VERSION "HNNBNNNYNNNNNNNNNNNNNNNNNNNNNNNNNNNNNNNNNN/4/%%%/4/'%**4NNN///"

NS_ :

BS_:

BU_: BAP_Tester BCM Gateway_Max TSGGen3_BFS TSGGen3_FS TSGGen3_HBFS TSGGen3_HFS WLC_01_CFD

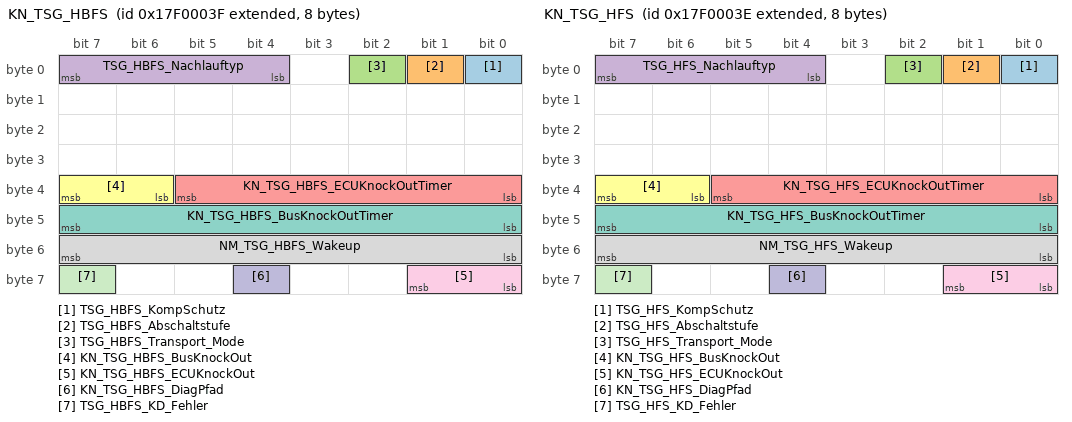
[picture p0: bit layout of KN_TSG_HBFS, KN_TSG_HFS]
BO_ 2549088319 KN_TSG_HBFS: 8 TSGGen3_HBFS
 SG_ TSG_HBFS_KompSchutz : 0|1@1+ (1.0,0.0) [0.0|1] ""  Vector__XXX
 SG_ TSG_HBFS_Abschaltstufe : 1|1@1+ (1.0,0.0) [0.0|1] ""  Vector__XXX
 SG_ TSG_HBFS_Transport_Mode : 2|1@1+ (1.0,0.0) [0.0|1] ""  Vector__XXX
 SG_ TSG_HBFS_Nachlauftyp : 4|4@1+ (1.0,0.0) [0.0|15] ""  Gateway_Max
 SG_ KN_TSG_HBFS_ECUKnockOutTimer : 32|6@1+ (1,0) [0|62] ""  Vector__XXX
 SG_ KN_TSG_HBFS_BusKnockOut : 38|2@1+ (1.0,0.0) [0.0|3] ""  Vector__XXX
 SG_ KN_TSG_HBFS_BusKnockOutTimer : 40|8@1+ (1,0) [0|254] ""  Vector__XXX
 SG_ NM_TSG_HBFS_Wakeup : 48|8@1+ (1.0,0.0) [0.0|255] ""  Vector__XXX
 SG_ KN_TSG_HBFS_ECUKnockOut : 56|2@1+ (1.0,0.0) [0.0|3] ""  Vector__XXX
 SG_ KN_TSG_HBFS_DiagPfad : 60|1@1+ (1.0,0.0) [0.0|1] ""  Gateway_Max
 SG_ TSG_HBFS_KD_Fehler : 63|1@1+ (1.0,0.0) [0.0|1] ""  Gateway_Max

BO_ 2549088318 KN_TSG_HFS: 8 TSGGen3_HFS
 SG_ TSG_HFS_KompSchutz : 0|1@1+ (1.0,0.0) [0.0|1] ""  Vector__XXX
 SG_ TSG_HFS_Abschaltstufe : 1|1@1+ (1.0,0.0) [0.0|1] ""  Vector__XXX
 SG_ TSG_HFS_Transport_Mode : 2|1@1+ (1.0,0.0) [0.0|1] ""  Vector__XXX
 SG_ TSG_HFS_Nachlauftyp : 4|4@1+ (1.0,0.0) [0.0|15] ""  Gateway_Max
 SG_ KN_TSG_HFS_ECUKnockOutTimer : 32|6@1+ (1,0) [0|62] ""  Vector__XXX
 SG_ KN_TSG_HFS_BusKnockOut : 38|2@1+ (1.0,0.0) [0.0|3] ""  Vector__XXX
 SG_ KN_TSG_HFS_BusKnockOutTimer : 40|8@1+ (1,0) [0|254] ""  Vector__XXX
 SG_ NM_TSG_HFS_Wakeup : 48|8@1+ (1.0,0.0) [0.0|255] ""  Vector__XXX
 SG_ KN_TSG_HFS_ECUKnockOut : 56|2@1+ (1.0,0.0) [0.0|3] ""  Vector__XXX
 SG_ KN_TSG_HFS_DiagPfad : 60|1@1+ (1.0,0.0) [0.0|1] ""  Gateway_Max
 SG_ TSG_HFS_KD_Fehler : 63|1@1+ (1.0,0.0) [0.0|1] ""  Gateway_Max

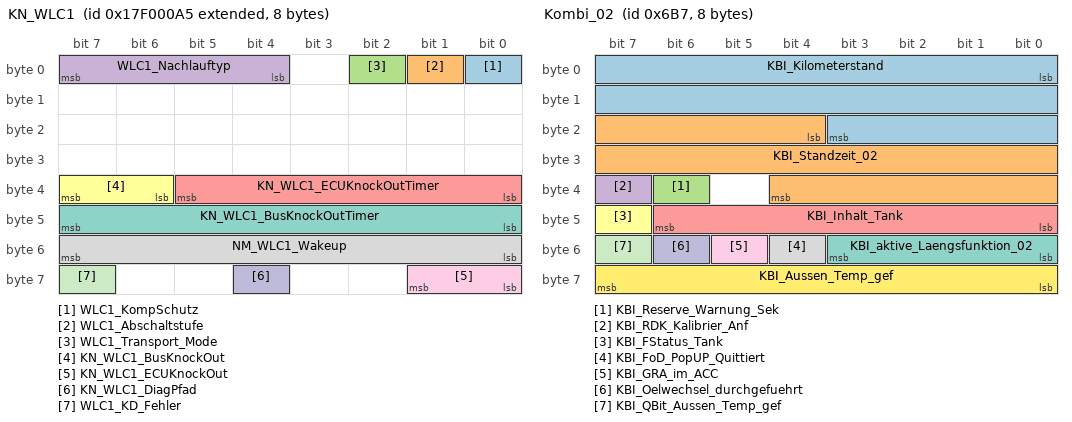
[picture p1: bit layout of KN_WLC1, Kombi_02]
BO_ 2549088421 KN_WLC1: 8 WLC_01_CFD
 SG_ WLC1_KompSchutz : 0|1@1+ (1.0,0.0) [0.0|1] ""  Vector__XXX
 SG_ WLC1_Abschaltstufe : 1|1@1+ (1.0,0.0) [0.0|1] ""  Vector__XXX
 SG_ WLC1_Transport_Mode : 2|1@1+ (1.0,0.0) [0.0|1] ""  Vector__XXX
 SG_ WLC1_Nachlauftyp : 4|4@1+ (1.0,0.0) [0.0|15] ""  Gateway_Max
 SG_ KN_WLC1_ECUKnockOutTimer : 32|6@1+ (1,0) [0|62] "Unit_Minut"  Vector__XXX
 SG_ KN_WLC1_BusKnockOut : 38|2@1+ (1.0,0.0) [0.0|3] ""  Vector__XXX
 SG_ KN_WLC1_BusKnockOutTimer : 40|8@1+ (1,0) [0|254] "Unit_Minut"  Vector__XXX
 SG_ NM_WLC1_Wakeup : 48|8@1+ (1.0,0.0) [0.0|255] ""  Vector__XXX
 SG_ KN_WLC1_ECUKnockOut : 56|2@1+ (1.0,0.0) [0.0|3] ""  Vector__XXX
 SG_ KN_WLC1_DiagPfad : 60|1@1+ (1.0,0.0) [0.0|1] ""  Gateway_Max
 SG_ WLC1_KD_Fehler : 63|1@1+ (1.0,0.0) [0.0|1] ""  Gateway_Max

BO_ 779 Kombi_01: 8 Gateway_Max
 SG_ KBI_ABS_Lampe : 0|1@1+ (1.0,0.0) [0.0|1] ""  BCM
 SG_ KBI_ESP_Lampe : 1|1@1+ (1.0,0.0) [0.0|1] ""  BCM
 SG_ KBI_BKL_Lampe : 2|1@1+ (1.0,0.0) [0.0|1] ""  BCM
 SG_ KBI_Airbag_Lampe : 3|1@1+ (1.0,0.0) [0.0|1] ""  BCM
 SG_ KBI_SILA_gueltig : 4|1@1+ (1.0,0.0) [0.0|1] ""  BCM
 SG_ KBI_Lenkung_Lampe : 5|1@1+ (1,0) [0|1] ""  BCM
 SG_ KBI_Vorglueh_System_Lampe : 6|1@1+ (1.0,0.0) [0.0|1] ""  BCM
 SG_ KBI_NV_in_Anzeige : 7|1@1+ (1.0,0.0) [0.0|1] ""  BCM
 SG_ Kombi_01_BZ : 8|4@1+ (1,0) [0|15] ""  BCM
 SG_ KBI_Anzeigestatus_ACC : 12|1@1+ (1.0,0.0) [0.0|1] ""  BCM
 SG_ KBI_Anzeigestatus_GRA : 13|2@1+ (1.0,0.0) [0.0|3] ""  BCM
 SG_ KBI_Oeldruck_Schalter : 15|1@1+ (1.0,0.0) [0.0|1] ""  BCM
 SG_ KBI_Tankwarnung : 16|1@1+ (1.0,0.0) [0.0|1] ""  BCM
 SG_ KBI_MFA_v_Einheit_01 : 17|1@1+ (1.0,0.0) [0.0|1] ""  BCM
 SG_ KBI_im_Stellgliedtest : 18|1@1+ (1.0,0.0) [0.0|1] ""  BCM
 SG_ KBI_Anzeigefehler_LDW : 19|2@1+ (1.0,0.0) [0.0|3] ""  BCM
 SG_ KBI_Tankwarnung_ungueltig : 21|1@1+ (1.0,0.0) [0.0|1] ""  BCM
 SG_ KBI_Oeldruckwarnung : 22|1@1+ (1.0,0.0) [0.0|1] ""  BCM
 SG_ KBI_Handbremse : 23|1@1+ (1.0,0.0) [0.0|1] ""  BCM
 SG_ KBI_V_Digital : 24|9@1+ (1,0) [0|511] ""  BCM
 SG_ KBI_PLA_in_Anzeige : 33|1@1+ (1.0,0.0) [0.0|1] ""  BCM
 SG_ KBI_Anzeigefehler_NV : 34|1@1+ (1.0,0.0) [0.0|1] ""  BCM
 SG_ KBI_Anzeigestatus_LIM : 35|2@1+ (1.0,0.0) [0.0|3] ""  BCM
 SG_ KBI_ARA_in_Anzeige : 37|1@1+ (1.0,0.0) [0.0|1] ""  BCM
 SG_ KBI_Taster_Lift : 38|1@1+ (1.0,0.0) [0.0|1] ""  BCM
 SG_ KBI_Taster_Fahrwerk : 39|1@1+ (1.0,0.0) [0.0|1] ""  BCM
 SG_ KBI_Audioabsenkung_MIB : 40|2@1+ (1.0,0.0) [0.0|3] ""  BCM
 SG_ KBI_Bestaetigung_ESP_Off : 42|2@1+ (1.0,0.0) [0.0|3] ""  BCM
 SG_ KBI_Anzeigestatus_RHP : 44|2@1+ (1.0,0.0) [0.0|3] ""  BCM
 SG_ KBI_angez_Geschw : 48|10@1+ (0.32,0) [0.00|325.12] "Unit_KiloMeterPerHour"  BCM
 SG_ KBI_Konsistenz_ACC : 59|1@1+ (1.0,0.0) [0.0|1] ""  BCM
 SG_ KBI_Fehler_Anzeige_ACC : 60|1@1+ (1.0,0.0) [0.0|1] ""  BCM
 SG_ KBI_Anzeigefehler_SWA : 61|2@1+ (1.0,0.0) [0.0|3] ""  BCM
 SG_ KBI_Systemstatus : 63|1@1+ (1.0,0.0) [0.0|1] ""  BCM

BO_ 1719 Kombi_02: 8 Gateway_Max
 SG_ KBI_Kilometerstand : 0|20@1+ (1,0) [0|1048573] "Unit_KiloMeter"  BCM
 SG_ KBI_Standzeit_02 : 20|17@1+ (1,0) [0|131068] "Unit_Secon"  BCM
 SG_ KBI_Reserve_Warnung_Sek : 38|1@1+ (1.0,0.0) [0.0|1] ""  BCM
 SG_ KBI_RDK_Kalibrier_Anf : 39|1@1+ (1.0,0.0) [0.0|1] ""  BCM
 SG_ KBI_Inhalt_Tank : 40|7@1+ (1,0) [0|125] "Unit_Liter"  BCM
 SG_ KBI_FStatus_Tank : 47|1@1+ (1.0,0.0) [0.0|1] ""  BCM
 SG_ KBI_aktive_Laengsfunktion_02 : 48|4@1+ (1.0,0.0) [0.0|15] ""  BCM
 SG_ KBI_FoD_PopUP_Quittiert : 52|1@1+ (1.0,0.0) [0.0|1] ""  BCM
 SG_ KBI_GRA_im_ACC : 53|1@1+ (1.0,0.0) [0.0|1] ""  BCM
 SG_ KBI_Oelwechsel_durchgefuehrt : 54|1@1+ (1.0,0.0) [0.0|1] ""  BCM
 SG_ KBI_QBit_Aussen_Temp_gef : 55|1@1+ (1.0,0.0) [0.0|1] ""  BCM,TSGGen3_BFS,TSGGen3_FS,TSGGen3_HBFS,TSGGen3_HFS
 SG_ KBI_Aussen_Temp_gef : 56|8@1+ (0.5,-50) [-50.0|75.0] "Unit_DegreCelsi"  BCM,TSGGen3_BFS,TSGGen3_FS,TSGGen3_HBFS,TSGGen3_HFS

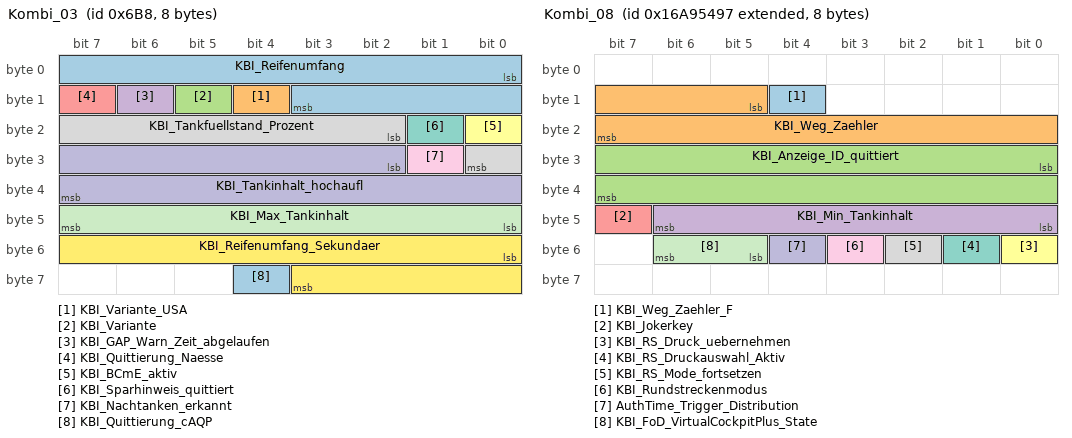
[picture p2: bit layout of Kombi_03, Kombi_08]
BO_ 1720 Kombi_03: 8 Gateway_Max
 SG_ KBI_Reifenumfang : 0|12@1+ (1,0) [0|4095] "Unit_MilliMeter"  BCM
 SG_ KBI_Variante_USA : 12|1@1+ (1.0,0.0) [0.0|1] ""  Vector__XXX
 SG_ KBI_Variante : 13|1@1+ (1.0,0.0) [0.0|1] ""  Vector__XXX
 SG_ KBI_GAP_Warn_Zeit_abgelaufen : 14|1@1+ (1.0,0.0) [0.0|1] ""  Vector__XXX
 SG_ KBI_Quittierung_Naesse : 15|1@1+ (1.0,0.0) [0.0|1] ""  Vector__XXX
 SG_ KBI_BCmE_aktiv : 16|1@1+ (1.0,0.0) [0.0|1] ""  Vector__XXX
 SG_ KBI_Sparhinweis_quittiert : 17|1@1+ (1.0,0.0) [0.0|1] ""  Vector__XXX
 SG_ KBI_Tankfuellstand_Prozent : 18|7@1+ (1,0) [0|100] "Unit_PerCent"  Vector__XXX
 SG_ KBI_Nachtanken_erkannt : 25|1@1+ (1.0,0.0) [0.0|1] ""  Vector__XXX
 SG_ KBI_Tankinhalt_hochaufl : 26|14@1+ (0.01,0) [0.00|163.81] "Unit_Liter"  Vector__XXX
 SG_ KBI_Max_Tankinhalt : 40|8@1+ (0.5,0) [0.0|126.5] ""  Vector__XXX
 SG_ KBI_Reifenumfang_Sekundaer : 48|12@1+ (1,0) [0|4095] "Unit_MilliMeter"  Vector__XXX
 SG_ KBI_Quittierung_cAQP : 60|1@1+ (1.0,0.0) [0.0|1] ""  Vector__XXX

BO_ 1722 Kombi_03_SOK_Signatur: 8 Gateway_Max
 SG_ SOK_Kombi_03_Signatur : 0|64@1+ (1,0) [0|18446744073709551615] "Unit_None"  BCM

BO_ 2527679639 Kombi_08: 8 Gateway_Max
 SG_ KBI_Weg_Zaehler_F : 12|1@1+ (1.0,0.0) [0.0|1] ""  BCM
 SG_ KBI_Weg_Zaehler : 13|11@1+ (1,0) [0|2047] "Unit_Meter"  BCM
 SG_ KBI_Anzeige_ID_quittiert : 24|16@1+ (1,0) [1|65336] "Unit_None"  BCM
 SG_ KBI_Min_Tankinhalt : 40|7@1+ (0.1,0) [0.0|12.5] "Unit_Liter"  BCM
 SG_ KBI_Jokerkey : 47|1@1+ (1.0,0.0) [0.0|1] ""  BCM
 SG_ KBI_RS_Druck_uebernehmen : 48|1@1+ (1.0,0.0) [0.0|1] ""  BCM
 SG_ KBI_RS_Druckauswahl_Aktiv : 49|1@1+ (1.0,0.0) [0.0|1] ""  BCM
 SG_ KBI_RS_Mode_fortsetzen : 50|1@1+ (1.0,0.0) [0.0|1] ""  BCM
 SG_ KBI_Rundstreckenmodus : 51|1@1+ (1.0,0.0) [0.0|1] ""  BCM
 SG_ AuthTime_Trigger_Distribution : 52|1@1+ (1.0,0.0) [0.0|1] ""  BCM
 SG_ KBI_FoD_VirtualCockpitPlus_State : 53|2@1+ (1.0,0.0) [0.0|3] ""  BCM

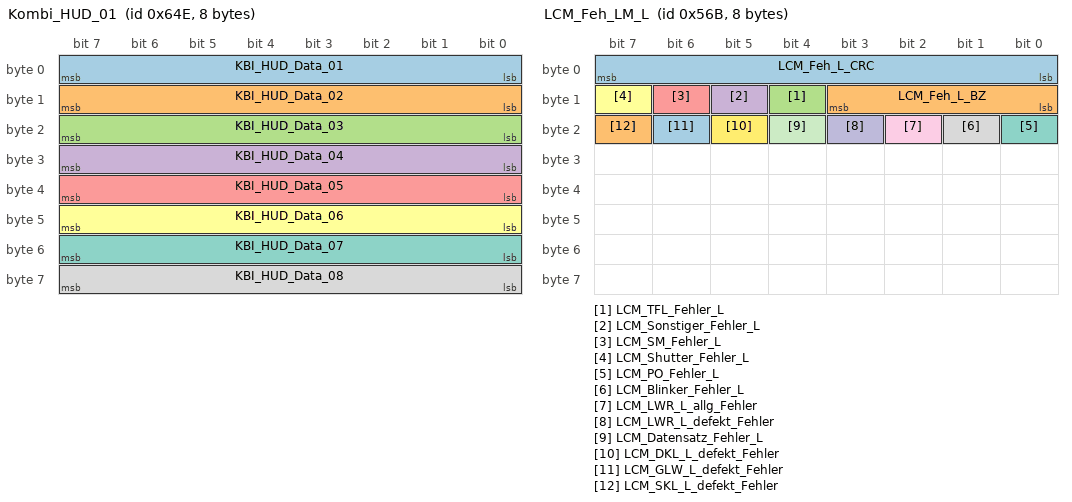
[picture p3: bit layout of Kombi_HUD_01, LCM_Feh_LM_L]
BO_ 1614 Kombi_HUD_01: 8 Gateway_Max
 SG_ KBI_HUD_Data_01 : 0|8@1+ (1.0,0.0) [0.0|255] ""  BCM
 SG_ KBI_HUD_Data_02 : 8|8@1+ (1.0,0.0) [0.0|255] ""  BCM
 SG_ KBI_HUD_Data_03 : 16|8@1+ (1.0,0.0) [0.0|255] ""  BCM
 SG_ KBI_HUD_Data_04 : 24|8@1+ (1.0,0.0) [0.0|255] ""  BCM
 SG_ KBI_HUD_Data_05 : 32|8@1+ (1.0,0.0) [0.0|255] ""  BCM
 SG_ KBI_HUD_Data_06 : 40|8@1+ (1.0,0.0) [0.0|255] ""  BCM
 SG_ KBI_HUD_Data_07 : 48|8@1+ (1.0,0.0) [0.0|255] ""  BCM
 SG_ KBI_HUD_Data_08 : 56|8@1+ (1.0,0.0) [0.0|255] ""  BCM

BO_ 2621440270 KS_BCM1_Req_FD: 16 Gateway_Max
 SG_ KS_BCM1_Req_FD_Data : 0|128@1+ (1.0,0.0) [0.0|340282366920938463463374607431768211455] ""  BCM

BO_ 2621571342 KS_BCM1_Resp_FD: 16 BCM
 SG_ KS_BCM1_Resp_FD_Data : 0|128@1+ (1.0,0.0) [0.0|340282366920938463463374607431768211455] ""  Gateway_Max

BO_ 1387 LCM_Feh_LM_L: 8 Gateway_Max
 SG_ LCM_Feh_L_CRC : 0|8@1+ (1,0) [0|255] ""  Vector__XXX
 SG_ LCM_Feh_L_BZ : 8|4@1+ (1,0) [0|15] ""  Vector__XXX
 SG_ LCM_TFL_Fehler_L : 12|1@1+ (1.0,0.0) [0.0|1] ""  BCM
 SG_ LCM_Sonstiger_Fehler_L : 13|1@1+ (1.0,0.0) [0.0|1] ""  BCM
 SG_ LCM_SM_Fehler_L : 14|1@1+ (1.0,0.0) [0.0|1] ""  BCM
 SG_ LCM_Shutter_Fehler_L : 15|1@1+ (1.0,0.0) [0.0|1] ""  BCM
 SG_ LCM_PO_Fehler_L : 16|1@1+ (1.0,0.0) [0.0|1] ""  BCM
 SG_ LCM_Blinker_Fehler_L : 17|1@1+ (1.0,0.0) [0.0|1] ""  BCM
 SG_ LCM_LWR_L_allg_Fehler : 18|1@1+ (1.0,0.0) [0.0|1] ""  BCM
 SG_ LCM_LWR_L_defekt_Fehler : 19|1@1+ (1.0,0.0) [0.0|1] ""  BCM
 SG_ LCM_Datensatz_Fehler_L : 20|1@1+ (1.0,0.0) [0.0|1] ""  BCM
 SG_ LCM_DKL_L_defekt_Fehler : 21|1@1+ (1.0,0.0) [0.0|1] ""  BCM
 SG_ LCM_GLW_L_defekt_Fehler : 22|1@1+ (1.0,0.0) [0.0|1] ""  BCM
 SG_ LCM_SKL_L_defekt_Fehler : 23|1@1+ (1.0,0.0) [0.0|1] ""  BCM

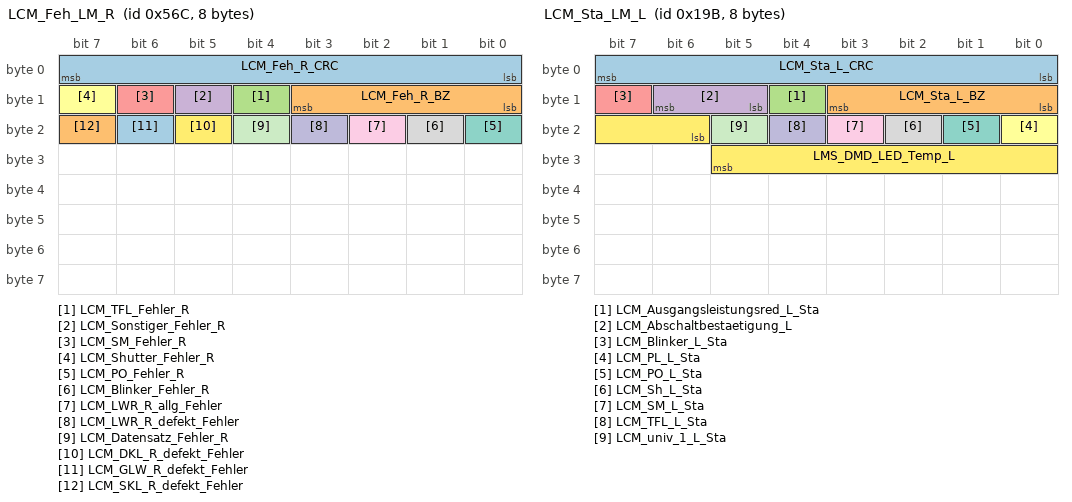
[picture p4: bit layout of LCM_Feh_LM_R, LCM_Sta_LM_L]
BO_ 1388 LCM_Feh_LM_R: 8 Gateway_Max
 SG_ LCM_Feh_R_CRC : 0|8@1+ (1,0) [0|255] ""  Vector__XXX
 SG_ LCM_Feh_R_BZ : 8|4@1+ (1,0) [0|15] ""  Vector__XXX
 SG_ LCM_TFL_Fehler_R : 12|1@1+ (1.0,0.0) [0.0|1] ""  BCM
 SG_ LCM_Sonstiger_Fehler_R : 13|1@1+ (1.0,0.0) [0.0|1] ""  BCM
 SG_ LCM_SM_Fehler_R : 14|1@1+ (1.0,0.0) [0.0|1] ""  BCM
 SG_ LCM_Shutter_Fehler_R : 15|1@1+ (1.0,0.0) [0.0|1] ""  BCM
 SG_ LCM_PO_Fehler_R : 16|1@1+ (1.0,0.0) [0.0|1] ""  BCM
 SG_ LCM_Blinker_Fehler_R : 17|1@1+ (1.0,0.0) [0.0|1] ""  BCM
 SG_ LCM_LWR_R_allg_Fehler : 18|1@1+ (1.0,0.0) [0.0|1] ""  BCM
 SG_ LCM_LWR_R_defekt_Fehler : 19|1@1+ (1.0,0.0) [0.0|1] ""  BCM
 SG_ LCM_Datensatz_Fehler_R : 20|1@1+ (1.0,0.0) [0.0|1] ""  BCM
 SG_ LCM_DKL_R_defekt_Fehler : 21|1@1+ (1.0,0.0) [0.0|1] ""  BCM
 SG_ LCM_GLW_R_defekt_Fehler : 22|1@1+ (1.0,0.0) [0.0|1] ""  BCM
 SG_ LCM_SKL_R_defekt_Fehler : 23|1@1+ (1.0,0.0) [0.0|1] ""  BCM

BO_ 403 LCM_Soll_Fkt: 8 BCM
 SG_ LCM_Soll_CRC : 0|8@1+ (1,0) [0|255] ""  Gateway_Max
 SG_ LCM_Soll_BZ : 8|4@1+ (1,0) [0|15] ""  Gateway_Max
 SG_ LCM_TFL_L_Anf : 12|1@1+ (1.0,0.0) [0.0|1] ""  Gateway_Max
 SG_ LCM_TFL_R_Anf : 13|1@1+ (1.0,0.0) [0.0|1] ""  Gateway_Max
 SG_ LCM_Abschaltung_Vbat_L_Anf : 14|1@1+ (1.0,0.0) [0.0|1] ""  Gateway_Max
 SG_ LCM_Abschaltung_Vbat_R_Anf : 15|1@1+ (1.0,0.0) [0.0|1] ""  Gateway_Max
 SG_ LCM_Blinker_L_Anf : 16|1@1+ (1.0,0.0) [0.0|1] ""  Gateway_Max
 SG_ LCM_Blinker_R_Anf : 17|1@1+ (1.0,0.0) [0.0|1] ""  Gateway_Max
 SG_ LCM_Blinkerzyklus_L : 18|1@1+ (1.0,0.0) [0.0|1] ""  Gateway_Max
 SG_ LCM_Blinkerzyklus_R : 19|1@1+ (1.0,0.0) [0.0|1] ""  Gateway_Max
 SG_ LCM_Sh_L_Anf : 20|1@1+ (1.0,0.0) [0.0|1] ""  Gateway_Max
 SG_ LCM_Sh_R_Anf : 21|1@1+ (1.0,0.0) [0.0|1] ""  Gateway_Max
 SG_ LCM_SM_L_Anf : 22|1@1+ (1.0,0.0) [0.0|1] ""  Gateway_Max
 SG_ LCM_SM_R_Anf : 23|1@1+ (1.0,0.0) [0.0|1] ""  Gateway_Max
 SG_ LCM_univ_1_L_Anf : 24|1@1+ (1.0,0.0) [0.0|1] ""  Gateway_Max
 SG_ LCM_univ_1_R_Anf : 25|1@1+ (1.0,0.0) [0.0|1] ""  Gateway_Max
 SG_ LCM_PO_L_Anf : 28|1@1+ (1.0,0.0) [0.0|1] ""  Gateway_Max
 SG_ LCM_PO_R_Anf : 29|1@1+ (1.0,0.0) [0.0|1] ""  Gateway_Max
 SG_ LCM_PL_L_Anf : 30|1@1+ (1.0,0.0) [0.0|1] ""  Gateway_Max
 SG_ LCM_PL_R_Anf : 31|1@1+ (1.0,0.0) [0.0|1] ""  Gateway_Max
 SG_ LCM_Leistungsreduzierung_Anf : 32|2@1+ (1.0,0.0) [0.0|3] ""  Gateway_Max
 SG_ BCM1_FoD_Sperrung_AnimTFL : 34|1@1+ (1.0,0.0) [0.0|1] ""  Gateway_Max
 SG_ LCM_Blinkerwischen_Anf : 35|1@1+ (1.0,0.0) [0.0|1] ""  Gateway_Max
 SG_ LCM_Animiertes_TFL_Anf : 36|1@1+ (1.0,0.0) [0.0|1] ""  Gateway_Max
 SG_ LCM_Signaturlicht_Anf : 39|1@1+ (1.0,0.0) [0.0|1] ""  Gateway_Max
 SG_ LCM_ECE_SAE_Umschaltung_Anf : 41|1@1+ (1.0,0.0) [0.0|1] ""  Gateway_Max
 SG_ BM_Autobahn : 42|1@1+ (1.0,0.0) [0.0|1] ""  Gateway_Max
 SG_ BM_ZV_auf : 43|1@1+ (1.0,0.0) [0.0|1] ""  Gateway_Max
 SG_ BM_ZV_zu : 44|1@1+ (1.0,0.0) [0.0|1] ""  Gateway_Max
 SG_ BCM1_CH_aktiv : 45|1@1+ (1.0,0.0) [0.0|1] ""  Gateway_Max
 SG_ BCM1_LH_aktiv : 46|1@1+ (1.0,0.0) [0.0|1] ""  Gateway_Max
 SG_ LCM_TFL_Signatur_Anf : 48|4@1+ (1.0,0.0) [0.0|15] ""  Gateway_Max
 SG_ LCM_Designlicht_4 : 52|1@1+ (1.0,0.0) [0.0|1] ""  Gateway_Max
 SG_ LCM_Designlicht_5 : 53|1@1+ (1.0,0.0) [0.0|1] ""  Gateway_Max
 SG_ AMBEX_CH_aktiv : 54|1@1+ (1.0,0.0) [0.0|1] ""  Gateway_Max
 SG_ AMBEX_CH_Trigger : 55|1@1+ (1.0,0.0) [0.0|1] ""  Gateway_Max
 SG_ AMBEX_LH_aktiv : 56|1@1+ (1.0,0.0) [0.0|1] ""  Gateway_Max
 SG_ AMBEX_LH_Trigger : 57|1@1+ (1.0,0.0) [0.0|1] ""  Gateway_Max

BO_ 411 LCM_Sta_LM_L: 8 Gateway_Max
 SG_ LCM_Sta_L_CRC : 0|8@1+ (1,0) [0|255] ""  BCM
 SG_ LCM_Sta_L_BZ : 8|4@1+ (1,0) [0|15] ""  BCM
 SG_ LCM_Ausgangsleistungsred_L_Sta : 12|1@1+ (1.0,0.0) [0.0|1] ""  BCM
 SG_ LCM_Abschaltbestaetigung_L : 13|2@1+ (1.0,0.0) [0.0|3] ""  BCM
 SG_ LCM_Blinker_L_Sta : 15|1@1+ (1.0,0.0) [0.0|1] ""  BCM
 SG_ LCM_PL_L_Sta : 16|1@1+ (1.0,0.0) [0.0|1] ""  BCM
 SG_ LCM_PO_L_Sta : 17|1@1+ (1.0,0.0) [0.0|1] ""  BCM
 SG_ LCM_Sh_L_Sta : 18|1@1+ (1.0,0.0) [0.0|1] ""  BCM
 SG_ LCM_SM_L_Sta : 19|1@1+ (1.0,0.0) [0.0|1] ""  BCM
 SG_ LCM_TFL_L_Sta : 20|1@1+ (1.0,0.0) [0.0|1] ""  BCM
 SG_ LCM_univ_1_L_Sta : 21|1@1+ (1.0,0.0) [0.0|1] ""  BCM
 SG_ LMS_DMD_LED_Temp_L : 22|8@1+ (1,-50) [-50|204] "Unit_DegreCelsi"  BCM

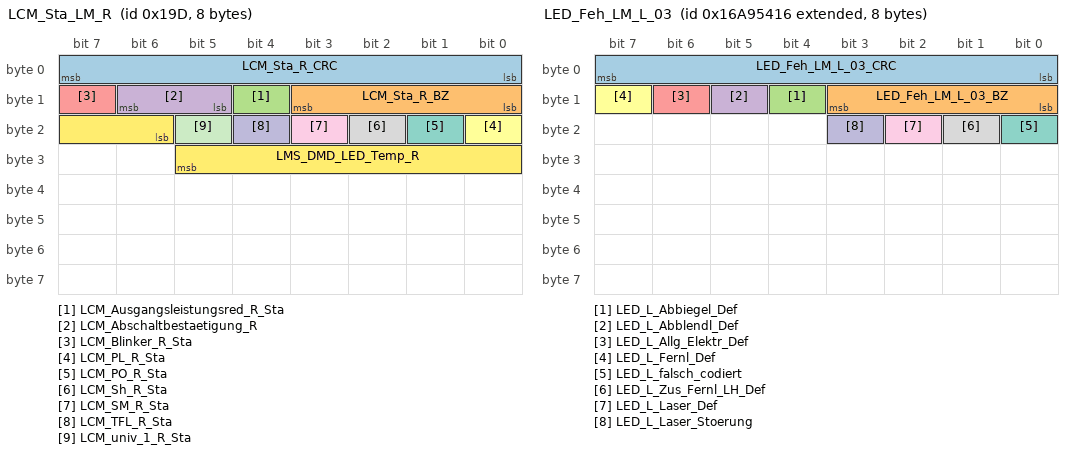
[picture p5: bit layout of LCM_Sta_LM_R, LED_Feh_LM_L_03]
BO_ 413 LCM_Sta_LM_R: 8 Gateway_Max
 SG_ LCM_Sta_R_CRC : 0|8@1+ (1,0) [0|255] ""  BCM
 SG_ LCM_Sta_R_BZ : 8|4@1+ (1,0) [0|15] ""  BCM
 SG_ LCM_Ausgangsleistungsred_R_Sta : 12|1@1+ (1.0,0.0) [0.0|1] ""  BCM
 SG_ LCM_Abschaltbestaetigung_R : 13|2@1+ (1.0,0.0) [0.0|3] ""  BCM
 SG_ LCM_Blinker_R_Sta : 15|1@1+ (1.0,0.0) [0.0|1] ""  BCM
 SG_ LCM_PL_R_Sta : 16|1@1+ (1.0,0.0) [0.0|1] ""  BCM
 SG_ LCM_PO_R_Sta : 17|1@1+ (1.0,0.0) [0.0|1] ""  BCM
 SG_ LCM_Sh_R_Sta : 18|1@1+ (1.0,0.0) [0.0|1] ""  BCM
 SG_ LCM_SM_R_Sta : 19|1@1+ (1.0,0.0) [0.0|1] ""  BCM
 SG_ LCM_TFL_R_Sta : 20|1@1+ (1.0,0.0) [0.0|1] ""  BCM
 SG_ LCM_univ_1_R_Sta : 21|1@1+ (1.0,0.0) [0.0|1] ""  BCM
 SG_ LMS_DMD_LED_Temp_R : 22|8@1+ (1,-50) [-50|204] "Unit_DegreCelsi"  BCM

BO_ 2527679510 LED_Feh_LM_L_03: 8 Gateway_Max
 SG_ LED_Feh_LM_L_03_CRC : 0|8@1+ (1,0) [0|255] ""  Vector__XXX
 SG_ LED_Feh_LM_L_03_BZ : 8|4@1+ (1,0) [0|15] ""  Vector__XXX
 SG_ LED_L_Abbiegel_Def : 12|1@1+ (1.0,0.0) [0.0|1] ""  BCM
 SG_ LED_L_Abblendl_Def : 13|1@1+ (1.0,0.0) [0.0|1] ""  BCM
 SG_ LED_L_Allg_Elektr_Def : 14|1@1+ (1.0,0.0) [0.0|1] ""  BCM
 SG_ LED_L_Fernl_Def : 15|1@1+ (1.0,0.0) [0.0|1] ""  BCM
 SG_ LED_L_falsch_codiert : 16|1@1+ (1,0) [0|1] ""  BCM
 SG_ LED_L_Zus_Fernl_LH_Def : 17|1@1+ (1.0,0.0) [0.0|1] ""  BCM
 SG_ LED_L_Laser_Def : 18|1@1+ (1.0,0.0) [0.0|1] ""  BCM
 SG_ LED_L_Laser_Stoerung : 19|1@1+ (1.0,0.0) [0.0|1] ""  Vector__XXX

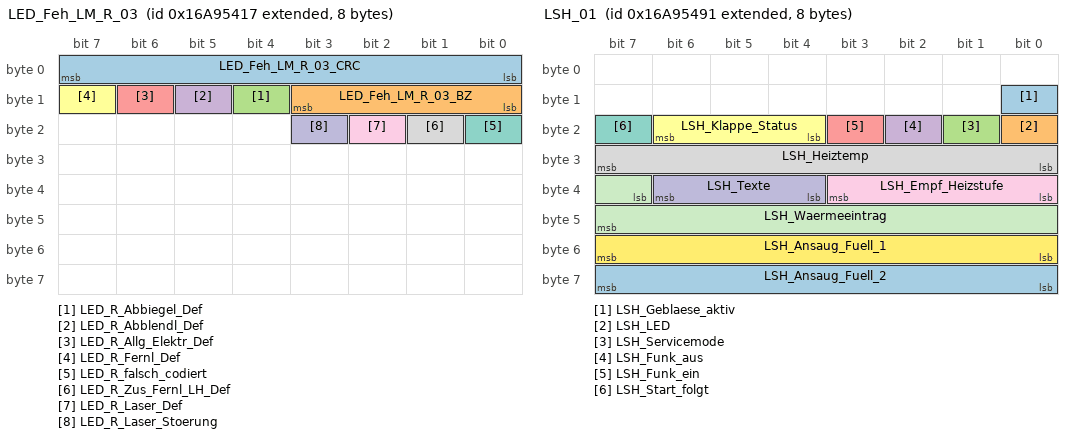
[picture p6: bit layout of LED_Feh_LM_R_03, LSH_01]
BO_ 2527679511 LED_Feh_LM_R_03: 8 Gateway_Max
 SG_ LED_Feh_LM_R_03_CRC : 0|8@1+ (1,0) [0|255] ""  Vector__XXX
 SG_ LED_Feh_LM_R_03_BZ : 8|4@1+ (1,0) [0|15] ""  Vector__XXX
 SG_ LED_R_Abbiegel_Def : 12|1@1+ (1.0,0.0) [0.0|1] ""  BCM
 SG_ LED_R_Abblendl_Def : 13|1@1+ (1.0,0.0) [0.0|1] ""  BCM
 SG_ LED_R_Allg_Elektr_Def : 14|1@1+ (1.0,0.0) [0.0|1] ""  BCM
 SG_ LED_R_Fernl_Def : 15|1@1+ (1.0,0.0) [0.0|1] ""  BCM
 SG_ LED_R_falsch_codiert : 16|1@1+ (1,0) [0|1] ""  BCM
 SG_ LED_R_Zus_Fernl_LH_Def : 17|1@1+ (1.0,0.0) [0.0|1] ""  BCM
 SG_ LED_R_Laser_Def : 18|1@1+ (1.0,0.0) [0.0|1] ""  BCM
 SG_ LED_R_Laser_Stoerung : 19|1@1+ (1.0,0.0) [0.0|1] ""  Vector__XXX

BO_ 981 Licht_Anf_01: 8 BCM
 SG_ Licht_Anf_01_CRC : 0|8@1+ (1,0) [0|255] ""  Gateway_Max
 SG_ Licht_Anf_01_BZ : 8|4@1+ (1,0) [0|15] ""  Gateway_Max
 SG_ BCM1_Kurvenlicht_links_Anf : 12|1@1+ (1.0,0.0) [0.0|1] ""  Gateway_Max
 SG_ BCM1_Kurvenlicht_rechts_Anf : 13|1@1+ (1.0,0.0) [0.0|1] ""  Gateway_Max
 SG_ BCM1_Standlicht_Anf : 14|1@1+ (1.0,0.0) [0.0|1] ""  Gateway_Max
 SG_ BCM1_Abblendlicht_Anf : 15|1@1+ (1.0,0.0) [0.0|1] ""  Gateway_Max
 SG_ BCM1_Fernlicht_Anf : 16|1@1+ (1.0,0.0) [0.0|1] ""  Gateway_Max
 SG_ BCM1_Nebellicht_Anf : 17|1@1+ (1.0,0.0) [0.0|1] ""  Gateway_Max
 SG_ BCM1_Parklicht_li_Anf : 18|1@1+ (1.0,0.0) [0.0|1] ""  Gateway_Max
 SG_ BCM1_Parklicht_re_Anf : 19|1@1+ (1.0,0.0) [0.0|1] ""  Gateway_Max
 SG_ BCM1_Nebelschluss_Ahg_Anf : 20|1@1+ (1.0,0.0) [0.0|1] ""  Gateway_Max
 SG_ BCM1_Nebelschluss_Fzg_Anf : 21|1@1+ (1.0,0.0) [0.0|1] ""  Gateway_Max
 SG_ BCM1_Schlusslicht_Anf : 22|1@1+ (1.0,0.0) [0.0|1] ""  Gateway_Max
 SG_ BCM_Rueckfahrlicht_Anf : 23|1@1+ (1.0,0.0) [0.0|1] ""  Gateway_Max,TSGGen3_BFS,TSGGen3_FS,TSGGen3_HBFS,TSGGen3_HFS
 SG_ BCM1_Signaturlicht_Anf : 24|1@1+ (1.0,0.0) [0.0|1] ""  Gateway_Max
 SG_ BCM1_Umfeldleuchten_Anf : 25|1@1+ (1.0,0.0) [0.0|1] ""  Gateway_Max,TSGGen3_BFS,TSGGen3_FS,TSGGen3_HBFS,TSGGen3_HFS
 SG_ BCM1_Tagfahrlicht_Anf : 26|1@1+ (1.0,0.0) [0.0|1] ""  Gateway_Max
 SG_ BCM1_Regenlicht_Anf : 27|1@1+ (1.0,0.0) [0.0|1] ""  Gateway_Max
 SG_ BCM1_Autobahnlicht_Anf : 28|1@1+ (1.0,0.0) [0.0|1] ""  Gateway_Max
 SG_ BCM1_Touristen_Licht_Anf : 29|1@1+ (1.0,0.0) [0.0|1] ""  Gateway_Max
 SG_ BCM1_CH_aktiv : 30|1@1+ (1.0,0.0) [0.0|1] ""  Gateway_Max
 SG_ BCM1_LH_aktiv : 31|1@1+ (1.0,0.0) [0.0|1] ""  Gateway_Max,TSGGen3_BFS,TSGGen3_FS,TSGGen3_HBFS,TSGGen3_HFS
 SG_ BCM1_Gleitende_Leuchtw_Anf : 32|1@1+ (1.0,0.0) [0.0|1] ""  Gateway_Max
 SG_ BCM1_GLW_Fernlicht_Anf : 33|1@1+ (1.0,0.0) [0.0|1] ""  Gateway_Max
 SG_ BCM1_Adaptive_Lichtvert_Anf : 34|1@1+ (1.0,0.0) [0.0|1] ""  Gateway_Max
 SG_ BCM1_Animationssperrung : 39|1@1+ (1.0,0.0) [0.0|1] ""  Gateway_Max
 SG_ BCM1_CH_LH_aktiv : 40|1@1+ (1.0,0.0) [0.0|1] ""  Gateway_Max
 SG_ BCM1_Allwetterlicht_Anf : 41|1@1+ (1.0,0.0) [0.0|1] ""  Gateway_Max
 SG_ TFL_Matrix_Variante01_Anf : 42|1@1+ (1.0,0.0) [0.0|1] ""  Gateway_Max
 SG_ TFL_Matrix_Variante02_Anf : 43|1@1+ (1.0,0.0) [0.0|1] ""  Gateway_Max
 SG_ TFL_Matrix_Variante03_Anf : 44|1@1+ (1.0,0.0) [0.0|1] ""  Gateway_Max
 SG_ TFL_Matrix_Variante04_Anf : 45|1@1+ (1.0,0.0) [0.0|1] ""  Gateway_Max

BO_ 982 Licht_hinten_01: 8 BCM
 SG_ Licht_hinten_01_BZ : 0|4@1+ (1,0) [0|15] ""  Gateway_Max
 SG_ BCM2_Bremsl_durch_ECD_invers : 4|1@1+ (1.0,0.0) [0.0|1] ""  Gateway_Max
 SG_ BCM2_Bremsl_durch_ECD : 5|1@1+ (1.0,0.0) [0.0|1] ""  Gateway_Max
 SG_ LH_Aussenlicht_def : 7|1@1+ (1.0,0.0) [0.0|1] ""  Gateway_Max
 SG_ LH_Standlicht_H_aktiv : 8|1@1+ (1.0,0.0) [0.0|1] ""  Gateway_Max
 SG_ LH_Parklicht_HL_aktiv : 9|1@1+ (1.0,0.0) [0.0|1] ""  Gateway_Max
 SG_ LH_Parklicht_HR_aktiv : 10|1@1+ (1.0,0.0) [0.0|1] ""  Gateway_Max
 SG_ LH_Bremslicht_H_aktiv : 11|1@1+ (1.0,0.0) [0.0|1] ""  Gateway_Max
 SG_ LH_Nebelschluss_aktiv : 12|1@1+ (1.0,0.0) [0.0|1] ""  Gateway_Max
 SG_ LH_Rueckfahrlicht_aktiv : 13|1@1+ (1.0,0.0) [0.0|1] ""  Gateway_Max
 SG_ LH_Blinker_HL_akt : 14|1@1+ (1.0,0.0) [0.0|1] ""  Gateway_Max
 SG_ LH_Blinker_HR_akt : 15|1@1+ (1.0,0.0) [0.0|1] ""  Gateway_Max
 SG_ LH_Blinker_li_def : 16|1@1+ (1.0,0.0) [0.0|1] ""  Gateway_Max
 SG_ LH_Bremsl_li_def : 17|1@1+ (1.0,0.0) [0.0|1] ""  Gateway_Max
 SG_ LH_Schlusslicht_li_def : 18|1@1+ (1.0,0.0) [0.0|1] ""  Gateway_Max
 SG_ LH_Rueckf_li_def : 19|1@1+ (1.0,0.0) [0.0|1] ""  Gateway_Max
 SG_ LH_Nebel_li_def : 20|1@1+ (1.0,0.0) [0.0|1] ""  Gateway_Max
 SG_ LH_Schluss_Brems_Nebel_li_def : 21|1@1+ (1.0,0.0) [0.0|1] ""  Gateway_Max
 SG_ LH_Schluss_Brems_Nebel_re_def : 22|1@1+ (1.0,0.0) [0.0|1] ""  Gateway_Max
 SG_ LH_Zusatzschlussl_def : 23|1@1+ (1.0,0.0) [0.0|1] ""  Gateway_Max
 SG_ LH_Schluss_Brems_li_def : 24|1@1+ (1.0,0.0) [0.0|1] ""  Gateway_Max
 SG_ LH_Schluss_Nebel_li_def : 25|1@1+ (1.0,0.0) [0.0|1] ""  Gateway_Max
 SG_ LH_SL_BRL_BLK_li_def : 26|1@1+ (1.0,0.0) [0.0|1] ""  Gateway_Max
 SG_ LH_Brems_Blk_li_def : 27|1@1+ (1.0,0.0) [0.0|1] ""  Gateway_Max
 SG_ LH_Diag_Status_re_def : 28|1@1+ (1.0,0.0) [0.0|1] ""  Gateway_Max
 SG_ LH_Diag_Status_li_def : 29|1@1+ (1.0,0.0) [0.0|1] ""  Gateway_Max
 SG_ LH_Diag_LED_li_def : 30|1@1+ (1.0,0.0) [0.0|1] ""  Gateway_Max
 SG_ LH_Diag_LED_re_def : 31|1@1+ (1.0,0.0) [0.0|1] ""  Gateway_Max
 SG_ LH_Blinker_re_def : 32|1@1+ (1.0,0.0) [0.0|1] ""  Gateway_Max
 SG_ LH_Bremsl_re_def : 33|1@1+ (1.0,0.0) [0.0|1] ""  Gateway_Max
 SG_ LH_Schlusslicht_re_def : 34|1@1+ (1.0,0.0) [0.0|1] ""  Gateway_Max
 SG_ LH_Rueckf_re_def : 35|1@1+ (1.0,0.0) [0.0|1] ""  Gateway_Max
 SG_ LH_Nebel_re_def : 36|1@1+ (1.0,0.0) [0.0|1] ""  Gateway_Max
 SG_ LH_Schluss_Brems_re_def : 40|1@1+ (1.0,0.0) [0.0|1] ""  Gateway_Max
 SG_ LH_Schluss_Nebel_re_def : 41|1@1+ (1.0,0.0) [0.0|1] ""  Gateway_Max
 SG_ LH_SL_BRL_BLK_re_def : 42|1@1+ (1.0,0.0) [0.0|1] ""  Gateway_Max
 SG_ LH_Brems_Blk_re_def : 43|1@1+ (1.0,0.0) [0.0|1] ""  Gateway_Max
 SG_ LH_Kennzl_def : 48|1@1+ (1.0,0.0) [0.0|1] ""  Gateway_Max
 SG_ LH_3_Bremsl_def : 49|1@1+ (1.0,0.0) [0.0|1] ""  Gateway_Max
 SG_ LH_Nebel_mi_def : 50|1@1+ (1.0,0.0) [0.0|1] ""  Gateway_Max
 SG_ LH_Rueckf_mi_def : 51|1@1+ (1.0,0.0) [0.0|1] ""  Gateway_Max
 SG_ LH_Bremsl_li_ges_def : 54|1@1+ (1.0,0.0) [0.0|1] ""  Gateway_Max
 SG_ LH_Bremsl_re_ges_def : 55|1@1+ (1.0,0.0) [0.0|1] ""  Gateway_Max

BO_ 1624 Licht_vorne_01: 8 BCM
 SG_ Licht_Vorne_01_CRC : 0|8@1+ (1,0) [0|255] ""  Gateway_Max
 SG_ Licht_Vorne_01_BZ : 8|4@1+ (1,0) [0|15] ""  Gateway_Max
 SG_ LV_Standlicht_Anzeige : 12|1@1+ (1.0,0.0) [0.0|1] ""  Gateway_Max
 SG_ LV_Abblendlicht_Anzeige : 13|1@1+ (1.0,0.0) [0.0|1] ""  Gateway_Max
 SG_ LV_Fernlicht_Anzeige : 14|1@1+ (1.0,0.0) [0.0|1] ""  Gateway_Max
 SG_ LV_Nebellicht_Anzeige : 15|1@1+ (1.0,0.0) [0.0|1] ""  Gateway_Max
 SG_ LV_Nebelschlusslicht_Anzeige : 16|1@1+ (1.0,0.0) [0.0|1] ""  Gateway_Max
 SG_ LV_Tagfahrlicht_Anzeige : 17|1@1+ (1.0,0.0) [0.0|1] ""  Gateway_Max
 SG_ LV_AFL_aktiv_Anzeige : 18|1@1+ (1.0,0.0) [0.0|1] ""  Gateway_Max
 SG_ LV_AFL_defekt : 19|1@1+ (1.0,0.0) [0.0|1] ""  Gateway_Max
 SG_ LV_Blinker_li_def : 20|1@1+ (1.0,0.0) [0.0|1] ""  Gateway_Max
 SG_ LV_Standlicht_li_def : 21|1@1+ (1.0,0.0) [0.0|1] ""  Gateway_Max
 SG_ LV_Abblendlicht_li_def : 22|1@1+ (1.0,0.0) [0.0|1] ""  Gateway_Max
 SG_ LV_Fernlicht_li_def : 23|1@1+ (1.0,0.0) [0.0|1] ""  Gateway_Max
 SG_ LV_Nebellicht_li_def : 24|1@1+ (1.0,0.0) [0.0|1] ""  Gateway_Max
 SG_ LV_Blk_li_Seite_def : 25|1@1+ (1.0,0.0) [0.0|1] ""  Gateway_Max
 SG_ LV_Tagfahrlicht_li_def : 26|1@1+ (1.0,0.0) [0.0|1] ""  Gateway_Max
 SG_ LV_FLA_aktiv_Anzeige : 27|1@1+ (1.0,0.0) [0.0|1] ""  Gateway_Max
 SG_ LV_FLA_defekt : 28|1@1+ (1.0,0.0) [0.0|1] ""  Gateway_Max
 SG_ LV_FLA_Sensor_blockiert : 29|1@1+ (1.0,0.0) [0.0|1] ""  Gateway_Max
 SG_ LV_Blinker_re_def : 30|1@1+ (1.0,0.0) [0.0|1] ""  Gateway_Max
 SG_ LV_Standlicht_re_def : 31|1@1+ (1.0,0.0) [0.0|1] ""  Gateway_Max
 SG_ LV_Abblendlicht_re_def : 32|1@1+ (1.0,0.0) [0.0|1] ""  Gateway_Max
 SG_ LV_Fernlicht_re_def : 33|1@1+ (1.0,0.0) [0.0|1] ""  Gateway_Max
 SG_ LV_Nebellicht_re_def : 34|1@1+ (1.0,0.0) [0.0|1] ""  Gateway_Max
 SG_ LV_Blk_re_Seite_def : 35|1@1+ (1.0,0.0) [0.0|1] ""  Gateway_Max
 SG_ LV_Tagfahrlicht_re_def : 36|1@1+ (1.0,0.0) [0.0|1] ""  Gateway_Max
 SG_ LV_Aussenlicht_def : 37|1@1+ (1.0,0.0) [0.0|1] ""  Gateway_Max
 SG_ LV_Abblendlicht_TFL_li_def : 38|1@1+ (1.0,0.0) [0.0|1] ""  Gateway_Max
 SG_ LV_Nebellicht_TFL_li_def : 39|1@1+ (1.0,0.0) [0.0|1] ""  Gateway_Max
 SG_ LV_Standlicht_TFL_li_def : 40|1@1+ (1.0,0.0) [0.0|1] ""  Gateway_Max
 SG_ LV_Abblend_Fernlicht_li_def : 41|1@1+ (1.0,0.0) [0.0|1] ""  Gateway_Max
 SG_ LV_Abblendlicht_TFL_re_def : 42|1@1+ (1.0,0.0) [0.0|1] ""  Gateway_Max
 SG_ LV_Nebellicht_TFL_re_def : 43|1@1+ (1.0,0.0) [0.0|1] ""  Gateway_Max
 SG_ LV_Standlicht_TFL_re_def : 44|1@1+ (1.0,0.0) [0.0|1] ""  Gateway_Max
 SG_ LV_Abblend_Fernlicht_re_def : 45|1@1+ (1.0,0.0) [0.0|1] ""  Gateway_Max
 SG_ LV_Abbiegelicht_li_def : 46|1@1+ (1.0,0.0) [0.0|1] ""  Gateway_Max
 SG_ LV_Abbiegelicht_re_def : 47|1@1+ (1.0,0.0) [0.0|1] ""  Gateway_Max
 SG_ BCM1_Linksverkehr : 48|1@1+ (1.0,0.0) [0.0|1] ""  Gateway_Max
 SG_ BCM1_Licht_Dunkelheit_aktiv : 49|1@1+ (1.0,0.0) [0.0|1] ""  Gateway_Max
 SG_ LV_LED_Scheinwerfer_li_def : 50|1@1+ (1.0,0.0) [0.0|1] ""  Gateway_Max
 SG_ LV_LED_Scheinwerfer_re_def : 51|1@1+ (1.0,0.0) [0.0|1] ""  Gateway_Max
 SG_ LV_Blinker_VL_aktiv : 52|1@1+ (1.0,0.0) [0.0|1] ""  Gateway_Max
 SG_ LV_Blinker_VR_aktiv : 53|1@1+ (1.0,0.0) [0.0|1] ""  Gateway_Max
 SG_ LV_MXB_Status_Anzeige : 54|2@1+ (1.0,0.0) [0.0|3] ""  Gateway_Max

BO_ 2527679633 LSH_01: 8 Gateway_Max
 SG_ LSH_Geblaese_aktiv : 8|1@1+ (1.0,0.0) [0.0|1] ""  BCM
 SG_ LSH_LED : 16|1@1+ (1.0,0.0) [0.0|1] ""  Vector__XXX
 SG_ LSH_Servicemode : 17|1@1+ (1.0,0.0) [0.0|1] ""  Vector__XXX
 SG_ LSH_Funk_aus : 18|1@1+ (1.0,0.0) [0.0|1] ""  Vector__XXX
 SG_ LSH_Funk_ein : 19|1@1+ (1.0,0.0) [0.0|1] ""  Vector__XXX
 SG_ LSH_Klappe_Status : 20|3@1+ (1.0,0.0) [0.0|7] ""  Vector__XXX
 SG_ LSH_Start_folgt : 23|1@1+ (1.0,0.0) [0.0|1] ""  Vector__XXX
 SG_ LSH_Heiztemp : 24|8@1+ (2,-40) [-40|360] "Unit_DegreCelsi"  Vector__XXX
 SG_ LSH_Empf_Heizstufe : 32|4@1+ (1.0,0.0) [0.0|15] ""  Vector__XXX
 SG_ LSH_Texte : 36|3@1+ (1.0,0.0) [0.0|7] ""  Vector__XXX
 SG_ LSH_Waermeeintrag : 39|9@1+ (5,0) [0|2500] "Unit_Minut"  Vector__XXX
 SG_ LSH_Ansaug_Fuell_1 : 48|8@1+ (0.75,-40) [-40.00|142.25] "Unit_DegreCelsi"  Vector__XXX
 SG_ LSH_Ansaug_Fuell_2 : 56|8@1+ (0.75,-40) [-40.00|142.25] "Unit_DegreCelsi"  Vector__XXX

BO_ 917 LWR_AFS_01: 8 BCM
 SG_ AFS_Abbiegelicht_li_Anf : 0|1@1+ (1.0,0.0) [0.0|1] ""  BCM,Gateway_Max
 SG_ AFS_Abbiegelicht_re_Anf : 1|1@1+ (1.0,0.0) [0.0|1] ""  BCM,Gateway_Max
 SG_ AFS_Abbiegelicht_Dimm_Anf : 2|1@1+ (1.0,0.0) [0.0|1] ""  BCM,Gateway_Max
 SG_ AFS_Verfuegbarkeit_GLW : 3|1@1+ (1.0,0.0) [0.0|1] ""  BCM,Gateway_Max
 SG_ AFS_Status_adaptive_LV : 4|1@1+ (1.0,0.0) [0.0|1] ""  BCM,Gateway_Max
 SG_ AFS_Fernlicht_li_defekt : 5|1@1+ (1.0,0.0) [0.0|1] ""  BCM,Gateway_Max
 SG_ AFS_Fernlicht_re_defekt : 6|1@1+ (1.0,0.0) [0.0|1] ""  BCM,Gateway_Max
 SG_ AFS_Fernlicht_Status : 7|1@1+ (1.0,0.0) [0.0|1] ""  BCM,Gateway_Max
 SG_ LWR_AFS_01_BZ : 8|4@1+ (1,0) [0|15] ""  BCM,Gateway_Max
 SG_ AFS_Lampe : 12|1@1+ (1.0,0.0) [0.0|1] ""  BCM,Gateway_Max
 SG_ LWR_Lampe : 13|1@1+ (1.0,0.0) [0.0|1] ""  BCM,Gateway_Max
 SG_ AFS_Fehlertext : 14|1@1+ (1.0,0.0) [0.0|1] ""  BCM,Gateway_Max
 SG_ AFS_LED_Blinkmode : 15|1@1+ (1.0,0.0) [0.0|1] ""  BCM,Gateway_Max
 SG_ LWR_Touristenmodus_aktiv : 16|1@1+ (1.0,0.0) [0.0|1] ""  BCM,Gateway_Max
 SG_ AFS_Charisma_FahrPr : 17|4@1+ (1.0,0.0) [0.0|15] ""  BCM,Gateway_Max
 SG_ AFS_Charisma_Status : 21|2@1+ (1.0,0.0) [0.0|3] ""  BCM,Gateway_Max
 SG_ AFS_Allwetterlicht : 24|1@1+ (1.0,0.0) [0.0|1] ""  BCM,Gateway_Max
 SG_ LWR_Touristenmodus_verbaut : 25|1@1+ (1.0,0.0) [0.0|1] ""  BCM,Gateway_Max
 SG_ AFS_adaptive_LV_verbaut : 26|1@1+ (1.0,0.0) [0.0|1] ""  BCM,Gateway_Max
 SG_ LWR_Reisemodus_Texte : 27|2@1+ (1.0,0.0) [0.0|3] ""  BCM,Gateway_Max
 SG_ GLW_Sensor_blockiert : 29|1@1+ (1.0,0.0) [0.0|1] ""  BCM,Gateway_Max
 SG_ LWR_Pos_Schrittmotor : 32|8@1+ (0.4,0) [0.0|100.0] "Unit_PerCent"  BCM,Gateway_Max
 SG_ LWR_Hoehenwert_VL : 40|8@1+ (1,-127) [-127|126] ""  BCM,Gateway_Max
 SG_ LWR_Hoehenwert_HL : 48|8@1+ (1,-127) [-127|126] ""  BCM,Gateway_Max
 SG_ AFS_Ersatzlicht_Links : 56|1@1+ (1.0,0.0) [0.0|1] ""  BCM,Gateway_Max
 SG_ AFS_Ersatzlicht_Rechts : 57|1@1+ (1.0,0.0) [0.0|1] ""  BCM,Gateway_Max
 SG_ LWR_AFS_Grundeinstellung : 58|1@1+ (1.0,0.0) [0.0|1] ""  BCM,Gateway_Max
 SG_ LWR_AFS_Parametrisierung : 59|1@1+ (1.0,0.0) [0.0|1] ""  BCM,Gateway_Max
 SG_ LWR_Initialisierungslauf : 60|1@1+ (1.0,0.0) [0.0|1] ""  BCM,Gateway_Max
 SG_ LWR_Sicherheitsposition : 61|1@1+ (1.0,0.0) [0.0|1] ""  BCM,Gateway_Max
 SG_ LWR_Modus : 62|1@1+ (1.0,0.0) [0.0|1] ""  BCM,Gateway_Max

BO_ 1153 MainUnit_01: 8 Gateway_Max
 SG_ ZR_LoGeWa_Event_Kombiwarnung : 0|4@1+ (1.0,0.0) [0.0|15] ""  Vector__XXX
 SG_ Nav_FoD_Status : 4|3@1+ (1.0,0.0) [0.0|7] ""  Vector__XXX
 SG_ MIB_ASW_Diagnose : 7|1@1+ (1.0,0.0) [0.0|1] ""  Vector__XXX
 SG_ ZR_Lichter_Tag : 8|1@1+ (1.0,0.0) [0.0|1] ""  BCM
 SG_ MIB_Tongenerator_PH_verfuegbar : 9|3@1+ (1.0,0.0) [0.0|7] ""  Vector__XXX
 SG_ MMI_Counter_Bedienevent : 12|4@1+ (1.0,0.0) [0.0|15] ""  Vector__XXX
 SG_ DSSS_Warning : 16|5@1+ (1.0,0.0) [0.0|31] ""  Vector__XXX
 SG_ ZR_Kindersicherung_RSE : 21|1@1+ (1.0,0.0) [0.0|1] ""  Vector__XXX
 SG_ ZR_RSE_aktivieren : 22|1@1+ (1.0,0.0) [0.0|1] ""  Vector__XXX
 SG_ MMI_SDS_aktiv : 23|1@1+ (1.0,0.0) [0.0|1] ""  Vector__XXX
 SG_ MU_SecondDisplay : 24|3@1+ (1.0,0.0) [0.0|7] ""  Vector__XXX
 SG_ MMI_Telefon_aktiv : 27|1@1+ (1.0,0.0) [0.0|1] ""  Vector__XXX
 SG_ MMI_Gurt_Mic_ref : 28|1@1+ (1.0,0.0) [0.0|1] ""  Vector__XXX
 SG_ ZR_Sta_Inszenierung : 29|2@1+ (1.0,0.0) [0.0|3] ""  BCM
 SG_ ZR_AppConnect_Zustand : 31|1@1+ (1.0,0.0) [0.0|1] ""  Vector__XXX
 SG_ MU_Update_Time : 32|8@1+ (0.1,0) [0.0|25.5] "Unit_Hours"  Vector__XXX
 SG_ ZR_Parken_Sondermodus : 48|4@1+ (1.0,0.0) [0.0|15] ""  Vector__XXX

BO_ 2527679860 MDK_02: 8 BCM
 SG_ MDK_Change_Polling_Mode : 12|4@1+ (1.0,0.0) [0.0|15] ""  WLC_01_CFD
 SG_ MDK_Function_State : 16|2@1+ (1.0,0.0) [0.0|3] ""  WLC_01_CFD

BO_ 1639 Mem_BFS_01: 8 Gateway_Max
 SG_ Mem_BFS_01_CRC : 0|8@1+ (1,0) [0|255] ""  Vector__XXX
 SG_ Mem_BFS_01_BZ : 8|4@1+ (1,0) [0|15] ""  Vector__XXX
 SG_ BFS_Fond_Bed_Ack : 12|1@1+ (1.0,0.0) [0.0|1] ""  Vector__XXX
 SG_ BFS_Lehne_nicht_verriegelt : 13|1@1+ (1.0,0.0) [0.0|1] ""  Vector__XXX
 SG_ BFS_Klapptisch_offen : 14|1@1+ (1.0,0.0) [0.0|1] ""  Vector__XXX
 SG_ BFS_Gurtbringer_Sperre : 15|1@1+ (1.0,0.0) [0.0|1] ""  TSGGen3_BFS,TSGGen3_FS,TSGGen3_HBFS,TSGGen3_HFS
 SG_ BFS_Sitzsym_Fahrt_aktiv : 16|1@1+ (1.0,0.0) [0.0|1] ""  Vector__XXX
 SG_ BFS_Sitzfahrt_aktiv : 17|1@1+ (1.0,0.0) [0.0|1] ""  TSGGen3_BFS,TSGGen3_FS,TSGGen3_HBFS,TSGGen3_HFS
 SG_ BFS_SLV_aktiv : 18|1@1+ (1.0,0.0) [0.0|1] ""  Vector__XXX
 SG_ BFS_SHV_aktiv : 19|1@1+ (1.0,0.0) [0.0|1] ""  Vector__XXX
 SG_ BFS_LNV_aktiv : 20|1@1+ (1.0,0.0) [0.0|1] ""  Vector__XXX
 SG_ BFS_SNV_aktiv : 21|1@1+ (1.0,0.0) [0.0|1] ""  Vector__XXX
 SG_ BFS_KSV_aktiv : 22|1@1+ (1.0,0.0) [0.0|1] ""  Vector__XXX
 SG_ BFS_LKV_aktiv : 23|1@1+ (1.0,0.0) [0.0|1] ""  Vector__XXX
 SG_ BFS_STV_aktiv : 24|1@1+ (1.0,0.0) [0.0|1] ""  Vector__XXX
 SG_ BFS_LHV_aktiv : 25|1@1+ (1.0,0.0) [0.0|1] ""  Vector__XXX
 SG_ BFS_LWV_aktiv : 26|1@1+ (1.0,0.0) [0.0|1] ""  Vector__XXX
 SG_ BFS_GHV_aktiv : 27|1@1+ (1.0,0.0) [0.0|1] ""  Vector__XXX
 SG_ BFS_KSS_Fahrt_aktiv : 28|1@1+ (1.0,0.0) [0.0|1] ""  Vector__XXX
 SG_ BFS_MMB_lokal_Stop : 29|1@1+ (1.0,0.0) [0.0|1] ""  Vector__XXX
 SG_ BFS_Ruhestellung_Status : 30|1@1+ (1.0,0.0) [0.0|1] ""  Vector__XXX
 SG_ BFS_Seat_Locked : 31|1@1+ (1.0,0.0) [0.0|1] ""  Vector__XXX
 SG_ BFS_MMB_storage : 32|4@1+ (1.0,0.0) [0.0|15] ""  BCM,TSGGen3_BFS
 SG_ BFS_MMB_tipp : 36|1@1+ (1.0,0.0) [0.0|1] ""  BCM,TSGGen3_BFS
 SG_ BFS_MMB_tast : 37|1@1+ (1.0,0.0) [0.0|1] ""  BCM,TSGGen3_BFS
 SG_ BFS_MMB_store_LED_on : 38|1@1+ (1.0,0.0) [0.0|1] ""  TSGGen3_BFS
 SG_ BFS_MMB_storage_beep : 39|1@1+ (1.0,0.0) [0.0|1] ""  Vector__XXX
 SG_ BFS_MMB_store : 40|1@1+ (1.0,0.0) [0.0|1] ""  TSGGen3_BFS
 SG_ BFS_MMB_glob_stop : 41|1@1+ (1.0,0.0) [0.0|1] ""  BCM,TSGGen3_BFS
 SG_ BFS_FSV_ausgeklappt : 42|1@1+ (1.0,0.0) [0.0|1] ""  Vector__XXX
 SG_ BFS_Klappfunktion_Aktiv : 51|1@1+ (1.0,0.0) [0.0|1] ""  Vector__XXX
 SG_ BFS_Klappfunktion_Bed_Ack : 52|2@1+ (1.0,0.0) [0.0|3] ""  Vector__XXX
 SG_ BFS_Klappfunktion_Beschraenkung : 54|2@1+ (1.0,0.0) [0.0|3] ""  Vector__XXX
 SG_ BFS_Klappfunktion_Status : 56|2@1+ (1.0,0.0) [0.0|3] ""  Vector__XXX

BO_TX_BU_ 917 :BCM,Gateway_Max;
CM_ BO_ 779 "MQB";
CM_ BO_ 982 "MQB";
CM_ BO_ 2527679633 "Botschaft mit Signalen der Luftzusatzheizung";
CM_ BO_ 917 "MLB";
CM_ BO_ 1639 "MLBevo";

CM_ SG_ 2549088319 KN_TSG_HBFS_BusKnockOut "Ausgabe des BusKnockout-Status";
CM_ SG_ 2549088319 KN_TSG_HBFS_BusKnockOutTimer "Ausgabe des BusKnockOut-Timer";
CM_ SG_ 2549088319 KN_TSG_HBFS_DiagPfad "Kennzeichnung der Diagnosefähigkeit des BusInterfaces eines Steuergerätes (Knoten)
Umfang LAH 80127

Bei Nutzung des Signal explizit pro angebundenem BusInterface zu setzen:
MQB auf K-CAN = 0 (aktiv)
MQB2020 auf K-CAN = 0 (aktiv)
MQBw_Baseline auf K";
CM_ SG_ 2549088319 KN_TSG_HBFS_ECUKnockOut "Ausgabe des ECUKnockout-Status";
CM_ SG_ 2549088319 KN_TSG_HBFS_ECUKnockOutTimer "Ausgabe des ECUKnockOut-Timer";
CM_ SG_ 2549088319 NM_TSG_HBFS_Wakeup "enthält die Weckursache; stehen mehrere Weckursachen parallel an, dann muss der kleinste Wert übertragen werden";
CM_ SG_ 2549088319 TSG_HBFS_Abschaltstufe "Funktionseinschränkung aufgrund aktiver Abschaltstufe";
CM_ SG_ 2549088319 TSG_HBFS_KD_Fehler "Bei gesetztem Bit ist mindestens ein Kundendienstfehler eingetragen";
CM_ SG_ 2549088319 TSG_HBFS_KompSchutz "Funktionseinschränkung aufgrund Komponentenschutz aktiv";
CM_ SG_ 2549088319 TSG_HBFS_Nachlauftyp "Abgebildet wird die von der Hardware vorgegebene Möglichkeit, die Kommunikation nach Klemme 15 = AUS aufrecht zu erhalten. Es wird ein Init-Wert gesendet.";
CM_ SG_ 2549088319 TSG_HBFS_Transport_Mode "Funktionseinschränkung aufgrund aktivem Transport Mode und/oder Transport Schutz";

CM_ SG_ 2549088318 KN_TSG_HFS_BusKnockOut "Ausgabe des BusKnockout-Status";
CM_ SG_ 2549088318 KN_TSG_HFS_BusKnockOutTimer "Ausgabe des BusKnockOut-Timer";
CM_ SG_ 2549088318 KN_TSG_HFS_DiagPfad "Kennzeichnung der Diagnosefähigkeit des BusInterfaces eines Steuergerätes (Knoten)
Umfang LAH 80127

Bei Nutzung des Signal explizit pro angebundenem BusInterface zu setzen:
MQB auf K-CAN = 0 (aktiv)
MQB2020 auf K-CAN = 0 (aktiv)
MQBw_Baseline auf K";
CM_ SG_ 2549088318 KN_TSG_HFS_ECUKnockOut "Ausgabe des ECUKnockout-Status";
CM_ SG_ 2549088318 KN_TSG_HFS_ECUKnockOutTimer "Ausgabe des ECUKnockOut-Timer";
CM_ SG_ 2549088318 NM_TSG_HFS_Wakeup "enthält die Weckursache; stehen mehrere Weckursachen parallel an, dann muss der kleinste Wert übertragen werden";
CM_ SG_ 2549088318 TSG_HFS_Abschaltstufe "Funktionseinschränkung aufgrund aktiver Abschaltstufe";
CM_ SG_ 2549088318 TSG_HFS_KD_Fehler "Bei gesetztem Bit ist mindestens ein Kundendienstfehler eingetragen";
CM_ SG_ 2549088318 TSG_HFS_KompSchutz "Funktionseinschränkung aufgrund Komponentenschutz aktiv";
CM_ SG_ 2549088318 TSG_HFS_Nachlauftyp "Abgebildet wird die von der Hardware vorgegebene Möglichkeit, die Kommunikation nach Klemme 15 = AUS aufrecht zu erhalten. Es wird ein Init-Wert gesendet.";
CM_ SG_ 2549088318 TSG_HFS_Transport_Mode "Funktionseinschränkung aufgrund aktivem Transport Mode und/oder Transport Schutz";

CM_ SG_ 2549088421 KN_WLC1_BusKnockOut "Ausgabe des BusKnockout-Status";
CM_ SG_ 2549088421 KN_WLC1_BusKnockOutTimer "Ausgabe des BusKnockOut-Timer";
CM_ SG_ 2549088421 KN_WLC1_DiagPfad "Kennzeichnung der Diagnosefaehigkeit des BusInterfaces eines Steuergeraetes (Knoten)
Umfang LAH 80127

Bei Nutzung des Signal explizit pro angebundenem BusInterface zu setzen

MQBw_Baseline = K2CANFD = 0 (aktiv)";
CM_ SG_ 2549088421 KN_WLC1_ECUKnockOut "Ausgabe des ECUKnockout-Status";
CM_ SG_ 2549088421 KN_WLC1_ECUKnockOutTimer "Ausgabe des ECUKnockOut-Timer";
CM_ SG_ 2549088421 NM_WLC1_Wakeup "enthält die Weckursache; stehen mehrere Weckursachen parallel an, dann muss der kleinste Wert übertragen werden";
CM_ SG_ 2549088421 WLC1_Abschaltstufe "Funktionseinschränkung aufgrund aktiver Abschaltstufe";
CM_ SG_ 2549088421 WLC1_KD_Fehler "Bei gesetztem Bit ist mindestens ein Kundendienstfehler eingetragen";
CM_ SG_ 2549088421 WLC1_KompSchutz "Funktionseinschränkung aufgrund Komponentenschutz aktiv";
CM_ SG_ 2549088421 WLC1_Nachlauftyp "Abgebildet wird die von der Hardware vorgegebene Möglichkeit, die Kommunikation nach Klemme 15 = AUS aufrecht zu erhalten. Es wird ein Init-Wert gesendet.";
CM_ SG_ 2549088421 WLC1_Transport_Mode "Funktionseinschränkung aufgrund aktivem Transport Mode und/oder Transport Schutz";

CM_ SG_ 779 KBI_ABS_Lampe "ABS-Sicherheits-Lampe wurde eingeschaltet.";
CM_ SG_ 779 KBI_Airbag_Lampe "Airbag Sicherheits-Lampe wurde eingeschaltet ";
CM_ SG_ 779 KBI_angez_Geschw "Im Tacho angezeigte Geschwindigkeit inklusive der Voreilung

";
CM_ SG_ 779 KBI_Anzeigefehler_NV "Über dieses Signal teilt das Kombiinstrument dem Nightvision-Steuergerät mit, dass ein Fehler vom Kombiinstrument diagnostiziert wurde, der zur Abschaltung der Nightvision-Funktion führen muss.";
CM_ SG_ 779 KBI_Anzeigefehler_SWA "Signal bezieht sich nur auf die SWA-Lampe, Vorhalt für Kombis mit SWA-Lampe. ";
CM_ SG_ 779 KBI_Anzeigestatus_ACC "Status der ACC-Anzeige im nicht permanenten Displaybereich";
CM_ SG_ 779 KBI_Anzeigestatus_GRA "Anzeigestatus der GRA High Wunschgeschwindigkeitsanzeige im Kombiinstrument.
Bei VW bedeutet 'nicht vorhanden' GRA-low fähig (LED immer verbaut).
0 = nicht vorhanden
1 = Wunschgeschwindigkeits-Anzeigemöglichkeit vorhanden
2 = reserviert
3 = Fehler (B";
CM_ SG_ 779 KBI_Anzeigestatus_LIM "Anzeigestatus der Speedlimiter Wunschgeschwindigkeitsanzeige im Kombiinstrument (permanenter Anzeigebereich)
0 = nicht vorhanden
1 = Wunschgeschwindigkeits-Anzeigemöglichkeit vorhanden
2 = reserviert
3 = Fehler (Botschaftsüberwachung, Timeout, Akustik";
CM_ SG_ 779 KBI_Anzeigestatus_RHP "Anzeigestatus des roten RHP-Symbols.";
CM_ SG_ 779 KBI_ARA_in_Anzeige "Anzeige von ARA im Kombi aktiv";
CM_ SG_ 779 KBI_Audioabsenkung_MIB "Anforderung der Audioabsenkung im MIB";
CM_ SG_ 779 KBI_Bestaetigung_ESP_Off "ESP Off Bestätigung vom Kombi ans ESC";
CM_ SG_ 779 KBI_BKL_Lampe "Sicherheits-Lampe Bremskontrolle wurde eingeschaltet;
";
CM_ SG_ 779 KBI_ESP_Lampe "ESP-Sicherheits-Lampe wurde eingeschaltet ";
CM_ SG_ 779 KBI_Fehler_Anzeige_ACC "Rückmeldung an ACC, dass mindestens eine der ACC-relevanten Anzeigen -rote Fahrerübernahme, Mitteldisplay, Gong - fehlerhaft sind.";
CM_ SG_ 779 KBI_Handbremse "Handbremsen-Information vom Kombi.
Das Signal bezieht sich ausschließlich auf den Zustand der konventionellen Handbremse.";
CM_ SG_ 779 KBI_im_Stellgliedtest "Kombi im Stellgliedtest, Signal muss eingelesen werden, um Fehlfunktion aufgrund der Bewegung der Stellglieder (Drehzahlmesser, Tacho) des Kombis zu verhindern";
CM_ SG_ 779 KBI_Konsistenz_ACC "Rückmeldung an ACC, dass die Botschaften zur Ansteuerung von Anzeigen nicht bzw. nicht konsistent empfangen wurden (Timeout-, BZ-, CHK- und DLC-Fehler)                                                                                                        ";
CM_ SG_ 779 KBI_Lenkung_Lampe "Sicherheits-Lampe der Lenkung (Lenkhilfe EPS, Audi-Dynamic-Steering ...) wurde eingeschaltet.

0x0 = Lenkungs-Lampe aus
0x1 = Lenkungs-Lampe ein";
CM_ SG_ 779 KBI_MFA_v_Einheit_01 "Einheit der Geschwindigkeit, die vom Fahrer im Car-Menü gewählt wurde. Veränderliche Grösse, im Gegensatz zur Einheit des Tachokranzes.";
CM_ SG_ 779 KBI_NV_in_Anzeige "Das Bit gibt dem NV die Information, ob NV-Bild im Kombi in der Anzeige ist. (Information ist notwendig um Kontrasverstellungen nur dann zuzulassen, wenn der Fahrer das Feedback über das  Kombidisplay bekommt.)";
CM_ SG_ 779 KBI_Oeldruck_Schalter "Das Signal bildet den Status des Öldrucks über den am Kombi angeschlossenen Öldruckschalter ab.";
CM_ SG_ 779 KBI_Oeldruckwarnung "Öldruckwarnung im Kombi aktiv";
CM_ SG_ 779 KBI_PLA_in_Anzeige "Das Signal wird als aktive Rückmeldung genutzt, ob die Info des PLA im Kombi angezeigt wird. Wenn nach Anforderung des Displays das Signal zweimal auf 0 ist, wird der Parkvorgang abgebrochen.
Ein Kombi, dass PLA Anzeige nicht unterstützt, schickt dauerha";
CM_ SG_ 779 KBI_SILA_gueltig "Rückmeldeinformation (Bit 1-6) ist gültig";
CM_ SG_ 779 KBI_Systemstatus "Signalisiert erkannte FuSi-relevante Fehler im Kombi
(keinen Ausfall der Akustik oder des Displays)";
CM_ SG_ 779 KBI_Tankwarnung "Fahrer wird gewarnt, dass er den Reservebereich erreicht hat. Fzg.spezifische Warnschwelle";
CM_ SG_ 779 KBI_Tankwarnung_ungueltig "Validiert den Inhalt des Signales KBI_Tankwarnung";
CM_ SG_ 779 KBI_Taster_Fahrwerk "Betätigung Taster 'Fahrwerk' im Kombi";
CM_ SG_ 779 KBI_Taster_Lift "Betätigung Taster 'Lift' im Kombi J1 zur Verarbeitung im Porsche EFP Steuergerät";
CM_ SG_ 779 KBI_V_Digital "Ausgabe der im Kombi angezeigten digitalen Geschwindigkeit.

Einheit ist im KBI_MFA_v_Einheit_01 definiert";
CM_ SG_ 779 KBI_Vorglueh_System_Lampe "Rückmeldung der Vorglühlampe bzw. Motor Systemlampe (MO_Systemlampe) an den Motor (bei Diesel und Otto!). Hardwaremässig gleiche LED im Kombi (EPC- oder Glühwendel), Unterscheidung nur über Ziffernblatt.";

CM_ SG_ 1719 KBI_aktive_Laengsfunktion_02 "Auswahl, der vom Fahrer gewünschten Laengsregelfunktion";
CM_ SG_ 1719 KBI_FoD_PopUP_Quittiert "Angezeigte FoD-Warnung im Kombi wurde vom Fahrer quittiert; 
Signal wird für die Dauer von 2 Sekunden gesendet";
CM_ SG_ 1719 KBI_FStatus_Tank "Signal wird gesetzt:

a) Während der Fehlerentprellzeit (20 s Entprellung)

b) Bei erkanntem Fehler wird der Tankinhalt während der laufenden KL15-Phase über den 
    Verbrauch zurückgerechnet. In dieser Zeit ist das Bit ebenfalls gesetzt. Nach einem";
CM_ SG_ 1719 KBI_GRA_im_ACC "Gibt den vom Fahrer ausgewählten Modus (ACC oder GRA_im_ACC) an.";
CM_ SG_ 1719 KBI_Inhalt_Tank "Restmenge 2 bzw. 2,5l nicht auflösbar

";
CM_ SG_ 1719 KBI_Kilometerstand "Fehler wird ausgegeben, falls Kilometerstand nicht restaurierbar
";
CM_ SG_ 1719 KBI_Oelwechsel_durchgefuehrt "Nach einen Ölwechsel (Service) ist die Ethanol Warmfahrwarnung zu unterdrücken.";
CM_ SG_ 1719 KBI_QBit_Aussen_Temp_gef "0x0 = gültiger Wert
0x1 = Ersatz-, Init- oder Fehlerwert";
CM_ SG_ 1719 KBI_RDK_Kalibrier_Anf "Bei gesetztem Bit soll die RDK die aktuellen Istdrücke zu Solldrücken übernehmen (nur bei Nichtverbau einer Headunit erforderlich).";
CM_ SG_ 1719 KBI_Reserve_Warnung_Sek "Signalisiert die Reservewarnung für die Energiespeicher CNG, LPG, HV-Batterie.
Fahrer wird gewarnt, dass er den Reservebereich erreicht hat. Fzg.spezifische Warnschwelle.";
CM_ SG_ 1719 KBI_Standzeit_02 "Zähler welcher die Standzeit des Motors wiedergibt.
Das Signal beschreibt den Anteil der Motor-Standzeit zwischen Zündung aus und nächstem Motorstart.";

CM_ SG_ 1720 KBI_BCmE_aktiv "Anzeige BCmE aktiv (BCmE-Screen oder Einsparhinweis in der Anzeige)";
CM_ SG_ 1720 KBI_GAP_Warn_Zeit_abgelaufen "Die Zeit, z.B. 1460 Tage, bis zur finalen Warnstufe der Gasanlagenprüfung wurde berechnet. Berechnung erfolgt auf Basis der aktuellen Uhrzeit mit einem Tageszähler. Keine Berechnung des Zählers bei Kl.30 AUS.";
CM_ SG_ 1720 KBI_Max_Tankinhalt "Mitteilung des maximalen Tankinhalts an das Reichweitenmodul";
CM_ SG_ 1720 KBI_Nachtanken_erkannt "Statusinformation Nachtankmodus";
CM_ SG_ 1720 KBI_Quittierung_cAQP "Quittierungsbestätigung vom Fahrer für Funktion cAQP";
CM_ SG_ 1720 KBI_Quittierung_Naesse "Quittierungsbestätigung vom Fahrer";
CM_ SG_ 1720 KBI_Reifenumfang "Mittlerer Radumfang aus der K-Zahl gerechnet in Millimeter.  Byte 2 Bit 5,4 reserviert, Byte 2 Bit 3..0 und Byte 1 Bit 7..0; Wertebereich 0..4096 mm
";
CM_ SG_ 1720 KBI_Reifenumfang_Sekundaer "Fahrzeuge mit unterschiedlichen Reifenumfängen Vorderachse / Hinterachse:

Primärachse: KBI_Reifenumfang
Sekundärachse: KBI_Reifenumfang_Sekundaer
";
CM_ SG_ 1720 KBI_Sparhinweis_quittiert "angezeigter Sparhinweis ist quittiert. Signal wird nach zwei Sendebotschaften wieder auf '0' gesetzt.";
CM_ SG_ 1720 KBI_Tankfuellstand_Prozent "Tankfüllstand in %";
CM_ SG_ 1720 KBI_Tankinhalt_hochaufl "angezeigter Tankinhalt hochauflösend zur Restreichweitenberechnung";
CM_ SG_ 1720 KBI_Variante "Zeigt an ob es sich um ein konventionelles Zeiger-Kombiinstrument handelt oder um eine Volldisplay-Kombiinstrument";
CM_ SG_ 1720 KBI_Variante_USA "In diesem Signal wird die HW-Variante des Kombis ausgegeben, ACC plausibilisiert auf dieses Signal hin seine US-Codierung";

CM_ SG_ 1722 SOK_Kombi_03_Signatur "Signatur im Rahmen der durch SOK geschützen Broadcast-Kommunikation

Geschützte Funktion: Wegstreckenschutz (Distance)
Geschützte Signale: KBI_Reifenumfang";

CM_ SG_ 2527679639 AuthTime_Trigger_Distribution "Funktion Authentische Zeit-Verteilung.Broadcast- Triggersignal für Bekanntgabe an alle Clients, dass ein neuer Zeitstempel im Zeitmaster vorliegt.";
CM_ SG_ 2527679639 KBI_Anzeige_ID_quittiert "Inforrmation über die vom Fahrer quittierte Anzeige";
CM_ SG_ 2527679639 KBI_FoD_VirtualCockpitPlus_State "Informs if the function on demand feature 'Virtual Cockpit Plus' is locked or not.";
CM_ SG_ 2527679639 KBI_Jokerkey "Betaetigung KBI Jokertaste";
CM_ SG_ 2527679639 KBI_Min_Tankinhalt "Tankanzeigeleerwert für Reichweitenberechnung, kein reales Kraftstoffvolumen";
CM_ SG_ 2527679639 KBI_RS_Druck_uebernehmen "Druck für Rundstreckenmodus übernehmen";
CM_ SG_ 2527679639 KBI_RS_Druckauswahl_Aktiv "Menue Druckauswahl aktiv";
CM_ SG_ 2527679639 KBI_RS_Mode_fortsetzen "Kombi fordert Fortsetzung des Rundstreckenmodus";
CM_ SG_ 2527679639 KBI_Rundstreckenmodus "Rundstreckenmodus Anforderung";
CM_ SG_ 2527679639 KBI_Weg_Zaehler "Inkrementaler Zähler des Kombis

PAG-Plattform:
Sendeart: Cyclic
Zykluszeit: 100ms

MLBevo_Konzern:
Sendeart: OnChange
Zykluszeit: 1000ms
Inhibitzeit: 100ms
";
CM_ SG_ 2527679639 KBI_Weg_Zaehler_F "Fehlerbit für den Inkrementalzähler Weg

PAG-Plattform:
Sendeart: Cyclic
Zykluszeit: 100ms

MLBevo_Konzern:
Sendeart: OnChange
Zykluszeit: 1000ms
Inhibitzeit: 100ms";

CM_ SG_ 1614 KBI_HUD_Data_01 "Kommunikation Kombi zu HUD. Prio.texte zur gleichzeitigen Anzeige im Kombi und HUD.";
CM_ SG_ 1614 KBI_HUD_Data_02 "Kommunikation Kombi zu HUD. Prio.texte zur gleichzeitigen Anzeige im Kombi und HUD.";
CM_ SG_ 1614 KBI_HUD_Data_03 "Kommunikation Kombi zu HUD. Prio.texte zur gleichzeitigen Anzeige im Kombi und HUD.";
CM_ SG_ 1614 KBI_HUD_Data_04 "Kommunikation Kombi zu HUD. Prio.texte zur gleichzeitigen Anzeige im Kombi und HUD.";
CM_ SG_ 1614 KBI_HUD_Data_05 "Kommunikation Kombi zu HUD. Prio.texte zur gleichzeitigen Anzeige im Kombi und HUD.";
CM_ SG_ 1614 KBI_HUD_Data_06 "Kommunikation Kombi zu HUD. Prio.texte zur gleichzeitigen Anzeige im Kombi und HUD.";
CM_ SG_ 1614 KBI_HUD_Data_07 "Kommunikation Kombi zu HUD. Prio.texte zur gleichzeitigen Anzeige im Kombi und HUD.";
CM_ SG_ 1614 KBI_HUD_Data_08 "Kommunikation Kombi zu HUD. Prio.texte zur gleichzeitigen Anzeige im Kombi und HUD.";

CM_ SG_ 1387 LCM_Blinker_Fehler_L "Blinker Fehler";
CM_ SG_ 1387 LCM_Datensatz_Fehler_L "zeigt einen vorliegenden Datensatz Fehler im LCM an (fehlender bzw. unplausibler Datensatz)";
CM_ SG_ 1387 LCM_DKL_L_defekt_Fehler "Sammel-Fehlerbit für den Ausfall der Funktion DKL";
CM_ SG_ 1387 LCM_Feh_L_BZ "Botschaftszaehler";
CM_ SG_ 1387 LCM_Feh_L_CRC "Checksumme mit CRC8";
CM_ SG_ 1387 LCM_GLW_L_defekt_Fehler "Sammel-Fehlerbit für den Ausfall der Funktion GLW";
CM_ SG_ 1387 LCM_LWR_L_allg_Fehler "Allgemeiner Schrittmotor-Fehler im linken LCM.";
CM_ SG_ 1387 LCM_LWR_L_defekt_Fehler "Allgemeiner LWR-Fehler im linken LCM.";
CM_ SG_ 1387 LCM_PO_Fehler_L "PO Fehler";
CM_ SG_ 1387 LCM_Shutter_Fehler_L "Shutter Fehler";
CM_ SG_ 1387 LCM_SKL_L_defekt_Fehler "Sammel-Fehlerbit für den Ausfall der Funktion SKL";
CM_ SG_ 1387 LCM_SM_Fehler_L "Sidemarker Fehler";
CM_ SG_ 1387 LCM_Sonstiger_Fehler_L "Sonstiger Fehler";
CM_ SG_ 1387 LCM_TFL_Fehler_L "TFL Fehler";

CM_ SG_ 1388 LCM_Blinker_Fehler_R "Blinker Fehler";
CM_ SG_ 1388 LCM_Datensatz_Fehler_R "zeigt einen vorliegenden Datensatz Fehler im LCM an (fehlender bzw. unplausibler Datensatz)";
CM_ SG_ 1388 LCM_DKL_R_defekt_Fehler "Sammel-Fehlerbit für den Ausfall der Funktion DKL";
CM_ SG_ 1388 LCM_Feh_R_BZ "Botschaftszaehler";
CM_ SG_ 1388 LCM_Feh_R_CRC "Checksumme mit CRC8";
CM_ SG_ 1388 LCM_GLW_R_defekt_Fehler "Sammel-Fehlerbit für den Ausfall der Funktion GLW";
CM_ SG_ 1388 LCM_LWR_R_allg_Fehler "Allgemeiner Schrittmotor-Fehler im rechten LCM.";
CM_ SG_ 1388 LCM_LWR_R_defekt_Fehler "LWR defekt im rechten LCM.";
CM_ SG_ 1388 LCM_PO_Fehler_R "PO Fehler";
CM_ SG_ 1388 LCM_Shutter_Fehler_R "Shutter Fehler";
CM_ SG_ 1388 LCM_SKL_R_defekt_Fehler "Sammel-Fehlerbit für den Ausfall der Funktion SKL";
CM_ SG_ 1388 LCM_SM_Fehler_R "Sidemarker Fehler";
CM_ SG_ 1388 LCM_Sonstiger_Fehler_R "Sonstiger Fehler";
CM_ SG_ 1388 LCM_TFL_Fehler_R "TFL Fehler";

CM_ SG_ 403 AMBEX_CH_aktiv "Statussignal vom Exterieur Ambiente. Gibt an, ob eine Coming Home-Animation aktiv ist.";
CM_ SG_ 403 AMBEX_CH_Trigger "Triggersignal vom Exterieur Ambiente. Gibt an, wann eine Animation während einer Coming Home-Inszenierung gestartet werden soll.";
CM_ SG_ 403 AMBEX_LH_aktiv "Statussignal vom Exterieur Ambiente. Gibt an, ob eine Leaving Home-Animation aktiv ist.";
CM_ SG_ 403 AMBEX_LH_Trigger "Triggersignal vom Exterieur Ambiente. Gibt an, wann eine Animation während einer Leaving Home-Inszenierung gestartet werden soll.";
CM_ SG_ 403 BCM1_CH_aktiv "Coming Home (zusätzlich zum Signal 'BCM1_CH_LH_aktiv' in der Botschaft BCM1_01)";
CM_ SG_ 403 BCM1_FoD_Sperrung_AnimTFL "Sperrung Animation des Tagfahrlichts durch FoD";
CM_ SG_ 403 BCM1_LH_aktiv "Leaving Home (zusätzlich zum Signal 'BCM1_CH_LH_aktiv' in der Botschaft BCM1_01)";
CM_ SG_ 403 BM_Autobahn "Status Autobahnblinken
";
CM_ SG_ 403 BM_ZV_auf "Blinken bei ZV auf

";
CM_ SG_ 403 BM_ZV_zu "Blinken bei ZV zu

";
CM_ SG_ 403 LCM_Abschaltung_Vbat_L_Anf "Anfrage Abschaltung Vbat LCM links";
CM_ SG_ 403 LCM_Abschaltung_Vbat_R_Anf "Anfrage Abschaltung Vbat LCM rechts";
CM_ SG_ 403 LCM_Animiertes_TFL_Anf "Anforderung TFL-Animation";
CM_ SG_ 403 LCM_Blinker_L_Anf "Blinker Ansteuerung links (inkl.Takt)";
CM_ SG_ 403 LCM_Blinker_R_Anf "Blinker Ansteuerung rechts (inkl.Takt)";
CM_ SG_ 403 LCM_Blinkerwischen_Anf "Anforderung Blinkerwischen";
CM_ SG_ 403 LCM_Blinkerzyklus_L "Blinkfunktion/zyklus links (in)aktiv";
CM_ SG_ 403 LCM_Blinkerzyklus_R "Blinkfunktion/zyklus rechts (in)aktiv";
CM_ SG_ 403 LCM_Designlicht_4 "Ansteuerung Designlicht 4";
CM_ SG_ 403 LCM_Designlicht_5 "Ansteuerung Designlicht 5";
CM_ SG_ 403 LCM_ECE_SAE_Umschaltung_Anf "Anforderung Umschaltung für LCM";
CM_ SG_ 403 LCM_Leistungsreduzierung_Anf "Anfrage Leistungsreduzierung (BCM1 -->  LCM)";
CM_ SG_ 403 LCM_PL_L_Anf "PL Ansteuerung links";
CM_ SG_ 403 LCM_PL_R_Anf "PL Ansteuerung rechts";
CM_ SG_ 403 LCM_PO_L_Anf "PO Ansteuerung links";
CM_ SG_ 403 LCM_PO_R_Anf "PO Ansteuerung rechts";
CM_ SG_ 403 LCM_Sh_L_Anf "Shutter Ansteuerung links";
CM_ SG_ 403 LCM_Sh_R_Anf "Shutter Ansteuerung rechts";
CM_ SG_ 403 LCM_Signaturlicht_Anf "Ansteuerung Signaturlicht";
CM_ SG_ 403 LCM_SM_L_Anf "Sidemarker Ansteuerung links";
CM_ SG_ 403 LCM_SM_R_Anf "Sidemarker Ansteuerung rechts";
CM_ SG_ 403 LCM_Soll_BZ "Botschaftszaehler";
CM_ SG_ 403 LCM_Soll_CRC "Checksumme nach CRC8 Algo";
CM_ SG_ 403 LCM_TFL_L_Anf "TFL Ansteuerung links";
CM_ SG_ 403 LCM_TFL_R_Anf "TFL Ansteuerung rechts";
CM_ SG_ 403 LCM_TFL_Signatur_Anf "Anforderung der verschiedenen TFL-Signaturen";
CM_ SG_ 403 LCM_univ_1_L_Anf "zusätzlicher High Side Schalter links";
CM_ SG_ 403 LCM_univ_1_R_Anf "zusätzlicher High Side Schalter rechts";

CM_ SG_ 411 LCM_Abschaltbestaetigung_L "Handshake - LCM bestätigt Anfrage";
CM_ SG_ 411 LCM_Ausgangsleistungsred_L_Sta "Info Ausgangsleistungsreduzierung";
CM_ SG_ 411 LCM_Blinker_L_Sta "Blinker Status links";
CM_ SG_ 411 LCM_PL_L_Sta "PL Status links";
CM_ SG_ 411 LCM_PO_L_Sta "PO Status links";
CM_ SG_ 411 LCM_Sh_L_Sta "Shutter Status links";
CM_ SG_ 411 LCM_SM_L_Sta "Sidemarker Status links";
CM_ SG_ 411 LCM_Sta_L_BZ "Botschaftszaehler";
CM_ SG_ 411 LCM_Sta_L_CRC "Checksumme nach CRC8 Algo";
CM_ SG_ 411 LCM_TFL_L_Sta "TFL Status links";
CM_ SG_ 411 LCM_univ_1_L_Sta "Status zusätzlicher High Side Schalter links";
CM_ SG_ 411 LMS_DMD_LED_Temp_L "Temperaturangabe der DMD-LED";

CM_ SG_ 413 LCM_Abschaltbestaetigung_R "Handshake - LCM bestätigt Anfrage";
CM_ SG_ 413 LCM_Ausgangsleistungsred_R_Sta "Info Ausgangsleistungsreduzierung";
CM_ SG_ 413 LCM_Blinker_R_Sta "Blinker Status rechts";
CM_ SG_ 413 LCM_PL_R_Sta "PL Status rechts";
CM_ SG_ 413 LCM_PO_R_Sta "PO Status rechts";
CM_ SG_ 413 LCM_Sh_R_Sta "Shutter Status rechts";
CM_ SG_ 413 LCM_SM_R_Sta "Sidemarker Status rechts";
CM_ SG_ 413 LCM_Sta_R_BZ "Botschaftszaehler";
CM_ SG_ 413 LCM_Sta_R_CRC "Checksumme nach CRC8 Algo";
CM_ SG_ 413 LCM_TFL_R_Sta "TFL Status rechts";
CM_ SG_ 413 LCM_univ_1_R_Sta "Status zusätzlicher High Side Schalter rechts";
CM_ SG_ 413 LMS_DMD_LED_Temp_R "Temperaturangabe der DMD-LED";

CM_ SG_ 2527679510 LED_Feh_LM_L_03_BZ "Botschaftszähler für LED_Feh_LM_L_03-Botschaft";
CM_ SG_ 2527679510 LED_Feh_LM_L_03_CRC "Checksumme für LED_Feh_LM_L_03-Botschaft";
CM_ SG_ 2527679510 LED_L_Abbiegel_Def "Abbiegelichtfehler";
CM_ SG_ 2527679510 LED_L_Abblendl_Def "Fehler Abblendlicht";
CM_ SG_ 2527679510 LED_L_Allg_Elektr_Def "LED-Leimo defekt";
CM_ SG_ 2527679510 LED_L_falsch_codiert "LED-Leimo-Codierung entspricht nicht der Vorgabe durch das Master-SG";
CM_ SG_ 2527679510 LED_L_Fernl_Def "Fernlichtfehler";
CM_ SG_ 2527679510 LED_L_Laser_Def "Fehlerrückmeldung für den Laser";
CM_ SG_ 2527679510 LED_L_Laser_Stoerung "Temporäre Fehlerrückmeldung für den Laser";
CM_ SG_ 2527679510 LED_L_Zus_Fernl_LH_Def "Fehlerrückmeldung für das Zusatz-Fernlicht";

CM_ SG_ 2527679511 LED_Feh_LM_R_03_BZ "Botschaftszähler für LED_Feh_LM_R_03-Botschaft";
CM_ SG_ 2527679511 LED_Feh_LM_R_03_CRC "Checksumme für LED_Feh_LM_L_03-Botschaft";
CM_ SG_ 2527679511 LED_R_Abbiegel_Def "Abbiegelichtfehler";
CM_ SG_ 2527679511 LED_R_Abblendl_Def "Fehler Abblendlicht";
CM_ SG_ 2527679511 LED_R_Allg_Elektr_Def "LED-Leimo defekt";
CM_ SG_ 2527679511 LED_R_falsch_codiert "LED-Leimo-Codierung entspricht nicht der Vorgabe durch das Master-SG";
CM_ SG_ 2527679511 LED_R_Fernl_Def "Fernlichtfehler";
CM_ SG_ 2527679511 LED_R_Laser_Def "Fehlerrückmeldung für den Laser";
CM_ SG_ 2527679511 LED_R_Laser_Stoerung "temporäre Fehlerrückmeldung für den Laser";
CM_ SG_ 2527679511 LED_R_Zus_Fernl_LH_Def "Fehlerrückmeldung für das Zusatz-Fernlicht";

CM_ SG_ 981 BCM1_Abblendlicht_Anf "Anforderung Abblendlicht
";
CM_ SG_ 981 BCM1_Adaptive_Lichtvert_Anf "Funktion 'Adaptive Lichtverteilung' im AFS-SG  Ein- und Ausschalten";
CM_ SG_ 981 BCM1_Allwetterlicht_Anf "Anforderung eines Allwetterlichts (über AFS-SG realisiert): Licht für schlechte Sichtverhältnisse";
CM_ SG_ 981 BCM1_Animationssperrung "Sperrung der Scheinwerfer- und Heckleuchten-Animationen. Grund für Sperrung sind allgemeine Rahmenbedingungen, wie beispielseweise eine LDS-Stellung ungleich 'Auto'";
CM_ SG_ 981 BCM1_Autobahnlicht_Anf "Anforderung Autobahnlicht
";
CM_ SG_ 981 BCM1_CH_aktiv "Coming Home (zusätzlich zum Signal 'BCM1_CH_LH_aktiv' in der Botschaft BCM1_01)";
CM_ SG_ 981 BCM1_CH_LH_aktiv "Status Comming / Leaving Home
";
CM_ SG_ 981 BCM1_Fernlicht_Anf "Anforderung Fernlicht
";
CM_ SG_ 981 BCM1_Gleitende_Leuchtw_Anf "Funktion 'Gleitende Leuchtweite' im AFS-SG  freischalten";
CM_ SG_ 981 BCM1_GLW_Fernlicht_Anf "Harte Fernlichtanforderung von BCM1 an die Funktion 'gleitende Leuchtweite' im AFS-SG";
CM_ SG_ 981 BCM1_Kurvenlicht_links_Anf "Ansteuerung linkes Kurvenlicht/Abbiegelicht duch BCM1";
CM_ SG_ 981 BCM1_Kurvenlicht_rechts_Anf "Ansteuerung rechtes Kurvenlicht/Abbiegelicht duch BCM1";
CM_ SG_ 981 BCM1_LH_aktiv "Leaving Home (zusätzlich zum Signal 'BCM1_CH_LH_aktiv' in der Botschaft BCM1_01)";
CM_ SG_ 981 BCM1_Nebellicht_Anf "Anforderung Nebellicht
";
CM_ SG_ 981 BCM1_Nebelschluss_Ahg_Anf "Anforderung: Nebelschlusslicht Anhänger (Sollzustand)
";
CM_ SG_ 981 BCM1_Nebelschluss_Fzg_Anf "Anforderung: Nebelschlusslicht Fahrzeug (Sollzustand)";
CM_ SG_ 981 BCM1_Parklicht_li_Anf "Anforderung: Parklicht links (Sollzustand)
";
CM_ SG_ 981 BCM1_Parklicht_re_Anf "Anforderung: Parklicht rechts (Sollzustand)
";
CM_ SG_ 981 BCM1_Regenlicht_Anf "Anforderung: Regenlicht (Sollzustand)
";
CM_ SG_ 981 BCM1_Schlusslicht_Anf "Anforderung: Schlusslicht Fahrzeug (Sollzustand)
";
CM_ SG_ 981 BCM1_Signaturlicht_Anf "Signal zur Anforderung des Signaturlichts";
CM_ SG_ 981 BCM1_Standlicht_Anf "Anforderung: Schlusslicht (Sollzustand)";
CM_ SG_ 981 BCM1_Tagfahrlicht_Anf "Anforderung: Tagfahrlicht (Sollzustand)";
CM_ SG_ 981 BCM1_Touristen_Licht_Anf "Anforderung: Touristenlicht (Sollzustand)";
CM_ SG_ 981 BCM1_Umfeldleuchten_Anf "Anforderung für Umfeldleuchten";
CM_ SG_ 981 BCM_Rueckfahrlicht_Anf "Anforderung Rückfahrlicht (Sollzustand). 
Das Signal wird entprellt (typisch 400ms) und bei KL15EIN gesendet. Das Signal ist unabhängig von der Position des Heckdeckels (kein Überhitzungsschutz).";
CM_ SG_ 981 Licht_Anf_01_BZ "4bit Botschaftszaehler, wird mit jeder Sendebotschaft inkrementiert";
CM_ SG_ 981 Licht_Anf_01_CRC "Für MLB:
'Berechnung siehe Lastenheft 'Kommunikationsabsicherung für FlexRay und CAN''

Ab MQB und MLBevo:
'Berechnung siehe Lastenheft 'End-to-End Kommunikationsabsicherung''

Endwerte siehe Begleitdokument 'S-PDU Kennungsfolgen'";
CM_ SG_ 981 TFL_Matrix_Variante01_Anf "Gibt die einzustellende Variante der Tagfahrlicht-Matrix an.";
CM_ SG_ 981 TFL_Matrix_Variante02_Anf "Gibt die einzustellende Variante der Tagfahrlicht-Matrix an.";
CM_ SG_ 981 TFL_Matrix_Variante03_Anf "Gibt die einzustellende Variante der Tagfahrlicht-Matrix an.";
CM_ SG_ 981 TFL_Matrix_Variante04_Anf "Gibt die einzustellende Variante der Tagfahrlicht-Matrix an.";

CM_ SG_ 982 BCM2_Bremsl_durch_ECD "Bremslicht (ECD-Bremsung)
";
CM_ SG_ 982 BCM2_Bremsl_durch_ECD_invers "Inversbit Bremslicht (ECD-Bremsung) (Kommunikationsabsicherung)";
CM_ SG_ 982 LH_3_Bremsl_def "Fehlerstatus 3. Bremsleuchte
";
CM_ SG_ 982 LH_Aussenlicht_def "Aussenlicht kann nicht mehr korrekt angesteuert werden (EEPROM Codierung kann nicht mehr ausgelesen werden)
";
CM_ SG_ 982 LH_Blinker_HL_akt "Blinker hinten links
";
CM_ SG_ 982 LH_Blinker_HR_akt "Blinker hinten rechts
";
CM_ SG_ 982 LH_Blinker_li_def "Fehlerstatus Blinker hinten links
";
CM_ SG_ 982 LH_Blinker_re_def "Fehlerstatus Blinker hinten rechts
";
CM_ SG_ 982 LH_Brems_Blk_li_def "Konfiguration BRL + BLK links 
";
CM_ SG_ 982 LH_Brems_Blk_re_def "Konfiguration BRL + BLK rechts
";
CM_ SG_ 982 LH_Bremsl_li_def "Fehlerstatus Bremslicht hinten links (Detektion Einzelausfall)
";
CM_ SG_ 982 LH_Bremsl_li_ges_def "Fehlerstatus Bremslicht hinten links (Detektion Totalausfall)
";
CM_ SG_ 982 LH_Bremsl_re_def "Fehlerstatus Bremslicht hinten rechts  (Detektion Einzelausfall)
";
CM_ SG_ 982 LH_Bremsl_re_ges_def "Fehlerstatus Bremslicht hinten rechts (Detektion Totalausfall)";
CM_ SG_ 982 LH_Bremslicht_H_aktiv "Bremslicht hinten
";
CM_ SG_ 982 LH_Diag_LED_li_def "Heckleuchte links defekt";
CM_ SG_ 982 LH_Diag_LED_re_def "Heckleuchte rechts defekt";
CM_ SG_ 982 LH_Diag_Status_li_def "Außenlicht Diagnose 
Systemstörung links";
CM_ SG_ 982 LH_Diag_Status_re_def "Außenlicht Diagnose Systemstörung rechts ";
CM_ SG_ 982 LH_Kennzl_def "Fehlerstatus Kennzeichenbeleuchtung hinten
";
CM_ SG_ 982 LH_Nebel_li_def "Fehlererkennung Nebelschlusslicht hinten links";
CM_ SG_ 982 LH_Nebel_mi_def "Fehlererkennung Nebelschlusslicht hinten Mitte


";
CM_ SG_ 982 LH_Nebel_re_def "Fehlererkennung Nebelschlusslicht hinten rechts
";
CM_ SG_ 982 LH_Nebelschluss_aktiv "Nebelschlusslicht
";
CM_ SG_ 982 LH_Parklicht_HL_aktiv "Parklicht hinten links 
";
CM_ SG_ 982 LH_Parklicht_HR_aktiv "Parklicht hinten rechts 
";
CM_ SG_ 982 LH_Rueckf_li_def "Fehlererkennung Rückfahrlicht hinten links
";
CM_ SG_ 982 LH_Rueckf_mi_def "Fehlererkennung Rückfahrlicht Mitte
";
CM_ SG_ 982 LH_Rueckf_re_def "Fehlererkennung Rückfahrlicht hinten rechts
";
CM_ SG_ 982 LH_Rueckfahrlicht_aktiv "Rueckfahrlicht";
CM_ SG_ 982 LH_Schluss_Brems_li_def "Konfiguration SL+ BRL + PL links und SL+ BRL  links
";
CM_ SG_ 982 LH_Schluss_Brems_Nebel_li_def "Signal wird gesetzt, wenn eine Unterbrechung oder  ein Kurzschluss am Lampenausgang für Schluss_Brems_Nebelschlusslicht erkannt wird.";
CM_ SG_ 982 LH_Schluss_Brems_Nebel_re_def "Signal wird gesetzt, wenn eine Unterbrechung oder  ein Kurzschluss am Lampenausgang für Schluss_Brems_Nebelschlusslicht erkannt wird.";
CM_ SG_ 982 LH_Schluss_Brems_re_def "Konfiguration SL+ BRL + PL rechts und SL+ BRL  rechts
";
CM_ SG_ 982 LH_Schluss_Nebel_li_def "Konfiguration SL + NSL links oder SL + NSL + PL links
";
CM_ SG_ 982 LH_Schluss_Nebel_re_def "Konfiguration SL + NSL rechts oder SL + NSL + PL rechts
";
CM_ SG_ 982 LH_Schlusslicht_li_def "Fehlererkennung Schlusslicht hinten links
";
CM_ SG_ 982 LH_Schlusslicht_re_def "Fehlererkennung Schlusslicht hinten rechts";
CM_ SG_ 982 LH_SL_BRL_BLK_li_def "Konfiguration SL + BRL + BLK links oder SL + BRL + BLK + PL links
";
CM_ SG_ 982 LH_SL_BRL_BLK_re_def "Konfiguration SL + BRL + BLK rechts oder SL + BRL + BLK + PL rechts
";
CM_ SG_ 982 LH_Standlicht_H_aktiv "Standlicht hinten
";
CM_ SG_ 982 LH_Zusatzschlussl_def "mindestens ein Zusatzschlusslicht in der Heckbeleuchtung defekt.";
CM_ SG_ 982 Licht_hinten_01_BZ "überlaufender 4bit Botschaftszaehler; wird in jeder Sendebotschaft inkrementiert";

CM_ SG_ 1624 BCM1_Licht_Dunkelheit_aktiv "Licht aktiv aufgrund von Dunkelheit (nicht bei Autobahn-, Tagfahr- oder Regenlicht)";
CM_ SG_ 1624 BCM1_Linksverkehr "Information über Aufbauzustand des Fzg:
0 = Scheinwerfer für Rechtsverkehr
1 = Scheinwerfer für Linksverkehr";
CM_ SG_ 1624 Licht_Vorne_01_CRC "Für MLB:
'Berechnung siehe Lastenheft 'Kommunikationsabsicherung für FlexRay und CAN''

Ab MQB und MLBevo:
'Berechnung siehe Lastenheft 'End-to-End Kommunikationsabsicherung''

Endwerte siehe Begleitdokument 'S-PDU Kennungsfolgen'";
CM_ SG_ 1624 LV_Abbiegelicht_li_def "Fehlerstatus Abbiegelicht vorne links
";
CM_ SG_ 1624 LV_Abbiegelicht_re_def "Fehlerstatus Abbiegelicht vorne rechts
";
CM_ SG_ 1624 LV_Abblend_Fernlicht_li_def "Fehlerstatus Abblendlicht und Fernlicht links ";
CM_ SG_ 1624 LV_Abblend_Fernlicht_re_def "Fehlerstatus Abblendlicht und Fernlicht rechts";
CM_ SG_ 1624 LV_Abblendlicht_Anzeige "Abblendlicht aktiv";
CM_ SG_ 1624 LV_Abblendlicht_li_def "Fehlerstatus Abblendlicht vorne links 
";
CM_ SG_ 1624 LV_Abblendlicht_re_def "Fehlerstatus Abblendlicht vorne rechts
";
CM_ SG_ 1624 LV_Abblendlicht_TFL_li_def "Fehlerstatus Abblendlicht und Tagfahrlicht links
";
CM_ SG_ 1624 LV_Abblendlicht_TFL_re_def "Fehlerstatus Abblendlicht und Tagfahrlicht rechts ";
CM_ SG_ 1624 LV_AFL_aktiv_Anzeige "Anzeige AFL-Funktion";
CM_ SG_ 1624 LV_AFL_defekt "Fehlerstatus AFL
";
CM_ SG_ 1624 LV_Aussenlicht_def "Aussenlicht kann nicht mehr korrekt angesteuert werden (EEPROM Codierung kann nicht mehr ausgelesen werden)
";
CM_ SG_ 1624 LV_Blinker_li_def "Fehlerstatus Blinker vorne links
";
CM_ SG_ 1624 LV_Blinker_re_def "Fehlerstatus Blinker vorne rechts
";
CM_ SG_ 1624 LV_Blinker_VL_aktiv "Blinker vorne links
";
CM_ SG_ 1624 LV_Blinker_VR_aktiv "Blinker vorne links
";
CM_ SG_ 1624 LV_Blk_li_Seite_def "Fehlerstatus Seitenblinker links
";
CM_ SG_ 1624 LV_Blk_re_Seite_def "Fehlerstatus Blinker Seite rechts
";
CM_ SG_ 1624 LV_Fernlicht_Anzeige "Fernlicht_aktiv";
CM_ SG_ 1624 LV_Fernlicht_li_def "Fehlerstatus Fernlicht vorne links
";
CM_ SG_ 1624 LV_Fernlicht_re_def "Fehlerstatus Fernlicht vorne rechts
";
CM_ SG_ 1624 LV_FLA_aktiv_Anzeige "Ansteuerung FLA-Lampe im Kombi (BCM1 Bedienmaster)";
CM_ SG_ 1624 LV_FLA_defekt "Fehlerstatus FLA (Anzeige des entsprechenden Fehlertext im Kombi)";
CM_ SG_ 1624 LV_FLA_Sensor_blockiert "Status FLA-Sensor (Anzeige des entsprechenden Fehlertext im Kombi)";
CM_ SG_ 1624 LV_LED_Scheinwerfer_li_def "Fehlerstatus LED-Scheinwerfer links
";
CM_ SG_ 1624 LV_LED_Scheinwerfer_re_def "Fehlerstatus LED-Scheinwerfer rechts";
CM_ SG_ 1624 LV_MXB_Status_Anzeige "Aktueller Status des Fernlichts / MxB zur Signalisierung im Kombi.";
CM_ SG_ 1624 LV_Nebellicht_Anzeige "Nebellicht_aktiv
";
CM_ SG_ 1624 LV_Nebellicht_li_def "Fehlerstatus Nebelscheinwerfer vorne links
";
CM_ SG_ 1624 LV_Nebellicht_re_def "Fehlerstatus Nebelscheinwerfer vorne rechts
";
CM_ SG_ 1624 LV_Nebellicht_TFL_li_def "Fehlerstatus Nebellicht und Tagfahrlicht links ";
CM_ SG_ 1624 LV_Nebellicht_TFL_re_def "Fehlerstatus Nebellicht und Tagfahrlicht rechts";
CM_ SG_ 1624 LV_Nebelschlusslicht_Anzeige "Nebelschlusslicht_aktiv
";
CM_ SG_ 1624 LV_Standlicht_Anzeige "Anzeige Standlicht
";
CM_ SG_ 1624 LV_Standlicht_li_def "Fehlerstatus Standlicht vorne links
";
CM_ SG_ 1624 LV_Standlicht_re_def "Fehlerstatus Standlicht vorne rechts
";
CM_ SG_ 1624 LV_Standlicht_TFL_li_def "Fehlerstatus Standlicht und Tagfahrlicht links ";
CM_ SG_ 1624 LV_Standlicht_TFL_re_def "Fehlerstatus Standlicht und Tagfahrlicht rechts ";
CM_ SG_ 1624 LV_Tagfahrlicht_Anzeige "Anzeige Tagfahrlicht
";
CM_ SG_ 1624 LV_Tagfahrlicht_li_def "Fehlerstatus Tagfahrlicht links
";
CM_ SG_ 1624 LV_Tagfahrlicht_re_def "Fehlerstatus Tagfahrlicht rechts";

CM_ SG_ 2527679633 LSH_Ansaug_Fuell_1 "Luftstandheizungsansaugtemperaturfühler 1";
CM_ SG_ 2527679633 LSH_Ansaug_Fuell_2 "Luftstandheizungsansaugtemperaturfühler 2";
CM_ SG_ 2527679633 LSH_Empf_Heizstufe "Heizstufen";
CM_ SG_ 2527679633 LSH_Funk_aus "LSH über Funksignal ausschalten";
CM_ SG_ 2527679633 LSH_Funk_ein "LSH über Funksignal einschalten";
CM_ SG_ 2527679633 LSH_Geblaese_aktiv "Anzeige der Luftstandheizung, dass das interne Gebläse aktiv ist.
0 = Gebläse inaktiv
1 = Gebläse aktiv";
CM_ SG_ 2527679633 LSH_Heiztemp "Luftheizungswärmetauschertemperatur";
CM_ SG_ 2527679633 LSH_Klappe_Status "Status Luftklappe";
CM_ SG_ 2527679633 LSH_LED "Funktionslampe Luftstandheizung";
CM_ SG_ 2527679633 LSH_Servicemode "Luftstandheizung Servicemode";
CM_ SG_ 2527679633 LSH_Start_folgt "Thema Start/Stop: Im Stop-Modus muß das KBT einen Wiederstart anfordern, da ein STH-Start notwendig ist.";
CM_ SG_ 2527679633 LSH_Texte "Anforderung der untersch. Anzeigetexte im Mitteldisplay d. Kombi.

0: Keine Anzeige
1: Kein Standheizungsbetrieb wegen Batteriemanagementeinschränkung
2: Kein Standheizungsbetrieb wegen Kraftstoffmangels
3: Kein Standheizungsbetrieb wegen internem Sy";
CM_ SG_ 2527679633 LSH_Waermeeintrag "Signal enthält die Brenndauer der Luftstandheizung in 5min-Schritten";

CM_ SG_ 917 AFS_Abbiegelicht_Dimm_Anf "Beschreibt ob das Abbiegelicht gedimmt oder hart einschalten werden soll. Dimmkurve ist Empfänger hinterlegt.";
CM_ SG_ 917 AFS_Abbiegelicht_li_Anf "Anforderung das Abbiegelicht links einzuschalten";
CM_ SG_ 917 AFS_Abbiegelicht_re_Anf "Anforderung das Abbiegelicht rechts einzuschalten";
CM_ SG_ 917 AFS_adaptive_LV_verbaut "Verfügbarkeit der adaptiven Lichtverteilung im AFS-SG.
(Das BCM steuert mit diesem Signal die Einblendung des entsprechenden Menüs)";
CM_ SG_ 917 AFS_Allwetterlicht "Status ¿Allwetterlicht¿ - Licht für schlechte Sichtverhältnisse
(bei Defekt -> nicht aktiv)";
CM_ SG_ 917 AFS_Charisma_FahrPr "MLBevo: Aktuelles Fahrprogramm des Charisma-Teilnehmers (siehe Systemlastenheft Drive Select)
MQB: Istwert der Kennlinie (siehe Systemlastenheft MQB FPA)";
CM_ SG_ 917 AFS_Charisma_Status "Charisma Systemstatus des Charisma-Teilnehmers

Wert 0x3 ist nur für Fahrzeuge ab MQB relevant";
CM_ SG_ 917 AFS_Ersatzlicht_Links "Bei aktivierter Ersatzlichtfunktion wird das Abblendlicht ausgeschaltet und eine Ersatzlichtquelle eingeschaltet (z.Zt. B7)";
CM_ SG_ 917 AFS_Ersatzlicht_Rechts "Bei aktivierter Ersatzlichtfunktion wird das Abblendlicht ausgeschaltet und eine Ersatzlichtquelle eingeschaltet (z.Zt. B7)";
CM_ SG_ 917 AFS_Fehlertext "Fehlertext wird im Kombi angezeigt (z.Zt nur bei VW)";
CM_ SG_ 917 AFS_Fernlicht_li_defekt "Beschreibt ob das Fernlicht des linken Scheinwerfers defekt ist";
CM_ SG_ 917 AFS_Fernlicht_re_defekt "Beschreibt ob das Fernlicht des rechten Scheinwerfers defekt ist";
CM_ SG_ 917 AFS_Fernlicht_Status "Beschreibt ob das Fernlicht aktiv oder inaktiv ist";
CM_ SG_ 917 AFS_Lampe "Status der Fehlerlampe: aktuell anliegender Fehlerzustand des dynamischen oder statischen Kurvenlichtes";
CM_ SG_ 917 AFS_LED_Blinkmode "Lampe soll im Warnfall mit 1Hz blinken, wenn das Bit gesetzt ist (z.Zt nur bei VW)";
CM_ SG_ 917 AFS_Status_adaptive_LV "Gibt den Status der adaptiven Lichtverteilung an";
CM_ SG_ 917 AFS_Verfuegbarkeit_GLW "Beschreibt die Verfügbarkeit der Gleitenden Leuchtweite / Fernlichtassistenz - Verfügbarkeit bedeutet, dass die Funktion Gleitende Leuchtweite möglich ist";
CM_ SG_ 917 GLW_Sensor_blockiert "Das Signal zeigt an, dass die Kamera zur Zeit keine Sicht hat. 
Verhalten wie Fernlichassisten. 
Weiterleitung des Signals vom BCM an das KOMBI";
CM_ SG_ 917 LWR_AFS_Grundeinstellung "Grundeinstellung des Abblendlichtes am Lichteinstellkasten im Service oder Bandende mit Tester erfolgt! (auch für das dynamische Kurvernlicht)";
CM_ SG_ 917 LWR_AFS_Parametrisierung "Parametrisierung wählt die Fahrzeugvariante und die AFS-Variante aus";
CM_ SG_ 917 LWR_Hoehenwert_HL "Aktueller Höhensensorwert Hinten Links
MSS LB überträgt den Aktueller Höhensensorwert Vorne Rechts.

0x7F = 0 mm";
CM_ SG_ 917 LWR_Hoehenwert_VL "Aktueller Höhensensorwert Vorne Links

0x7F = 0 mm";
CM_ SG_ 917 LWR_Initialisierungslauf "Initialisierungslauf der Schrittmotoren, erfolgt defaultmäßig beim Motorstart";
CM_ SG_ 917 LWR_Lampe "Status der Fehlerlampe: aktuell anliegender Fehlerzustand";
CM_ SG_ 917 LWR_Modus "Schnelle oder langsame Regelart der LWR";
CM_ SG_ 917 LWR_Pos_Schrittmotor "Position des Aktuators in Prozent des maximalen Stellweges; vor dem Initialisierungslauf (Motorstart) wird der Initwert ausgegeben: 
0% : tiefste Stellung (auf Block) des Schrittmotors;
100% : maximaler Verstellweg des Schrittmotors (nicht die Grenze de";
CM_ SG_ 917 LWR_Reisemodus_Texte "Anzeige der eingestellten Verkehrsart bei aktivem Touristenlicht";
CM_ SG_ 917 LWR_Sicherheitsposition "LWR Sicherheitsposition beider Scheinwerfers";
CM_ SG_ 917 LWR_Touristenmodus_aktiv "Über MMI sendet BCM1 eine Anforderung Touristenmodus an die LWR. Diese sendet als Rückmeldung an BCM1, dass der Touristenmodus aktiv geschaltet wurde";
CM_ SG_ 917 LWR_Touristenmodus_verbaut "Verfügbarkeit der Touristenfunktion im AFS/LWR-SG.
(Das BCM steuert mit diesem Signal die Einblendung des entsprechenden Menüs)";

CM_ SG_ 1153 DSSS_Warning "DSSS - Driving Safety Support System Meldungen";
CM_ SG_ 1153 MIB_ASW_Diagnose "Diagnose Rückmeldung vom MIB zu Heckradar Entry. ASW Warnton Verfügbarkeit.";
CM_ SG_ 1153 MIB_Tongenerator_PH_verfuegbar "Verfügbarkeit des Tongenerators im MIB für die Nutzung durch die Parkhilfe";
CM_ SG_ 1153 MMI_Counter_Bedienevent "Signal wird inkrementiert, wenn Bedienevent stattgefunden hat.";
CM_ SG_ 1153 MMI_Gurt_Mic_ref "Referenzsignal für das Gurtmikrofon Steuergerät zur Signalisierung ob der Downlink aktiv oder inaktiv ist";
CM_ SG_ 1153 MMI_SDS_aktiv "Signal wird gesetzt, solange die Sprachbedienung aktiv ist.";
CM_ SG_ 1153 MU_SecondDisplay "Dient zur Überwachung der zweiten LVDS Leitung.";
CM_ SG_ 1153 MU_Update_Time "Ermöglicht auslesen der Historiendaten, wann ein Update lief";
CM_ SG_ 1153 Nav_FoD_Status "FoD Status der Navigation";
CM_ SG_ 1153 ZR_AppConnect_Zustand "Ist Zustand des AppConnect Kontextes im MIB";
CM_ SG_ 1153 ZR_Kindersicherung_RSE "Sperren der Rearseat Unit (Komplette Weckfähigkeit)";
CM_ SG_ 1153 ZR_Lichter_Tag "Berechnete Kennzeichnung des Sonnenstandes über bzw. oder unter Horizont.";
CM_ SG_ 1153 ZR_LoGeWa_Event_Kombiwarnung "Event für Kombiwarnung";
CM_ SG_ 1153 ZR_Parken_Sondermodus "Rückkanal zum pilotierten Parken zur Signalisierung Status Sondermodus";
CM_ SG_ 1153 ZR_RSE_aktivieren "Weckfähigkeit der RSE";
CM_ SG_ 1153 ZR_Sta_Inszenierung "MIB sendet Status über Inszenierungssound (welcome sound) an BCM1
Zweck: Synchronisierung mit weiteren Teilnehmern der Startupinszenierung";

CM_ SG_ 2527679860 MDK_Change_Polling_Mode "Trigger um den Polling Modus zu wechseln";
CM_ SG_ 2527679860 MDK_Function_State "Status über die Funktionalität des SW-Moduls MDK.";

CM_ SG_ 1639 BFS_Fond_Bed_Ack "Bestätigung Beifahrersitzverstellung vom Fond";
CM_ SG_ 1639 BFS_FSV_ausgeklappt "Zustandssignalisierung der el. mech. Fußstütze (eingeklappt oder ausgeklappt)";
CM_ SG_ 1639 BFS_GHV_aktiv "Verstellung Gurthoehe
";
CM_ SG_ 1639 BFS_Gurtbringer_Sperre "Freigabesignal für den Gurtzubringer";
CM_ SG_ 1639 BFS_Klappfunktion_Aktiv "Lehnenklappung aktiv";
CM_ SG_ 1639 BFS_Klappfunktion_Bed_Ack "Bestätigung Beifahrersitzklappung vom Beifahrersitz";
CM_ SG_ 1639 BFS_Klappfunktion_Beschraenkung "Signalisiert eine Verstelleinschränkung des Beifahrersitz  (für BAP Visualisierung)";
CM_ SG_ 1639 BFS_Klappfunktion_Status "dient der Signalisierung für eine Verstelleinschränkung, da der Sitz sich in Ruhestellung befindet.";
CM_ SG_ 1639 BFS_Klapptisch_offen "Signalisiert eine Verstelleinschränkung des Beifahrersitz  (für BAP Visualisierung)";
CM_ SG_ 1639 BFS_KSS_Fahrt_aktiv "Komfortseitensichtfahrt (BFS)";
CM_ SG_ 1639 BFS_KSV_aktiv "Kopfstuetzenverstellung BFS
";
CM_ SG_ 1639 BFS_Lehne_nicht_verriegelt "Fahrer Sitz Lehne Verstellung Verriegelt Status

Verwendung nur im  Bentley";
CM_ SG_ 1639 BFS_LHV_aktiv "Verstellung Lordose Höhe
";
CM_ SG_ 1639 BFS_LKV_aktiv "Verstellung Lehnenkopf
";
CM_ SG_ 1639 BFS_LNV_aktiv "Verstellung Lehnenneigung
";
CM_ SG_ 1639 BFS_LWV_aktiv "Lordose W Verstellung
";
CM_ SG_ 1639 BFS_MMB_glob_stop "Abbruch Memoryverstellung";
CM_ SG_ 1639 BFS_MMB_lokal_Stop "mit dem lokal Stop moechte man, dass ein Sitz mit Pneumatik - Lordose sich im Memoryfall wie ein Sitz mit elektromechanischer Lordose verhaelt. Nur lokler Abbruch im TIP-Betrieb.";
CM_ SG_ 1639 BFS_MMB_storage "Speichern auf Memoryposition";
CM_ SG_ 1639 BFS_MMB_storage_beep "Quittierungston Sitzmemory BFS (Anforderung Kombi)

";
CM_ SG_ 1639 BFS_MMB_store "Speichern der Sitzposition
";
CM_ SG_ 1639 BFS_MMB_store_LED_on "LED für Speichern
";
CM_ SG_ 1639 BFS_MMB_tast "Memoryverstellung im Tastbetrieb";
CM_ SG_ 1639 BFS_MMB_tipp "Memoryverstellung im Tippbetrieb";
CM_ SG_ 1639 BFS_Ruhestellung_Status "dient der Signalisierung für eine Verstelleinschränkung, da der Sitz sich in Ruhestellung befindet.";
CM_ SG_ 1639 BFS_Seat_Locked "Anzeige des gesperrten Beifahrersitzes aufgrund ungültiger Sitzposition.";
CM_ SG_ 1639 BFS_SHV_aktiv "Sitzhöhenverstellung
";
CM_ SG_ 1639 BFS_Sitzfahrt_aktiv "Aktive Sitzfahrt";
CM_ SG_ 1639 BFS_Sitzsym_Fahrt_aktiv "Sitzsymetriefahrt
";
CM_ SG_ 1639 BFS_SLV_aktiv "Sitzlängsverstellung
";
CM_ SG_ 1639 BFS_SNV_aktiv "Verstellung Sitzneigung
";
CM_ SG_ 1639 BFS_STV_aktiv "Sitztiefeverstellung
";
CM_ SG_ 1639 Mem_BFS_01_BZ "4bit Botschaftszähler, wird mit jeder Sendebotschaft inkrementiert";
CM_ SG_ 1639 Mem_BFS_01_CRC "Für MLB:
Berechnung siehe Lastenheft 'Kommunikationsabsicherung für FlexRay und CAN'
Ab MQB und MLBevo:
Berechnung siehe Lastenheft 'End-to-End Kommunikationsabsicherung'

Endwerte siehe Begleitdokument 'S-PDU Kennungsfolgen'";
BA_DEF_REL_ BU_SG_REL_  "GenSigTimeoutTime" INT 0 65535;
BA_DEF_ BO_  "DiagRequest" ENUM "No", "Yes";
BA_DEF_ BO_  "DiagResponse" ENUM "No", "Yes";
BA_DEF_ BO_  "DiagState" ENUM "No", "Yes";
BA_DEF_ BO_  "GenMsgChkConstant" HEX 0 4095;
BA_DEF_ BO_  "GenMsgCycleTime" INT 0 65535;
BA_DEF_ BO_  "GenMsgCycleTimeFast" INT 0 65535;
BA_DEF_ BO_  "GenMsgDelayTime" INT 0 100000;
BA_DEF_ BO_  "GenMsgILSupport" ENUM "No", "Yes";
BA_DEF_ BO_  "GenMsgNrOfRepetition" INT 0 100;
BA_DEF_ BO_  "GenMsgPDUConstants" STRING;
BA_DEF_ BO_  "GenMsgSendType" ENUM "Cyclic", "not_used", "not_used", "not_used", "not_used", "not_used", "not_used", "IfActive", "NoMsgSendType";
BA_DEF_ BO_  "GenMsgStartDelayTime" INT 0 100000;
BA_DEF_ BO_  "NmMessage" ENUM "No", "Yes";
BA_DEF_ BO_  "NmhMessage" ENUM "No", "Yes";
BA_DEF_ BO_  "MsgType" ENUM "Application", "NM ", "NMH", "TP2.0", "ISO-TP ", "BAP", "EID", "KS", "XCP_PRE_CONFIGURED", "XCP_RUNTIME_CONFIGURED";
BA_DEF_ BO_  "VAGTP20_API" HEX 0 255;
BA_DEF_ BO_  "VAGTP20_DynConnection" ENUM "No", "Yes";
BA_DEF_ BO_  "VAGTP20_DynSetup" ENUM "No", "Yes";
BA_DEF_ BO_  "VAGTP20_StatConnection" ENUM "No", "Yes";
BA_DEF_ BO_  "CANFD_BRS" ENUM "0", "1";
BA_DEF_ BO_  "VFrameFormat" ENUM "StandardCAN", "ExtendedCAN", "reserved", "reserved", "reserved", "reserved", "reserved", "reserved", "reserved", "reserved", "reserved", "reserved", "reserved", "reserved", "StandardCAN_FD", "ExtendedCAN_FD";
BA_DEF_ SG_  "GenSigActiveRepetitions" INT -2147483648 2147483647;
BA_DEF_ SG_  "GenSigInactiveValue" INT -2147483648 2147483647;
BA_DEF_ SG_  "GenSigSendType" ENUM "Cyclic", "OnWrite", "OnWriteWithRepetition", "OnChange", "OnChangeWithRepetition", "IfActive", "IfActiveWithRepetition", "NoSigSendType", "OnChangeAndIfActive", "OnChangeAndIfActiveWithRepetition";
BA_DEF_ SG_  "GenSigStartValue" INT -2147483648 2147483647;
BA_DEF_ SG_  "NWM-WakeupAllowed" ENUM "No", "Yes";
BA_DEF_ SG_  "GenSigFuncType" ENUM "NoFunction", "MsgCounter", "CRC-8", "XOR", "XOR-2", "DatedBit", "SW-Kl15", "CHK", "Constant", "Protocol", "CRC-8-SAE_J1850", "CRC-32", "DataLength", "DataID", "MsgCounter16", "SOK-Signatur", "Cluster";
BA_DEF_ SG_  "GenSigSwitchedByIgnition" ENUM "No", "Yes";
BA_DEF_ SG_  "Fehlerwert" HEX 0 2147483647;
BA_DEF_ SG_  "GenSigMissingSourceValue" HEX 0 2147483647;
BA_DEF_DEF_REL_  "GenSigTimeoutTime" 0;
BA_DEF_DEF_  "DiagRequest" "No";
BA_DEF_DEF_  "DiagResponse" "No";
BA_DEF_DEF_  "DiagState" "No";
BA_DEF_DEF_  "GenMsgChkConstant" 0;
BA_DEF_DEF_  "GenMsgCycleTime" 0;
BA_DEF_DEF_  "GenMsgCycleTimeFast" 0;
BA_DEF_DEF_  "GenMsgDelayTime" 0;
BA_DEF_DEF_  "GenMsgILSupport" "No";
BA_DEF_DEF_  "GenMsgNrOfRepetition" 0;
BA_DEF_DEF_  "GenMsgPDUConstants" "";
BA_DEF_DEF_  "GenMsgSendType" "NoMsgSendType";
BA_DEF_DEF_  "GenMsgStartDelayTime" 0;
BA_DEF_DEF_  "NmMessage" "No";
BA_DEF_DEF_  "NmhMessage" "No";
BA_DEF_DEF_  "MsgType" "Application";
BA_DEF_DEF_  "VAGTP20_API" 0;
BA_DEF_DEF_  "VAGTP20_DynConnection" "No";
BA_DEF_DEF_  "VAGTP20_DynSetup" "No";
BA_DEF_DEF_  "VAGTP20_StatConnection" "No";
BA_DEF_DEF_  "CANFD_BRS" "1";
BA_DEF_DEF_  "VFrameFormat" "StandardCAN";
BA_DEF_DEF_  "GenSigActiveRepetitions" 0;
BA_DEF_DEF_  "GenSigInactiveValue" 0;
BA_DEF_DEF_  "GenSigSendType" "NoSigSendType";
BA_DEF_DEF_  "GenSigStartValue" 0;
BA_DEF_DEF_  "NWM-WakeupAllowed" "No";
BA_DEF_DEF_  "GenSigFuncType" "NoFunction";
BA_DEF_DEF_  "GenSigSwitchedByIgnition" "Yes";
BA_DEF_DEF_  "Fehlerwert" 0;
BA_DEF_DEF_  "GenSigMissingSourceValue" 0;
BA_ "GenMsgCycleTime" BO_ 2549088319 500;
BA_ "GenMsgILSupport" BO_ 2549088319 1;
BA_ "GenMsgSendType" BO_ 2549088319 0;
BA_ "CANFD_BRS" BO_ 2549088319 0;
BA_ "VFrameFormat" BO_ 2549088319 15;
BA_ "GenMsgCycleTime" BO_ 2549088318 500;
BA_ "GenMsgILSupport" BO_ 2549088318 1;
BA_ "GenMsgSendType" BO_ 2549088318 0;
BA_ "CANFD_BRS" BO_ 2549088318 0;
BA_ "VFrameFormat" BO_ 2549088318 15;
BA_ "GenMsgCycleTime" BO_ 2549088421 500;
BA_ "GenMsgILSupport" BO_ 2549088421 1;
BA_ "GenMsgSendType" BO_ 2549088421 0;
BA_ "CANFD_BRS" BO_ 2549088421 0;
BA_ "VFrameFormat" BO_ 2549088421 15;
BA_ "GenMsgCycleTime" BO_ 779 50;
BA_ "GenMsgILSupport" BO_ 779 1;
BA_ "GenMsgSendType" BO_ 779 0;
BA_ "CANFD_BRS" BO_ 779 0;
BA_ "VFrameFormat" BO_ 779 14;
BA_ "GenMsgCycleTime" BO_ 1719 1000;
BA_ "GenMsgDelayTime" BO_ 1719 100;
BA_ "GenMsgILSupport" BO_ 1719 1;
BA_ "GenMsgSendType" BO_ 1719 0;
BA_ "CANFD_BRS" BO_ 1719 0;
BA_ "VFrameFormat" BO_ 1719 14;
BA_ "GenMsgCycleTime" BO_ 1720 1000;
BA_ "GenMsgILSupport" BO_ 1720 1;
BA_ "GenMsgSendType" BO_ 1720 0;
BA_ "CANFD_BRS" BO_ 1720 0;
BA_ "VFrameFormat" BO_ 1720 14;
BA_ "GenMsgCycleTime" BO_ 1722 1000;
BA_ "GenMsgSendType" BO_ 1722 0;
BA_ "CANFD_BRS" BO_ 1722 0;
BA_ "VFrameFormat" BO_ 1722 14;
BA_ "GenMsgCycleTime" BO_ 2527679639 1000;
BA_ "GenMsgCycleTimeFast" BO_ 2527679639 100;
BA_ "GenMsgDelayTime" BO_ 2527679639 100;
BA_ "GenMsgILSupport" BO_ 2527679639 1;
BA_ "GenMsgNrOfRepetition" BO_ 2527679639 5;
BA_ "GenMsgSendType" BO_ 2527679639 0;
BA_ "CANFD_BRS" BO_ 2527679639 0;
BA_ "VFrameFormat" BO_ 2527679639 15;
BA_ "GenMsgCycleTime" BO_ 1614 1000;
BA_ "GenMsgDelayTime" BO_ 1614 20;
BA_ "GenMsgILSupport" BO_ 1614 1;
BA_ "GenMsgSendType" BO_ 1614 0;
BA_ "CANFD_BRS" BO_ 1614 0;
BA_ "VFrameFormat" BO_ 1614 14;
BA_ "MsgType" BO_ 2621440270 4;
BA_ "CANFD_BRS" BO_ 2621440270 0;
BA_ "VFrameFormat" BO_ 2621440270 15;
BA_ "MsgType" BO_ 2621571342 4;
BA_ "CANFD_BRS" BO_ 2621571342 0;
BA_ "VFrameFormat" BO_ 2621571342 15;
BA_ "GenMsgCycleTime" BO_ 1387 200;
BA_ "GenMsgILSupport" BO_ 1387 1;
BA_ "GenMsgPDUConstants" BO_ 1387 "0x37,0x11,0x60,0x17,0x81,0xbb,0x2c,0xaa,0xf1,0xd0,0x34,0x83,0x2e,0xe1,0xf9,0x8e";
BA_ "GenMsgSendType" BO_ 1387 0;
BA_ "CANFD_BRS" BO_ 1387 0;
BA_ "VFrameFormat" BO_ 1387 14;
BA_ "GenMsgCycleTime" BO_ 1388 200;
BA_ "GenMsgILSupport" BO_ 1388 1;
BA_ "GenMsgPDUConstants" BO_ 1388 "0x71,0xf9,0x43,0x22,0xe4,0xa9,0x1c,0x67,0x2b,0x16,0x7f,0x15,0xe0,0x97,0x20,0x4e";
BA_ "GenMsgSendType" BO_ 1388 0;
BA_ "CANFD_BRS" BO_ 1388 0;
BA_ "VFrameFormat" BO_ 1388 14;
BA_ "GenMsgCycleTime" BO_ 403 100;
BA_ "GenMsgDelayTime" BO_ 403 10;
BA_ "GenMsgILSupport" BO_ 403 1;
BA_ "GenMsgPDUConstants" BO_ 403 "0xbd,0x44,0x90,0x8d,0x74,0xfa,0x91,0x89,0x41,0x4a,0xbe,0x82,0xb3,0x05,0x84,0xcf";
BA_ "GenMsgSendType" BO_ 403 0;
BA_ "CANFD_BRS" BO_ 403 0;
BA_ "VFrameFormat" BO_ 403 14;
BA_ "GenMsgCycleTime" BO_ 411 100;
BA_ "GenMsgDelayTime" BO_ 411 10;
BA_ "GenMsgILSupport" BO_ 411 1;
BA_ "GenMsgPDUConstants" BO_ 411 "0x8c,0x9c,0xb7,0x80,0xd8,0x98,0x32,0x5c,0xdd,0xc3,0x44,0xb9,0xb2,0xa8,0xd9,0xce";
BA_ "GenMsgSendType" BO_ 411 0;
BA_ "CANFD_BRS" BO_ 411 0;
BA_ "VFrameFormat" BO_ 411 14;
BA_ "GenMsgCycleTime" BO_ 413 100;
BA_ "GenMsgDelayTime" BO_ 413 10;
BA_ "GenMsgILSupport" BO_ 413 1;
BA_ "GenMsgPDUConstants" BO_ 413 "0x4b,0xdb,0xbe,0x71,0xa6,0x31,0x56,0xf9,0xc8,0x26,0xe3,0x43,0x0a,0x6d,0x29,0x22";
BA_ "GenMsgSendType" BO_ 413 0;
BA_ "CANFD_BRS" BO_ 413 0;
BA_ "VFrameFormat" BO_ 413 14;
BA_ "GenMsgCycleTime" BO_ 2527679510 200;
BA_ "GenMsgILSupport" BO_ 2527679510 1;
BA_ "GenMsgPDUConstants" BO_ 2527679510 "0xb0,0x69,0xef,0x08,0xcc,0x05,0x20,0x48,0x9a,0x4c,0x8f,0xbb,0x67,0xf3,0x39,0x52";
BA_ "GenMsgSendType" BO_ 2527679510 0;
BA_ "CANFD_BRS" BO_ 2527679510 0;
BA_ "VFrameFormat" BO_ 2527679510 15;
BA_ "GenMsgCycleTime" BO_ 2527679511 200;
BA_ "GenMsgILSupport" BO_ 2527679511 1;
BA_ "GenMsgPDUConstants" BO_ 2527679511 "0xd8,0x0e,0xdc,0xc5,0x36,0x8c,0x30,0xa4,0xc0,0x79,0x71,0xb3,0x6b,0x25,0x89,0x8b";
BA_ "GenMsgSendType" BO_ 2527679511 0;
BA_ "CANFD_BRS" BO_ 2527679511 0;
BA_ "VFrameFormat" BO_ 2527679511 15;
BA_ "GenMsgCycleTime" BO_ 981 100;
BA_ "GenMsgDelayTime" BO_ 981 50;
BA_ "GenMsgILSupport" BO_ 981 1;
BA_ "GenMsgPDUConstants" BO_ 981 "0xc5,0x39,0xc7,0xf9,0x92,0xd8,0x24,0xce,0xf1,0xb5,0x7a,0xc4,0xbc,0x60,0xe3,0xd1";
BA_ "GenMsgSendType" BO_ 981 0;
BA_ "CANFD_BRS" BO_ 981 0;
BA_ "VFrameFormat" BO_ 981 14;
BA_ "GenMsgCycleTime" BO_ 982 100;
BA_ "GenMsgDelayTime" BO_ 982 20;
BA_ "GenMsgILSupport" BO_ 982 1;
BA_ "GenMsgSendType" BO_ 982 0;
BA_ "CANFD_BRS" BO_ 982 0;
BA_ "VFrameFormat" BO_ 982 14;
BA_ "GenMsgCycleTime" BO_ 1624 1000;
BA_ "GenMsgDelayTime" BO_ 1624 50;
BA_ "GenMsgILSupport" BO_ 1624 1;
BA_ "GenMsgPDUConstants" BO_ 1624 "0x46,0x0f,0xe0,0xcc,0xbe,0xb1,0xd7,0xf1,0x1f,0x31,0xc1,0x25,0xb4,0x3e,0xc8,0xa3";
BA_ "GenMsgSendType" BO_ 1624 0;
BA_ "CANFD_BRS" BO_ 1624 0;
BA_ "VFrameFormat" BO_ 1624 14;
BA_ "GenMsgCycleTime" BO_ 2527679633 200;
BA_ "GenMsgILSupport" BO_ 2527679633 1;
BA_ "GenMsgSendType" BO_ 2527679633 0;
BA_ "CANFD_BRS" BO_ 2527679633 0;
BA_ "VFrameFormat" BO_ 2527679633 15;
BA_ "GenMsgCycleTime" BO_ 917 100;
BA_ "GenMsgDelayTime" BO_ 917 10;
BA_ "GenMsgILSupport" BO_ 917 1;
BA_ "GenMsgSendType" BO_ 917 0;
BA_ "CANFD_BRS" BO_ 917 0;
BA_ "VFrameFormat" BO_ 917 14;
BA_ "GenMsgCycleTime" BO_ 1153 500;
BA_ "GenMsgCycleTimeFast" BO_ 1153 50;
BA_ "GenMsgDelayTime" BO_ 1153 50;
BA_ "GenMsgILSupport" BO_ 1153 1;
BA_ "GenMsgNrOfRepetition" BO_ 1153 5;
BA_ "GenMsgSendType" BO_ 1153 0;
BA_ "CANFD_BRS" BO_ 1153 0;
BA_ "VFrameFormat" BO_ 1153 14;
BA_ "GenMsgCycleTime" BO_ 2527679860 200;
BA_ "GenMsgILSupport" BO_ 2527679860 1;
BA_ "GenMsgSendType" BO_ 2527679860 0;
BA_ "CANFD_BRS" BO_ 2527679860 0;
BA_ "VFrameFormat" BO_ 2527679860 15;
BA_ "GenMsgCycleTime" BO_ 1639 100;
BA_ "GenMsgDelayTime" BO_ 1639 50;
BA_ "GenMsgILSupport" BO_ 1639 1;
BA_ "GenMsgPDUConstants" BO_ 1639 "0x65,0x98,0x5a,0x75,0xc8,0xc2,0xb1,0x73,0xa5,0xf4,0x72,0xf2,0x8d,0x20,0x9b,0x78";
BA_ "GenMsgSendType" BO_ 1639 0;
BA_ "CANFD_BRS" BO_ 1639 0;
BA_ "VFrameFormat" BO_ 1639 14;
BA_ "GenSigSendType" SG_ 2549088319 KN_TSG_HBFS_BusKnockOut 0;
BA_ "GenSigSwitchedByIgnition" SG_ 2549088319 KN_TSG_HBFS_BusKnockOut 0;
BA_ "GenSigSendType" SG_ 2549088319 KN_TSG_HBFS_BusKnockOutTimer 0;
BA_ "GenSigSwitchedByIgnition" SG_ 2549088319 KN_TSG_HBFS_BusKnockOutTimer 0;
BA_ "GenSigSendType" SG_ 2549088319 KN_TSG_HBFS_DiagPfad 0;
BA_ "GenSigSwitchedByIgnition" SG_ 2549088319 KN_TSG_HBFS_DiagPfad 0;
BA_ "GenSigSendType" SG_ 2549088319 KN_TSG_HBFS_ECUKnockOut 0;
BA_ "GenSigSwitchedByIgnition" SG_ 2549088319 KN_TSG_HBFS_ECUKnockOut 0;
BA_ "GenSigSendType" SG_ 2549088319 KN_TSG_HBFS_ECUKnockOutTimer 0;
BA_ "GenSigSwitchedByIgnition" SG_ 2549088319 KN_TSG_HBFS_ECUKnockOutTimer 0;
BA_ "GenSigSendType" SG_ 2549088319 NM_TSG_HBFS_Wakeup 0;
BA_ "GenSigSwitchedByIgnition" SG_ 2549088319 NM_TSG_HBFS_Wakeup 0;
BA_ "GenSigSendType" SG_ 2549088319 TSG_HBFS_Abschaltstufe 0;
BA_ "GenSigSwitchedByIgnition" SG_ 2549088319 TSG_HBFS_Abschaltstufe 0;
BA_ "GenSigSendType" SG_ 2549088319 TSG_HBFS_KD_Fehler 0;
BA_ "GenSigSwitchedByIgnition" SG_ 2549088319 TSG_HBFS_KD_Fehler 0;
BA_ "GenSigSendType" SG_ 2549088319 TSG_HBFS_KompSchutz 0;
BA_ "GenSigSwitchedByIgnition" SG_ 2549088319 TSG_HBFS_KompSchutz 0;
BA_ "GenSigSendType" SG_ 2549088319 TSG_HBFS_Nachlauftyp 0;
BA_ "GenSigStartValue" SG_ 2549088319 TSG_HBFS_Nachlauftyp 2;
BA_ "GenSigSwitchedByIgnition" SG_ 2549088319 TSG_HBFS_Nachlauftyp 0;
BA_ "GenSigSendType" SG_ 2549088319 TSG_HBFS_Transport_Mode 0;
BA_ "GenSigSwitchedByIgnition" SG_ 2549088319 TSG_HBFS_Transport_Mode 0;
BA_ "GenSigSendType" SG_ 2549088318 KN_TSG_HFS_BusKnockOut 0;
BA_ "GenSigSwitchedByIgnition" SG_ 2549088318 KN_TSG_HFS_BusKnockOut 0;
BA_ "GenSigSendType" SG_ 2549088318 KN_TSG_HFS_BusKnockOutTimer 0;
BA_ "GenSigSwitchedByIgnition" SG_ 2549088318 KN_TSG_HFS_BusKnockOutTimer 0;
BA_ "GenSigSendType" SG_ 2549088318 KN_TSG_HFS_DiagPfad 0;
BA_ "GenSigSwitchedByIgnition" SG_ 2549088318 KN_TSG_HFS_DiagPfad 0;
BA_ "GenSigSendType" SG_ 2549088318 KN_TSG_HFS_ECUKnockOut 0;
BA_ "GenSigSwitchedByIgnition" SG_ 2549088318 KN_TSG_HFS_ECUKnockOut 0;
BA_ "GenSigSendType" SG_ 2549088318 KN_TSG_HFS_ECUKnockOutTimer 0;
BA_ "GenSigSwitchedByIgnition" SG_ 2549088318 KN_TSG_HFS_ECUKnockOutTimer 0;
BA_ "GenSigSendType" SG_ 2549088318 NM_TSG_HFS_Wakeup 0;
BA_ "GenSigSwitchedByIgnition" SG_ 2549088318 NM_TSG_HFS_Wakeup 0;
BA_ "GenSigSendType" SG_ 2549088318 TSG_HFS_Abschaltstufe 0;
BA_ "GenSigSwitchedByIgnition" SG_ 2549088318 TSG_HFS_Abschaltstufe 0;
BA_ "GenSigSendType" SG_ 2549088318 TSG_HFS_KD_Fehler 0;
BA_ "GenSigSwitchedByIgnition" SG_ 2549088318 TSG_HFS_KD_Fehler 0;
BA_ "GenSigSendType" SG_ 2549088318 TSG_HFS_KompSchutz 0;
BA_ "GenSigSwitchedByIgnition" SG_ 2549088318 TSG_HFS_KompSchutz 0;
BA_ "GenSigSendType" SG_ 2549088318 TSG_HFS_Nachlauftyp 0;
BA_ "GenSigStartValue" SG_ 2549088318 TSG_HFS_Nachlauftyp 2;
BA_ "GenSigSwitchedByIgnition" SG_ 2549088318 TSG_HFS_Nachlauftyp 0;
BA_ "GenSigSendType" SG_ 2549088318 TSG_HFS_Transport_Mode 0;
BA_ "GenSigSwitchedByIgnition" SG_ 2549088318 TSG_HFS_Transport_Mode 0;
BA_ "GenSigSendType" SG_ 2549088421 KN_WLC1_BusKnockOut 0;
BA_ "GenSigSwitchedByIgnition" SG_ 2549088421 KN_WLC1_BusKnockOut 0;
BA_ "GenSigSendType" SG_ 2549088421 KN_WLC1_BusKnockOutTimer 0;
BA_ "GenSigSwitchedByIgnition" SG_ 2549088421 KN_WLC1_BusKnockOutTimer 0;
BA_ "GenSigSendType" SG_ 2549088421 KN_WLC1_DiagPfad 0;
BA_ "GenSigSwitchedByIgnition" SG_ 2549088421 KN_WLC1_DiagPfad 0;
BA_ "GenSigSendType" SG_ 2549088421 KN_WLC1_ECUKnockOut 0;
BA_ "GenSigSwitchedByIgnition" SG_ 2549088421 KN_WLC1_ECUKnockOut 0;
BA_ "GenSigSendType" SG_ 2549088421 KN_WLC1_ECUKnockOutTimer 0;
BA_ "GenSigSwitchedByIgnition" SG_ 2549088421 KN_WLC1_ECUKnockOutTimer 0;
BA_ "GenSigSendType" SG_ 2549088421 NM_WLC1_Wakeup 0;
BA_ "GenSigSwitchedByIgnition" SG_ 2549088421 NM_WLC1_Wakeup 0;
BA_ "GenSigSendType" SG_ 2549088421 WLC1_Abschaltstufe 0;
BA_ "GenSigSwitchedByIgnition" SG_ 2549088421 WLC1_Abschaltstufe 0;
BA_ "GenSigSendType" SG_ 2549088421 WLC1_KD_Fehler 0;
BA_ "GenSigSwitchedByIgnition" SG_ 2549088421 WLC1_KD_Fehler 0;
BA_ "GenSigSendType" SG_ 2549088421 WLC1_KompSchutz 0;
BA_ "GenSigSwitchedByIgnition" SG_ 2549088421 WLC1_KompSchutz 0;
BA_ "GenSigSendType" SG_ 2549088421 WLC1_Nachlauftyp 0;
BA_ "GenSigStartValue" SG_ 2549088421 WLC1_Nachlauftyp 2;
BA_ "GenSigSwitchedByIgnition" SG_ 2549088421 WLC1_Nachlauftyp 0;
BA_ "GenSigSendType" SG_ 2549088421 WLC1_Transport_Mode 0;
BA_ "GenSigSwitchedByIgnition" SG_ 2549088421 WLC1_Transport_Mode 0;
BA_ "GenSigSendType" SG_ 779 KBI_ABS_Lampe 0;
BA_ "GenSigSwitchedByIgnition" SG_ 779 KBI_ABS_Lampe 0;
BA_ "GenSigSendType" SG_ 779 KBI_Airbag_Lampe 0;
BA_ "GenSigSwitchedByIgnition" SG_ 779 KBI_Airbag_Lampe 0;
BA_ "GenSigSendType" SG_ 779 KBI_angez_Geschw 0;
BA_ "GenSigSwitchedByIgnition" SG_ 779 KBI_angez_Geschw 0;
BA_ "GenSigSendType" SG_ 779 KBI_Anzeigefehler_LDW 0;
BA_ "GenSigSwitchedByIgnition" SG_ 779 KBI_Anzeigefehler_LDW 0;
BA_ "GenSigSendType" SG_ 779 KBI_Anzeigefehler_NV 0;
BA_ "GenSigSwitchedByIgnition" SG_ 779 KBI_Anzeigefehler_NV 0;
BA_ "GenSigSendType" SG_ 779 KBI_Anzeigefehler_SWA 0;
BA_ "GenSigSwitchedByIgnition" SG_ 779 KBI_Anzeigefehler_SWA 0;
BA_ "GenSigSendType" SG_ 779 KBI_Anzeigestatus_ACC 0;
BA_ "GenSigSwitchedByIgnition" SG_ 779 KBI_Anzeigestatus_ACC 0;
BA_ "GenSigSendType" SG_ 779 KBI_Anzeigestatus_GRA 0;
BA_ "GenSigSwitchedByIgnition" SG_ 779 KBI_Anzeigestatus_GRA 0;
BA_ "Fehlerwert" SG_ 779 KBI_Anzeigestatus_GRA 3;
BA_ "GenSigSendType" SG_ 779 KBI_Anzeigestatus_LIM 0;
BA_ "GenSigSwitchedByIgnition" SG_ 779 KBI_Anzeigestatus_LIM 0;
BA_ "Fehlerwert" SG_ 779 KBI_Anzeigestatus_LIM 3;
BA_ "GenSigSendType" SG_ 779 KBI_Anzeigestatus_RHP 0;
BA_ "GenSigSwitchedByIgnition" SG_ 779 KBI_Anzeigestatus_RHP 0;
BA_ "GenSigSendType" SG_ 779 KBI_ARA_in_Anzeige 0;
BA_ "GenSigSwitchedByIgnition" SG_ 779 KBI_ARA_in_Anzeige 0;
BA_ "GenSigSendType" SG_ 779 KBI_Audioabsenkung_MIB 0;
BA_ "GenSigSwitchedByIgnition" SG_ 779 KBI_Audioabsenkung_MIB 0;
BA_ "GenSigSendType" SG_ 779 KBI_Bestaetigung_ESP_Off 0;
BA_ "GenSigSwitchedByIgnition" SG_ 779 KBI_Bestaetigung_ESP_Off 0;
BA_ "GenSigSendType" SG_ 779 KBI_BKL_Lampe 0;
BA_ "GenSigSwitchedByIgnition" SG_ 779 KBI_BKL_Lampe 0;
BA_ "GenSigSendType" SG_ 779 KBI_ESP_Lampe 0;
BA_ "GenSigSwitchedByIgnition" SG_ 779 KBI_ESP_Lampe 0;
BA_ "GenSigSendType" SG_ 779 KBI_Fehler_Anzeige_ACC 0;
BA_ "GenSigSwitchedByIgnition" SG_ 779 KBI_Fehler_Anzeige_ACC 0;
BA_ "GenSigSendType" SG_ 779 KBI_Handbremse 0;
BA_ "GenSigSwitchedByIgnition" SG_ 779 KBI_Handbremse 0;
BA_ "GenSigSendType" SG_ 779 KBI_im_Stellgliedtest 0;
BA_ "GenSigSwitchedByIgnition" SG_ 779 KBI_im_Stellgliedtest 0;
BA_ "GenSigSendType" SG_ 779 KBI_Konsistenz_ACC 0;
BA_ "GenSigSwitchedByIgnition" SG_ 779 KBI_Konsistenz_ACC 0;
BA_ "GenSigSendType" SG_ 779 KBI_Lenkung_Lampe 0;
BA_ "GenSigSwitchedByIgnition" SG_ 779 KBI_Lenkung_Lampe 0;
BA_ "GenSigSendType" SG_ 779 KBI_MFA_v_Einheit_01 0;
BA_ "GenSigSwitchedByIgnition" SG_ 779 KBI_MFA_v_Einheit_01 0;
BA_ "GenSigSendType" SG_ 779 KBI_NV_in_Anzeige 0;
BA_ "GenSigSwitchedByIgnition" SG_ 779 KBI_NV_in_Anzeige 0;
BA_ "GenSigSendType" SG_ 779 KBI_Oeldruck_Schalter 0;
BA_ "GenSigSwitchedByIgnition" SG_ 779 KBI_Oeldruck_Schalter 0;
BA_ "GenSigSendType" SG_ 779 KBI_Oeldruckwarnung 0;
BA_ "GenSigSwitchedByIgnition" SG_ 779 KBI_Oeldruckwarnung 0;
BA_ "GenSigSendType" SG_ 779 KBI_PLA_in_Anzeige 0;
BA_ "GenSigSwitchedByIgnition" SG_ 779 KBI_PLA_in_Anzeige 0;
BA_ "GenSigSendType" SG_ 779 KBI_SILA_gueltig 0;
BA_ "GenSigSwitchedByIgnition" SG_ 779 KBI_SILA_gueltig 0;
BA_ "GenSigSendType" SG_ 779 KBI_Systemstatus 0;
BA_ "GenSigSwitchedByIgnition" SG_ 779 KBI_Systemstatus 0;
BA_ "GenSigSendType" SG_ 779 KBI_Tankwarnung 0;
BA_ "GenSigSwitchedByIgnition" SG_ 779 KBI_Tankwarnung 0;
BA_ "GenSigSendType" SG_ 779 KBI_Tankwarnung_ungueltig 0;
BA_ "GenSigStartValue" SG_ 779 KBI_Tankwarnung_ungueltig 1;
BA_ "GenSigSwitchedByIgnition" SG_ 779 KBI_Tankwarnung_ungueltig 0;
BA_ "GenSigSendType" SG_ 779 KBI_Taster_Fahrwerk 0;
BA_ "GenSigSwitchedByIgnition" SG_ 779 KBI_Taster_Fahrwerk 0;
BA_ "GenSigSendType" SG_ 779 KBI_Taster_Lift 0;
BA_ "GenSigSwitchedByIgnition" SG_ 779 KBI_Taster_Lift 0;
BA_ "GenSigSendType" SG_ 779 KBI_V_Digital 0;
BA_ "GenSigSwitchedByIgnition" SG_ 779 KBI_V_Digital 0;
BA_ "GenSigSendType" SG_ 779 KBI_Vorglueh_System_Lampe 0;
BA_ "GenSigSwitchedByIgnition" SG_ 779 KBI_Vorglueh_System_Lampe 0;
BA_ "GenSigSendType" SG_ 779 Kombi_01_BZ 0;
BA_ "GenSigFuncType" SG_ 779 Kombi_01_BZ 1;
BA_ "GenSigSwitchedByIgnition" SG_ 779 Kombi_01_BZ 0;
BA_ "GenSigSendType" SG_ 1719 KBI_aktive_Laengsfunktion_02 3;
BA_ "GenSigSendType" SG_ 1719 KBI_Aussen_Temp_gef 0;
BA_ "GenSigStartValue" SG_ 1719 KBI_Aussen_Temp_gef 254;
BA_ "GenSigSwitchedByIgnition" SG_ 1719 KBI_Aussen_Temp_gef 0;
BA_ "Fehlerwert" SG_ 1719 KBI_Aussen_Temp_gef 255;
BA_ "GenSigSendType" SG_ 1719 KBI_FoD_PopUP_Quittiert 3;
BA_ "GenSigSendType" SG_ 1719 KBI_FStatus_Tank 0;
BA_ "GenSigSwitchedByIgnition" SG_ 1719 KBI_FStatus_Tank 0;
BA_ "GenSigSendType" SG_ 1719 KBI_GRA_im_ACC 3;
BA_ "GenSigSwitchedByIgnition" SG_ 1719 KBI_GRA_im_ACC 0;
BA_ "GenSigSendType" SG_ 1719 KBI_Inhalt_Tank 0;
BA_ "GenSigStartValue" SG_ 1719 KBI_Inhalt_Tank 126;
BA_ "GenSigSwitchedByIgnition" SG_ 1719 KBI_Inhalt_Tank 0;
BA_ "Fehlerwert" SG_ 1719 KBI_Inhalt_Tank 127;
BA_ "GenSigSendType" SG_ 1719 KBI_Kilometerstand 0;
BA_ "GenSigStartValue" SG_ 1719 KBI_Kilometerstand 1048574;
BA_ "GenSigSwitchedByIgnition" SG_ 1719 KBI_Kilometerstand 0;
BA_ "Fehlerwert" SG_ 1719 KBI_Kilometerstand 1048575;
BA_ "GenSigSendType" SG_ 1719 KBI_Oelwechsel_durchgefuehrt 0;
BA_ "GenSigSwitchedByIgnition" SG_ 1719 KBI_Oelwechsel_durchgefuehrt 0;
BA_ "GenSigSendType" SG_ 1719 KBI_QBit_Aussen_Temp_gef 0;
BA_ "GenSigStartValue" SG_ 1719 KBI_QBit_Aussen_Temp_gef 1;
BA_ "GenSigSwitchedByIgnition" SG_ 1719 KBI_QBit_Aussen_Temp_gef 0;
BA_ "GenSigSendType" SG_ 1719 KBI_RDK_Kalibrier_Anf 3;
BA_ "GenSigSwitchedByIgnition" SG_ 1719 KBI_RDK_Kalibrier_Anf 0;
BA_ "GenSigSendType" SG_ 1719 KBI_Reserve_Warnung_Sek 3;
BA_ "GenSigSwitchedByIgnition" SG_ 1719 KBI_Reserve_Warnung_Sek 0;
BA_ "GenSigSendType" SG_ 1719 KBI_Standzeit_02 0;
BA_ "GenSigStartValue" SG_ 1719 KBI_Standzeit_02 131070;
BA_ "GenSigSwitchedByIgnition" SG_ 1719 KBI_Standzeit_02 0;
BA_ "Fehlerwert" SG_ 1719 KBI_Standzeit_02 131071;
BA_ "GenSigSendType" SG_ 1720 KBI_BCmE_aktiv 0;
BA_ "GenSigSwitchedByIgnition" SG_ 1720 KBI_BCmE_aktiv 0;
BA_ "GenSigSendType" SG_ 1720 KBI_GAP_Warn_Zeit_abgelaufen 0;
BA_ "GenSigSwitchedByIgnition" SG_ 1720 KBI_GAP_Warn_Zeit_abgelaufen 0;
BA_ "GenSigSendType" SG_ 1720 KBI_Max_Tankinhalt 0;
BA_ "GenSigStartValue" SG_ 1720 KBI_Max_Tankinhalt 254;
BA_ "GenSigSwitchedByIgnition" SG_ 1720 KBI_Max_Tankinhalt 0;
BA_ "Fehlerwert" SG_ 1720 KBI_Max_Tankinhalt 255;
BA_ "GenSigSendType" SG_ 1720 KBI_Nachtanken_erkannt 0;
BA_ "GenSigSwitchedByIgnition" SG_ 1720 KBI_Nachtanken_erkannt 0;
BA_ "GenSigSendType" SG_ 1720 KBI_Quittierung_cAQP 0;
BA_ "GenSigSwitchedByIgnition" SG_ 1720 KBI_Quittierung_cAQP 0;
BA_ "GenSigSendType" SG_ 1720 KBI_Quittierung_Naesse 0;
BA_ "GenSigSwitchedByIgnition" SG_ 1720 KBI_Quittierung_Naesse 0;
BA_ "GenSigSendType" SG_ 1720 KBI_Reifenumfang 0;
BA_ "GenSigFuncType" SG_ 1720 KBI_Reifenumfang 8;
BA_ "GenSigSwitchedByIgnition" SG_ 1720 KBI_Reifenumfang 0;
BA_ "GenSigSendType" SG_ 1720 KBI_Reifenumfang_Sekundaer 0;
BA_ "GenSigSwitchedByIgnition" SG_ 1720 KBI_Reifenumfang_Sekundaer 0;
BA_ "GenSigSendType" SG_ 1720 KBI_Sparhinweis_quittiert 0;
BA_ "GenSigSwitchedByIgnition" SG_ 1720 KBI_Sparhinweis_quittiert 0;
BA_ "GenSigSendType" SG_ 1720 KBI_Tankfuellstand_Prozent 0;
BA_ "GenSigStartValue" SG_ 1720 KBI_Tankfuellstand_Prozent 126;
BA_ "GenSigSwitchedByIgnition" SG_ 1720 KBI_Tankfuellstand_Prozent 0;
BA_ "Fehlerwert" SG_ 1720 KBI_Tankfuellstand_Prozent 127;
BA_ "GenSigSendType" SG_ 1720 KBI_Tankinhalt_hochaufl 0;
BA_ "GenSigStartValue" SG_ 1720 KBI_Tankinhalt_hochaufl 16382;
BA_ "GenSigSwitchedByIgnition" SG_ 1720 KBI_Tankinhalt_hochaufl 0;
BA_ "Fehlerwert" SG_ 1720 KBI_Tankinhalt_hochaufl 16383;
BA_ "GenSigSendType" SG_ 1720 KBI_Variante 0;
BA_ "GenSigSwitchedByIgnition" SG_ 1720 KBI_Variante 0;
BA_ "GenSigSendType" SG_ 1720 KBI_Variante_USA 0;
BA_ "GenSigSwitchedByIgnition" SG_ 1720 KBI_Variante_USA 0;
BA_ "GenSigSendType" SG_ 1722 SOK_Kombi_03_Signatur 0;
BA_ "GenSigFuncType" SG_ 1722 SOK_Kombi_03_Signatur 15;
BA_ "GenSigSwitchedByIgnition" SG_ 1722 SOK_Kombi_03_Signatur 0;
BA_ "GenSigSendType" SG_ 2527679639 AuthTime_Trigger_Distribution 4;
BA_ "GenSigSwitchedByIgnition" SG_ 2527679639 AuthTime_Trigger_Distribution 0;
BA_ "GenSigSendType" SG_ 2527679639 KBI_Anzeige_ID_quittiert 5;
BA_ "GenSigSwitchedByIgnition" SG_ 2527679639 KBI_Anzeige_ID_quittiert 0;
BA_ "GenSigSendType" SG_ 2527679639 KBI_FoD_VirtualCockpitPlus_State 3;
BA_ "GenSigSwitchedByIgnition" SG_ 2527679639 KBI_FoD_VirtualCockpitPlus_State 0;
BA_ "GenSigSendType" SG_ 2527679639 KBI_Jokerkey 3;
BA_ "GenSigSwitchedByIgnition" SG_ 2527679639 KBI_Jokerkey 0;
BA_ "GenSigSendType" SG_ 2527679639 KBI_Min_Tankinhalt 0;
BA_ "GenSigStartValue" SG_ 2527679639 KBI_Min_Tankinhalt 126;
BA_ "GenSigSwitchedByIgnition" SG_ 2527679639 KBI_Min_Tankinhalt 0;
BA_ "Fehlerwert" SG_ 2527679639 KBI_Min_Tankinhalt 127;
BA_ "GenSigSendType" SG_ 2527679639 KBI_RS_Druck_uebernehmen 3;
BA_ "GenSigSwitchedByIgnition" SG_ 2527679639 KBI_RS_Druck_uebernehmen 0;
BA_ "GenSigSendType" SG_ 2527679639 KBI_RS_Druckauswahl_Aktiv 3;
BA_ "GenSigSwitchedByIgnition" SG_ 2527679639 KBI_RS_Druckauswahl_Aktiv 0;
BA_ "GenSigSendType" SG_ 2527679639 KBI_RS_Mode_fortsetzen 3;
BA_ "GenSigSwitchedByIgnition" SG_ 2527679639 KBI_RS_Mode_fortsetzen 0;
BA_ "GenSigSendType" SG_ 2527679639 KBI_Rundstreckenmodus 3;
BA_ "GenSigSwitchedByIgnition" SG_ 2527679639 KBI_Rundstreckenmodus 0;
BA_ "GenSigSendType" SG_ 2527679639 KBI_Weg_Zaehler 3;
BA_ "GenSigSwitchedByIgnition" SG_ 2527679639 KBI_Weg_Zaehler 0;
BA_ "GenSigSendType" SG_ 2527679639 KBI_Weg_Zaehler_F 3;
BA_ "GenSigSwitchedByIgnition" SG_ 2527679639 KBI_Weg_Zaehler_F 0;
BA_ "Fehlerwert" SG_ 2527679639 KBI_Weg_Zaehler_F 1;
BA_ "GenSigSendType" SG_ 1614 KBI_HUD_Data_01 3;
BA_ "GenSigSwitchedByIgnition" SG_ 1614 KBI_HUD_Data_01 0;
BA_ "GenSigSendType" SG_ 1614 KBI_HUD_Data_02 3;
BA_ "GenSigSwitchedByIgnition" SG_ 1614 KBI_HUD_Data_02 0;
BA_ "GenSigSendType" SG_ 1614 KBI_HUD_Data_03 3;
BA_ "GenSigSwitchedByIgnition" SG_ 1614 KBI_HUD_Data_03 0;
BA_ "GenSigSendType" SG_ 1614 KBI_HUD_Data_04 3;
BA_ "GenSigSwitchedByIgnition" SG_ 1614 KBI_HUD_Data_04 0;
BA_ "GenSigSendType" SG_ 1614 KBI_HUD_Data_05 3;
BA_ "GenSigSwitchedByIgnition" SG_ 1614 KBI_HUD_Data_05 0;
BA_ "GenSigSendType" SG_ 1614 KBI_HUD_Data_06 3;
BA_ "GenSigSwitchedByIgnition" SG_ 1614 KBI_HUD_Data_06 0;
BA_ "GenSigSendType" SG_ 1614 KBI_HUD_Data_07 3;
BA_ "GenSigSwitchedByIgnition" SG_ 1614 KBI_HUD_Data_07 0;
BA_ "GenSigSendType" SG_ 1614 KBI_HUD_Data_08 3;
BA_ "GenSigSwitchedByIgnition" SG_ 1614 KBI_HUD_Data_08 0;
BA_ "GenSigSendType" SG_ 2621440270 KS_BCM1_Req_FD_Data 3;
BA_ "GenSigFuncType" SG_ 2621440270 KS_BCM1_Req_FD_Data 9;
BA_ "GenSigSwitchedByIgnition" SG_ 2621440270 KS_BCM1_Req_FD_Data 0;
BA_ "GenSigSendType" SG_ 2621571342 KS_BCM1_Resp_FD_Data 3;
BA_ "GenSigFuncType" SG_ 2621571342 KS_BCM1_Resp_FD_Data 9;
BA_ "GenSigSwitchedByIgnition" SG_ 2621571342 KS_BCM1_Resp_FD_Data 0;
BA_ "GenSigSendType" SG_ 1387 LCM_Blinker_Fehler_L 0;
BA_ "GenSigSwitchedByIgnition" SG_ 1387 LCM_Blinker_Fehler_L 0;
BA_ "Fehlerwert" SG_ 1387 LCM_Blinker_Fehler_L 1;
BA_ "GenSigSendType" SG_ 1387 LCM_Datensatz_Fehler_L 0;
BA_ "GenSigSwitchedByIgnition" SG_ 1387 LCM_Datensatz_Fehler_L 0;
BA_ "Fehlerwert" SG_ 1387 LCM_Datensatz_Fehler_L 1;
BA_ "GenSigSendType" SG_ 1387 LCM_DKL_L_defekt_Fehler 0;
BA_ "GenSigSwitchedByIgnition" SG_ 1387 LCM_DKL_L_defekt_Fehler 0;
BA_ "Fehlerwert" SG_ 1387 LCM_DKL_L_defekt_Fehler 1;
BA_ "GenSigSendType" SG_ 1387 LCM_Feh_L_BZ 0;
BA_ "GenSigFuncType" SG_ 1387 LCM_Feh_L_BZ 1;
BA_ "GenSigSwitchedByIgnition" SG_ 1387 LCM_Feh_L_BZ 0;
BA_ "GenSigSendType" SG_ 1387 LCM_Feh_L_CRC 0;
BA_ "GenSigFuncType" SG_ 1387 LCM_Feh_L_CRC 2;
BA_ "GenSigSwitchedByIgnition" SG_ 1387 LCM_Feh_L_CRC 0;
BA_ "GenSigSendType" SG_ 1387 LCM_GLW_L_defekt_Fehler 0;
BA_ "GenSigSwitchedByIgnition" SG_ 1387 LCM_GLW_L_defekt_Fehler 0;
BA_ "Fehlerwert" SG_ 1387 LCM_GLW_L_defekt_Fehler 1;
BA_ "GenSigSendType" SG_ 1387 LCM_LWR_L_allg_Fehler 0;
BA_ "GenSigSwitchedByIgnition" SG_ 1387 LCM_LWR_L_allg_Fehler 0;
BA_ "Fehlerwert" SG_ 1387 LCM_LWR_L_allg_Fehler 1;
BA_ "GenSigSendType" SG_ 1387 LCM_LWR_L_defekt_Fehler 0;
BA_ "GenSigSwitchedByIgnition" SG_ 1387 LCM_LWR_L_defekt_Fehler 0;
BA_ "Fehlerwert" SG_ 1387 LCM_LWR_L_defekt_Fehler 1;
BA_ "GenSigSendType" SG_ 1387 LCM_PO_Fehler_L 0;
BA_ "GenSigSwitchedByIgnition" SG_ 1387 LCM_PO_Fehler_L 0;
BA_ "Fehlerwert" SG_ 1387 LCM_PO_Fehler_L 1;
BA_ "GenSigSendType" SG_ 1387 LCM_Shutter_Fehler_L 0;
BA_ "GenSigSwitchedByIgnition" SG_ 1387 LCM_Shutter_Fehler_L 0;
BA_ "Fehlerwert" SG_ 1387 LCM_Shutter_Fehler_L 1;
BA_ "GenSigSendType" SG_ 1387 LCM_SKL_L_defekt_Fehler 0;
BA_ "GenSigSwitchedByIgnition" SG_ 1387 LCM_SKL_L_defekt_Fehler 0;
BA_ "Fehlerwert" SG_ 1387 LCM_SKL_L_defekt_Fehler 1;
BA_ "GenSigSendType" SG_ 1387 LCM_SM_Fehler_L 0;
BA_ "GenSigSwitchedByIgnition" SG_ 1387 LCM_SM_Fehler_L 0;
BA_ "Fehlerwert" SG_ 1387 LCM_SM_Fehler_L 1;
BA_ "GenSigSendType" SG_ 1387 LCM_Sonstiger_Fehler_L 0;
BA_ "GenSigSwitchedByIgnition" SG_ 1387 LCM_Sonstiger_Fehler_L 0;
BA_ "Fehlerwert" SG_ 1387 LCM_Sonstiger_Fehler_L 1;
BA_ "GenSigSendType" SG_ 1387 LCM_TFL_Fehler_L 0;
BA_ "GenSigSwitchedByIgnition" SG_ 1387 LCM_TFL_Fehler_L 0;
BA_ "Fehlerwert" SG_ 1387 LCM_TFL_Fehler_L 1;
BA_ "GenSigSendType" SG_ 1388 LCM_Blinker_Fehler_R 0;
BA_ "GenSigSwitchedByIgnition" SG_ 1388 LCM_Blinker_Fehler_R 0;
BA_ "Fehlerwert" SG_ 1388 LCM_Blinker_Fehler_R 1;
BA_ "GenSigSendType" SG_ 1388 LCM_Datensatz_Fehler_R 0;
BA_ "GenSigSwitchedByIgnition" SG_ 1388 LCM_Datensatz_Fehler_R 0;
BA_ "Fehlerwert" SG_ 1388 LCM_Datensatz_Fehler_R 1;
BA_ "GenSigSendType" SG_ 1388 LCM_DKL_R_defekt_Fehler 0;
BA_ "GenSigSwitchedByIgnition" SG_ 1388 LCM_DKL_R_defekt_Fehler 0;
BA_ "Fehlerwert" SG_ 1388 LCM_DKL_R_defekt_Fehler 1;
BA_ "GenSigSendType" SG_ 1388 LCM_Feh_R_BZ 0;
BA_ "GenSigFuncType" SG_ 1388 LCM_Feh_R_BZ 1;
BA_ "GenSigSwitchedByIgnition" SG_ 1388 LCM_Feh_R_BZ 0;
BA_ "GenSigSendType" SG_ 1388 LCM_Feh_R_CRC 0;
BA_ "GenSigFuncType" SG_ 1388 LCM_Feh_R_CRC 2;
BA_ "GenSigSwitchedByIgnition" SG_ 1388 LCM_Feh_R_CRC 0;
BA_ "GenSigSendType" SG_ 1388 LCM_GLW_R_defekt_Fehler 0;
BA_ "GenSigSwitchedByIgnition" SG_ 1388 LCM_GLW_R_defekt_Fehler 0;
BA_ "Fehlerwert" SG_ 1388 LCM_GLW_R_defekt_Fehler 1;
BA_ "GenSigSendType" SG_ 1388 LCM_LWR_R_allg_Fehler 0;
BA_ "GenSigSwitchedByIgnition" SG_ 1388 LCM_LWR_R_allg_Fehler 0;
BA_ "Fehlerwert" SG_ 1388 LCM_LWR_R_allg_Fehler 1;
BA_ "GenSigSendType" SG_ 1388 LCM_LWR_R_defekt_Fehler 0;
BA_ "GenSigSwitchedByIgnition" SG_ 1388 LCM_LWR_R_defekt_Fehler 0;
BA_ "Fehlerwert" SG_ 1388 LCM_LWR_R_defekt_Fehler 1;
BA_ "GenSigSendType" SG_ 1388 LCM_PO_Fehler_R 0;
BA_ "GenSigSwitchedByIgnition" SG_ 1388 LCM_PO_Fehler_R 0;
BA_ "Fehlerwert" SG_ 1388 LCM_PO_Fehler_R 1;
BA_ "GenSigSendType" SG_ 1388 LCM_Shutter_Fehler_R 0;
BA_ "GenSigSwitchedByIgnition" SG_ 1388 LCM_Shutter_Fehler_R 0;
BA_ "Fehlerwert" SG_ 1388 LCM_Shutter_Fehler_R 1;
BA_ "GenSigSendType" SG_ 1388 LCM_SKL_R_defekt_Fehler 0;
BA_ "GenSigSwitchedByIgnition" SG_ 1388 LCM_SKL_R_defekt_Fehler 0;
BA_ "Fehlerwert" SG_ 1388 LCM_SKL_R_defekt_Fehler 1;
BA_ "GenSigSendType" SG_ 1388 LCM_SM_Fehler_R 0;
BA_ "GenSigSwitchedByIgnition" SG_ 1388 LCM_SM_Fehler_R 0;
BA_ "Fehlerwert" SG_ 1388 LCM_SM_Fehler_R 1;
BA_ "GenSigSendType" SG_ 1388 LCM_Sonstiger_Fehler_R 0;
BA_ "GenSigSwitchedByIgnition" SG_ 1388 LCM_Sonstiger_Fehler_R 0;
BA_ "Fehlerwert" SG_ 1388 LCM_Sonstiger_Fehler_R 1;
BA_ "GenSigSendType" SG_ 1388 LCM_TFL_Fehler_R 0;
BA_ "GenSigSwitchedByIgnition" SG_ 1388 LCM_TFL_Fehler_R 0;
BA_ "Fehlerwert" SG_ 1388 LCM_TFL_Fehler_R 1;
BA_ "GenSigSendType" SG_ 403 AMBEX_CH_aktiv 3;
BA_ "GenSigSwitchedByIgnition" SG_ 403 AMBEX_CH_aktiv 0;
BA_ "GenSigSendType" SG_ 403 AMBEX_CH_Trigger 3;
BA_ "GenSigSwitchedByIgnition" SG_ 403 AMBEX_CH_Trigger 0;
BA_ "GenSigSendType" SG_ 403 AMBEX_LH_aktiv 3;
BA_ "GenSigSwitchedByIgnition" SG_ 403 AMBEX_LH_aktiv 0;
BA_ "GenSigSendType" SG_ 403 AMBEX_LH_Trigger 3;
BA_ "GenSigSwitchedByIgnition" SG_ 403 AMBEX_LH_Trigger 0;
BA_ "GenSigSendType" SG_ 403 BCM1_CH_aktiv 0;
BA_ "NWM-WakeupAllowed" SG_ 403 BCM1_CH_aktiv 1;
BA_ "GenSigSwitchedByIgnition" SG_ 403 BCM1_CH_aktiv 0;
BA_ "GenSigSendType" SG_ 403 BCM1_FoD_Sperrung_AnimTFL 3;
BA_ "GenSigSendType" SG_ 403 BCM1_LH_aktiv 0;
BA_ "NWM-WakeupAllowed" SG_ 403 BCM1_LH_aktiv 1;
BA_ "GenSigSwitchedByIgnition" SG_ 403 BCM1_LH_aktiv 0;
BA_ "GenSigSendType" SG_ 403 BM_Autobahn 3;
BA_ "GenSigSwitchedByIgnition" SG_ 403 BM_Autobahn 0;
BA_ "GenSigSendType" SG_ 403 BM_ZV_auf 3;
BA_ "GenSigSwitchedByIgnition" SG_ 403 BM_ZV_auf 0;
BA_ "GenSigSendType" SG_ 403 BM_ZV_zu 3;
BA_ "GenSigSwitchedByIgnition" SG_ 403 BM_ZV_zu 0;
BA_ "GenSigSendType" SG_ 403 LCM_Abschaltung_Vbat_L_Anf 3;
BA_ "GenSigSwitchedByIgnition" SG_ 403 LCM_Abschaltung_Vbat_L_Anf 0;
BA_ "GenSigSendType" SG_ 403 LCM_Abschaltung_Vbat_R_Anf 3;
BA_ "GenSigSwitchedByIgnition" SG_ 403 LCM_Abschaltung_Vbat_R_Anf 0;
BA_ "GenSigSendType" SG_ 403 LCM_Animiertes_TFL_Anf 3;
BA_ "GenSigSwitchedByIgnition" SG_ 403 LCM_Animiertes_TFL_Anf 0;
BA_ "GenSigSendType" SG_ 403 LCM_Blinker_L_Anf 3;
BA_ "GenSigSwitchedByIgnition" SG_ 403 LCM_Blinker_L_Anf 0;
BA_ "GenSigSendType" SG_ 403 LCM_Blinker_R_Anf 3;
BA_ "GenSigSwitchedByIgnition" SG_ 403 LCM_Blinker_R_Anf 0;
BA_ "GenSigSendType" SG_ 403 LCM_Blinkerwischen_Anf 3;
BA_ "GenSigSwitchedByIgnition" SG_ 403 LCM_Blinkerwischen_Anf 0;
BA_ "GenSigSendType" SG_ 403 LCM_Blinkerzyklus_L 3;
BA_ "GenSigSwitchedByIgnition" SG_ 403 LCM_Blinkerzyklus_L 0;
BA_ "GenSigSendType" SG_ 403 LCM_Blinkerzyklus_R 3;
BA_ "GenSigSwitchedByIgnition" SG_ 403 LCM_Blinkerzyklus_R 0;
BA_ "GenSigSendType" SG_ 403 LCM_Designlicht_4 3;
BA_ "GenSigSwitchedByIgnition" SG_ 403 LCM_Designlicht_4 0;
BA_ "GenSigSendType" SG_ 403 LCM_Designlicht_5 3;
BA_ "GenSigSwitchedByIgnition" SG_ 403 LCM_Designlicht_5 0;
BA_ "GenSigSendType" SG_ 403 LCM_ECE_SAE_Umschaltung_Anf 0;
BA_ "GenSigSwitchedByIgnition" SG_ 403 LCM_ECE_SAE_Umschaltung_Anf 0;
BA_ "GenSigSendType" SG_ 403 LCM_Leistungsreduzierung_Anf 3;
BA_ "GenSigSwitchedByIgnition" SG_ 403 LCM_Leistungsreduzierung_Anf 0;
BA_ "GenSigSendType" SG_ 403 LCM_PL_L_Anf 3;
BA_ "GenSigSwitchedByIgnition" SG_ 403 LCM_PL_L_Anf 0;
BA_ "GenSigSendType" SG_ 403 LCM_PL_R_Anf 3;
BA_ "GenSigSwitchedByIgnition" SG_ 403 LCM_PL_R_Anf 0;
BA_ "GenSigSendType" SG_ 403 LCM_PO_L_Anf 3;
BA_ "GenSigSwitchedByIgnition" SG_ 403 LCM_PO_L_Anf 0;
BA_ "GenSigSendType" SG_ 403 LCM_PO_R_Anf 3;
BA_ "GenSigSwitchedByIgnition" SG_ 403 LCM_PO_R_Anf 0;
BA_ "GenSigSendType" SG_ 403 LCM_Sh_L_Anf 3;
BA_ "GenSigSwitchedByIgnition" SG_ 403 LCM_Sh_L_Anf 0;
BA_ "GenSigSendType" SG_ 403 LCM_Sh_R_Anf 3;
BA_ "GenSigSwitchedByIgnition" SG_ 403 LCM_Sh_R_Anf 0;
BA_ "GenSigSendType" SG_ 403 LCM_Signaturlicht_Anf 3;
BA_ "GenSigSwitchedByIgnition" SG_ 403 LCM_Signaturlicht_Anf 0;
BA_ "GenSigSendType" SG_ 403 LCM_SM_L_Anf 3;
BA_ "GenSigSwitchedByIgnition" SG_ 403 LCM_SM_L_Anf 0;
BA_ "GenSigSendType" SG_ 403 LCM_SM_R_Anf 3;
BA_ "GenSigSwitchedByIgnition" SG_ 403 LCM_SM_R_Anf 0;
BA_ "GenSigSendType" SG_ 403 LCM_Soll_BZ 0;
BA_ "GenSigFuncType" SG_ 403 LCM_Soll_BZ 1;
BA_ "GenSigSwitchedByIgnition" SG_ 403 LCM_Soll_BZ 0;
BA_ "GenSigSendType" SG_ 403 LCM_Soll_CRC 0;
BA_ "GenSigFuncType" SG_ 403 LCM_Soll_CRC 2;
BA_ "GenSigSwitchedByIgnition" SG_ 403 LCM_Soll_CRC 0;
BA_ "GenSigSendType" SG_ 403 LCM_TFL_L_Anf 3;
BA_ "GenSigSwitchedByIgnition" SG_ 403 LCM_TFL_L_Anf 0;
BA_ "GenSigSendType" SG_ 403 LCM_TFL_R_Anf 3;
BA_ "GenSigSwitchedByIgnition" SG_ 403 LCM_TFL_R_Anf 0;
BA_ "GenSigSendType" SG_ 403 LCM_TFL_Signatur_Anf 0;
BA_ "GenSigSwitchedByIgnition" SG_ 403 LCM_TFL_Signatur_Anf 0;
BA_ "GenSigSendType" SG_ 403 LCM_univ_1_L_Anf 3;
BA_ "GenSigSwitchedByIgnition" SG_ 403 LCM_univ_1_L_Anf 0;
BA_ "GenSigSendType" SG_ 403 LCM_univ_1_R_Anf 3;
BA_ "GenSigSwitchedByIgnition" SG_ 403 LCM_univ_1_R_Anf 0;
BA_ "GenSigSendType" SG_ 411 LCM_Abschaltbestaetigung_L 3;
BA_ "GenSigSwitchedByIgnition" SG_ 411 LCM_Abschaltbestaetigung_L 0;
BA_ "Fehlerwert" SG_ 411 LCM_Abschaltbestaetigung_L 3;
BA_ "GenSigSendType" SG_ 411 LCM_Ausgangsleistungsred_L_Sta 3;
BA_ "GenSigSwitchedByIgnition" SG_ 411 LCM_Ausgangsleistungsred_L_Sta 0;
BA_ "GenSigSendType" SG_ 411 LCM_Blinker_L_Sta 3;
BA_ "GenSigSwitchedByIgnition" SG_ 411 LCM_Blinker_L_Sta 0;
BA_ "GenSigSendType" SG_ 411 LCM_PL_L_Sta 3;
BA_ "GenSigSwitchedByIgnition" SG_ 411 LCM_PL_L_Sta 0;
BA_ "GenSigSendType" SG_ 411 LCM_PO_L_Sta 3;
BA_ "GenSigSwitchedByIgnition" SG_ 411 LCM_PO_L_Sta 0;
BA_ "GenSigSendType" SG_ 411 LCM_Sh_L_Sta 3;
BA_ "GenSigSwitchedByIgnition" SG_ 411 LCM_Sh_L_Sta 0;
BA_ "GenSigSendType" SG_ 411 LCM_SM_L_Sta 3;
BA_ "GenSigSwitchedByIgnition" SG_ 411 LCM_SM_L_Sta 0;
BA_ "GenSigSendType" SG_ 411 LCM_Sta_L_BZ 0;
BA_ "GenSigFuncType" SG_ 411 LCM_Sta_L_BZ 1;
BA_ "GenSigSwitchedByIgnition" SG_ 411 LCM_Sta_L_BZ 0;
BA_ "GenSigSendType" SG_ 411 LCM_Sta_L_CRC 0;
BA_ "GenSigFuncType" SG_ 411 LCM_Sta_L_CRC 2;
BA_ "GenSigSwitchedByIgnition" SG_ 411 LCM_Sta_L_CRC 0;
BA_ "GenSigSendType" SG_ 411 LCM_TFL_L_Sta 3;
BA_ "GenSigSwitchedByIgnition" SG_ 411 LCM_TFL_L_Sta 0;
BA_ "GenSigSendType" SG_ 411 LCM_univ_1_L_Sta 3;
BA_ "GenSigSwitchedByIgnition" SG_ 411 LCM_univ_1_L_Sta 0;
BA_ "GenSigSendType" SG_ 411 LMS_DMD_LED_Temp_L 3;
BA_ "GenSigStartValue" SG_ 411 LMS_DMD_LED_Temp_L 255;
BA_ "GenSigSendType" SG_ 413 LCM_Abschaltbestaetigung_R 3;
BA_ "GenSigSwitchedByIgnition" SG_ 413 LCM_Abschaltbestaetigung_R 0;
BA_ "Fehlerwert" SG_ 413 LCM_Abschaltbestaetigung_R 3;
BA_ "GenSigSendType" SG_ 413 LCM_Ausgangsleistungsred_R_Sta 3;
BA_ "GenSigSwitchedByIgnition" SG_ 413 LCM_Ausgangsleistungsred_R_Sta 0;
BA_ "GenSigSendType" SG_ 413 LCM_Blinker_R_Sta 3;
BA_ "GenSigSwitchedByIgnition" SG_ 413 LCM_Blinker_R_Sta 0;
BA_ "GenSigSendType" SG_ 413 LCM_PL_R_Sta 3;
BA_ "GenSigSwitchedByIgnition" SG_ 413 LCM_PL_R_Sta 0;
BA_ "GenSigSendType" SG_ 413 LCM_PO_R_Sta 3;
BA_ "GenSigSwitchedByIgnition" SG_ 413 LCM_PO_R_Sta 0;
BA_ "GenSigSendType" SG_ 413 LCM_Sh_R_Sta 3;
BA_ "GenSigSwitchedByIgnition" SG_ 413 LCM_Sh_R_Sta 0;
BA_ "GenSigSendType" SG_ 413 LCM_SM_R_Sta 3;
BA_ "GenSigSwitchedByIgnition" SG_ 413 LCM_SM_R_Sta 0;
BA_ "GenSigSendType" SG_ 413 LCM_Sta_R_BZ 0;
BA_ "GenSigFuncType" SG_ 413 LCM_Sta_R_BZ 1;
BA_ "GenSigSwitchedByIgnition" SG_ 413 LCM_Sta_R_BZ 0;
BA_ "GenSigSendType" SG_ 413 LCM_Sta_R_CRC 0;
BA_ "GenSigFuncType" SG_ 413 LCM_Sta_R_CRC 2;
BA_ "GenSigSwitchedByIgnition" SG_ 413 LCM_Sta_R_CRC 0;
BA_ "GenSigSendType" SG_ 413 LCM_TFL_R_Sta 3;
BA_ "GenSigSwitchedByIgnition" SG_ 413 LCM_TFL_R_Sta 0;
BA_ "GenSigSendType" SG_ 413 LCM_univ_1_R_Sta 3;
BA_ "GenSigSwitchedByIgnition" SG_ 413 LCM_univ_1_R_Sta 0;
BA_ "GenSigSendType" SG_ 413 LMS_DMD_LED_Temp_R 3;
BA_ "GenSigStartValue" SG_ 413 LMS_DMD_LED_Temp_R 255;
BA_ "GenSigSendType" SG_ 2527679510 LED_Feh_LM_L_03_BZ 0;
BA_ "GenSigFuncType" SG_ 2527679510 LED_Feh_LM_L_03_BZ 1;
BA_ "GenSigSwitchedByIgnition" SG_ 2527679510 LED_Feh_LM_L_03_BZ 0;
BA_ "GenSigSendType" SG_ 2527679510 LED_Feh_LM_L_03_CRC 0;
BA_ "GenSigFuncType" SG_ 2527679510 LED_Feh_LM_L_03_CRC 2;
BA_ "GenSigSwitchedByIgnition" SG_ 2527679510 LED_Feh_LM_L_03_CRC 0;
BA_ "GenSigSendType" SG_ 2527679510 LED_L_Abbiegel_Def 0;
BA_ "Fehlerwert" SG_ 2527679510 LED_L_Abbiegel_Def 1;
BA_ "GenSigSendType" SG_ 2527679510 LED_L_Abblendl_Def 0;
BA_ "Fehlerwert" SG_ 2527679510 LED_L_Abblendl_Def 1;
BA_ "GenSigSendType" SG_ 2527679510 LED_L_Allg_Elektr_Def 0;
BA_ "Fehlerwert" SG_ 2527679510 LED_L_Allg_Elektr_Def 1;
BA_ "GenSigSendType" SG_ 2527679510 LED_L_falsch_codiert 0;
BA_ "GenSigSwitchedByIgnition" SG_ 2527679510 LED_L_falsch_codiert 0;
BA_ "GenSigSendType" SG_ 2527679510 LED_L_Fernl_Def 0;
BA_ "Fehlerwert" SG_ 2527679510 LED_L_Fernl_Def 1;
BA_ "GenSigSendType" SG_ 2527679510 LED_L_Laser_Def 0;
BA_ "GenSigSwitchedByIgnition" SG_ 2527679510 LED_L_Laser_Def 0;
BA_ "GenSigSendType" SG_ 2527679510 LED_L_Laser_Stoerung 0;
BA_ "GenSigSwitchedByIgnition" SG_ 2527679510 LED_L_Laser_Stoerung 0;
BA_ "GenSigSendType" SG_ 2527679510 LED_L_Zus_Fernl_LH_Def 0;
BA_ "GenSigSwitchedByIgnition" SG_ 2527679510 LED_L_Zus_Fernl_LH_Def 0;
BA_ "GenSigSendType" SG_ 2527679511 LED_Feh_LM_R_03_BZ 0;
BA_ "GenSigFuncType" SG_ 2527679511 LED_Feh_LM_R_03_BZ 1;
BA_ "GenSigSwitchedByIgnition" SG_ 2527679511 LED_Feh_LM_R_03_BZ 0;
BA_ "GenSigSendType" SG_ 2527679511 LED_Feh_LM_R_03_CRC 0;
BA_ "GenSigFuncType" SG_ 2527679511 LED_Feh_LM_R_03_CRC 2;
BA_ "GenSigSwitchedByIgnition" SG_ 2527679511 LED_Feh_LM_R_03_CRC 0;
BA_ "GenSigSendType" SG_ 2527679511 LED_R_Abbiegel_Def 0;
BA_ "Fehlerwert" SG_ 2527679511 LED_R_Abbiegel_Def 1;
BA_ "GenSigSendType" SG_ 2527679511 LED_R_Abblendl_Def 0;
BA_ "Fehlerwert" SG_ 2527679511 LED_R_Abblendl_Def 1;
BA_ "GenSigSendType" SG_ 2527679511 LED_R_Allg_Elektr_Def 0;
BA_ "Fehlerwert" SG_ 2527679511 LED_R_Allg_Elektr_Def 1;
BA_ "GenSigSendType" SG_ 2527679511 LED_R_falsch_codiert 0;
BA_ "GenSigSwitchedByIgnition" SG_ 2527679511 LED_R_falsch_codiert 0;
BA_ "GenSigSendType" SG_ 2527679511 LED_R_Fernl_Def 0;
BA_ "Fehlerwert" SG_ 2527679511 LED_R_Fernl_Def 1;
BA_ "GenSigSendType" SG_ 2527679511 LED_R_Laser_Def 0;
BA_ "GenSigSwitchedByIgnition" SG_ 2527679511 LED_R_Laser_Def 0;
BA_ "GenSigSendType" SG_ 2527679511 LED_R_Laser_Stoerung 0;
BA_ "GenSigSwitchedByIgnition" SG_ 2527679511 LED_R_Laser_Stoerung 0;
BA_ "GenSigSendType" SG_ 2527679511 LED_R_Zus_Fernl_LH_Def 0;
BA_ "GenSigSwitchedByIgnition" SG_ 2527679511 LED_R_Zus_Fernl_LH_Def 0;
BA_ "GenSigSendType" SG_ 981 BCM1_Abblendlicht_Anf 0;
BA_ "GenSigSwitchedByIgnition" SG_ 981 BCM1_Abblendlicht_Anf 0;
BA_ "GenSigSendType" SG_ 981 BCM1_Adaptive_Lichtvert_Anf 0;
BA_ "GenSigSwitchedByIgnition" SG_ 981 BCM1_Adaptive_Lichtvert_Anf 0;
BA_ "GenSigSendType" SG_ 981 BCM1_Allwetterlicht_Anf 0;
BA_ "GenSigSwitchedByIgnition" SG_ 981 BCM1_Allwetterlicht_Anf 0;
BA_ "GenSigSendType" SG_ 981 BCM1_Animationssperrung 3;
BA_ "GenSigStartValue" SG_ 981 BCM1_Animationssperrung 1;
BA_ "GenSigSwitchedByIgnition" SG_ 981 BCM1_Animationssperrung 0;
BA_ "GenSigSendType" SG_ 981 BCM1_Autobahnlicht_Anf 0;
BA_ "GenSigSwitchedByIgnition" SG_ 981 BCM1_Autobahnlicht_Anf 0;
BA_ "GenSigSendType" SG_ 981 BCM1_CH_aktiv 0;
BA_ "NWM-WakeupAllowed" SG_ 981 BCM1_CH_aktiv 1;
BA_ "GenSigSwitchedByIgnition" SG_ 981 BCM1_CH_aktiv 0;
BA_ "GenSigSendType" SG_ 981 BCM1_CH_LH_aktiv 0;
BA_ "GenSigSwitchedByIgnition" SG_ 981 BCM1_CH_LH_aktiv 0;
BA_ "GenSigSendType" SG_ 981 BCM1_Fernlicht_Anf 0;
BA_ "GenSigSwitchedByIgnition" SG_ 981 BCM1_Fernlicht_Anf 0;
BA_ "GenSigSendType" SG_ 981 BCM1_Gleitende_Leuchtw_Anf 0;
BA_ "GenSigSwitchedByIgnition" SG_ 981 BCM1_Gleitende_Leuchtw_Anf 0;
BA_ "GenSigSendType" SG_ 981 BCM1_GLW_Fernlicht_Anf 3;
BA_ "GenSigSwitchedByIgnition" SG_ 981 BCM1_GLW_Fernlicht_Anf 0;
BA_ "GenSigSendType" SG_ 981 BCM1_Kurvenlicht_links_Anf 0;
BA_ "GenSigSwitchedByIgnition" SG_ 981 BCM1_Kurvenlicht_links_Anf 0;
BA_ "GenSigSendType" SG_ 981 BCM1_Kurvenlicht_rechts_Anf 0;
BA_ "GenSigSwitchedByIgnition" SG_ 981 BCM1_Kurvenlicht_rechts_Anf 0;
BA_ "GenSigSendType" SG_ 981 BCM1_LH_aktiv 0;
BA_ "NWM-WakeupAllowed" SG_ 981 BCM1_LH_aktiv 1;
BA_ "GenSigSwitchedByIgnition" SG_ 981 BCM1_LH_aktiv 0;
BA_ "GenSigSendType" SG_ 981 BCM1_Nebellicht_Anf 0;
BA_ "GenSigSwitchedByIgnition" SG_ 981 BCM1_Nebellicht_Anf 0;
BA_ "GenSigSendType" SG_ 981 BCM1_Nebelschluss_Ahg_Anf 0;
BA_ "GenSigSwitchedByIgnition" SG_ 981 BCM1_Nebelschluss_Ahg_Anf 0;
BA_ "GenSigSendType" SG_ 981 BCM1_Nebelschluss_Fzg_Anf 0;
BA_ "GenSigSwitchedByIgnition" SG_ 981 BCM1_Nebelschluss_Fzg_Anf 0;
BA_ "GenSigSendType" SG_ 981 BCM1_Parklicht_li_Anf 0;
BA_ "GenSigSwitchedByIgnition" SG_ 981 BCM1_Parklicht_li_Anf 0;
BA_ "GenSigSendType" SG_ 981 BCM1_Parklicht_re_Anf 0;
BA_ "GenSigSwitchedByIgnition" SG_ 981 BCM1_Parklicht_re_Anf 0;
BA_ "GenSigSendType" SG_ 981 BCM1_Regenlicht_Anf 0;
BA_ "GenSigSwitchedByIgnition" SG_ 981 BCM1_Regenlicht_Anf 0;
BA_ "GenSigSendType" SG_ 981 BCM1_Schlusslicht_Anf 0;
BA_ "GenSigSwitchedByIgnition" SG_ 981 BCM1_Schlusslicht_Anf 0;
BA_ "GenSigSendType" SG_ 981 BCM1_Signaturlicht_Anf 0;
BA_ "GenSigSwitchedByIgnition" SG_ 981 BCM1_Signaturlicht_Anf 0;
BA_ "GenSigSendType" SG_ 981 BCM1_Standlicht_Anf 0;
BA_ "GenSigSwitchedByIgnition" SG_ 981 BCM1_Standlicht_Anf 0;
BA_ "GenSigSendType" SG_ 981 BCM1_Tagfahrlicht_Anf 0;
BA_ "GenSigSwitchedByIgnition" SG_ 981 BCM1_Tagfahrlicht_Anf 0;
BA_ "GenSigSendType" SG_ 981 BCM1_Touristen_Licht_Anf 0;
BA_ "GenSigSwitchedByIgnition" SG_ 981 BCM1_Touristen_Licht_Anf 0;
BA_ "GenSigSendType" SG_ 981 BCM1_Umfeldleuchten_Anf 0;
BA_ "GenSigSwitchedByIgnition" SG_ 981 BCM1_Umfeldleuchten_Anf 0;
BA_ "GenSigSendType" SG_ 981 BCM_Rueckfahrlicht_Anf 0;
BA_ "GenSigSwitchedByIgnition" SG_ 981 BCM_Rueckfahrlicht_Anf 0;
BA_ "GenSigSendType" SG_ 981 Licht_Anf_01_BZ 0;
BA_ "GenSigFuncType" SG_ 981 Licht_Anf_01_BZ 1;
BA_ "GenSigSwitchedByIgnition" SG_ 981 Licht_Anf_01_BZ 0;
BA_ "GenSigSendType" SG_ 981 Licht_Anf_01_CRC 0;
BA_ "GenSigFuncType" SG_ 981 Licht_Anf_01_CRC 2;
BA_ "GenSigSwitchedByIgnition" SG_ 981 Licht_Anf_01_CRC 0;
BA_ "GenSigSendType" SG_ 981 TFL_Matrix_Variante01_Anf 3;
BA_ "GenSigSendType" SG_ 981 TFL_Matrix_Variante02_Anf 3;
BA_ "GenSigSendType" SG_ 981 TFL_Matrix_Variante03_Anf 3;
BA_ "GenSigSendType" SG_ 981 TFL_Matrix_Variante04_Anf 3;
BA_ "GenSigSendType" SG_ 982 BCM2_Bremsl_durch_ECD 0;
BA_ "GenSigSwitchedByIgnition" SG_ 982 BCM2_Bremsl_durch_ECD 0;
BA_ "GenSigSendType" SG_ 982 BCM2_Bremsl_durch_ECD_invers 0;
BA_ "GenSigStartValue" SG_ 982 BCM2_Bremsl_durch_ECD_invers 1;
BA_ "GenSigSwitchedByIgnition" SG_ 982 BCM2_Bremsl_durch_ECD_invers 0;
BA_ "GenSigSendType" SG_ 982 LH_3_Bremsl_def 0;
BA_ "GenSigSwitchedByIgnition" SG_ 982 LH_3_Bremsl_def 0;
BA_ "GenSigSendType" SG_ 982 LH_Aussenlicht_def 0;
BA_ "GenSigSwitchedByIgnition" SG_ 982 LH_Aussenlicht_def 0;
BA_ "GenSigSendType" SG_ 982 LH_Blinker_HL_akt 0;
BA_ "GenSigSwitchedByIgnition" SG_ 982 LH_Blinker_HL_akt 0;
BA_ "GenSigSendType" SG_ 982 LH_Blinker_HR_akt 0;
BA_ "GenSigSwitchedByIgnition" SG_ 982 LH_Blinker_HR_akt 0;
BA_ "GenSigSendType" SG_ 982 LH_Blinker_li_def 0;
BA_ "GenSigSwitchedByIgnition" SG_ 982 LH_Blinker_li_def 0;
BA_ "GenSigSendType" SG_ 982 LH_Blinker_re_def 0;
BA_ "GenSigSwitchedByIgnition" SG_ 982 LH_Blinker_re_def 0;
BA_ "GenSigSendType" SG_ 982 LH_Brems_Blk_li_def 0;
BA_ "GenSigSwitchedByIgnition" SG_ 982 LH_Brems_Blk_li_def 0;
BA_ "GenSigSendType" SG_ 982 LH_Brems_Blk_re_def 0;
BA_ "GenSigSwitchedByIgnition" SG_ 982 LH_Brems_Blk_re_def 0;
BA_ "GenSigSendType" SG_ 982 LH_Bremsl_li_def 0;
BA_ "GenSigSwitchedByIgnition" SG_ 982 LH_Bremsl_li_def 0;
BA_ "GenSigSendType" SG_ 982 LH_Bremsl_li_ges_def 0;
BA_ "GenSigSwitchedByIgnition" SG_ 982 LH_Bremsl_li_ges_def 0;
BA_ "GenSigSendType" SG_ 982 LH_Bremsl_re_def 0;
BA_ "GenSigSwitchedByIgnition" SG_ 982 LH_Bremsl_re_def 0;
BA_ "GenSigSendType" SG_ 982 LH_Bremsl_re_ges_def 0;
BA_ "GenSigSwitchedByIgnition" SG_ 982 LH_Bremsl_re_ges_def 0;
BA_ "GenSigSendType" SG_ 982 LH_Bremslicht_H_aktiv 0;
BA_ "GenSigSwitchedByIgnition" SG_ 982 LH_Bremslicht_H_aktiv 0;
BA_ "GenSigSendType" SG_ 982 LH_Diag_LED_li_def 0;
BA_ "GenSigSwitchedByIgnition" SG_ 982 LH_Diag_LED_li_def 0;
BA_ "GenSigSendType" SG_ 982 LH_Diag_LED_re_def 0;
BA_ "GenSigSwitchedByIgnition" SG_ 982 LH_Diag_LED_re_def 0;
BA_ "GenSigSendType" SG_ 982 LH_Diag_Status_li_def 0;
BA_ "GenSigSwitchedByIgnition" SG_ 982 LH_Diag_Status_li_def 0;
BA_ "GenSigSendType" SG_ 982 LH_Diag_Status_re_def 0;
BA_ "GenSigSwitchedByIgnition" SG_ 982 LH_Diag_Status_re_def 0;
BA_ "GenSigSendType" SG_ 982 LH_Kennzl_def 0;
BA_ "GenSigSwitchedByIgnition" SG_ 982 LH_Kennzl_def 0;
BA_ "GenSigSendType" SG_ 982 LH_Nebel_li_def 0;
BA_ "GenSigSwitchedByIgnition" SG_ 982 LH_Nebel_li_def 0;
BA_ "GenSigSendType" SG_ 982 LH_Nebel_mi_def 0;
BA_ "GenSigSwitchedByIgnition" SG_ 982 LH_Nebel_mi_def 0;
BA_ "GenSigSendType" SG_ 982 LH_Nebel_re_def 0;
BA_ "GenSigSwitchedByIgnition" SG_ 982 LH_Nebel_re_def 0;
BA_ "GenSigSendType" SG_ 982 LH_Nebelschluss_aktiv 0;
BA_ "GenSigSwitchedByIgnition" SG_ 982 LH_Nebelschluss_aktiv 0;
BA_ "GenSigSendType" SG_ 982 LH_Parklicht_HL_aktiv 0;
BA_ "GenSigSwitchedByIgnition" SG_ 982 LH_Parklicht_HL_aktiv 0;
BA_ "GenSigSendType" SG_ 982 LH_Parklicht_HR_aktiv 0;
BA_ "GenSigSwitchedByIgnition" SG_ 982 LH_Parklicht_HR_aktiv 0;
BA_ "GenSigSendType" SG_ 982 LH_Rueckf_li_def 0;
BA_ "GenSigSwitchedByIgnition" SG_ 982 LH_Rueckf_li_def 0;
BA_ "GenSigSendType" SG_ 982 LH_Rueckf_mi_def 0;
BA_ "GenSigSwitchedByIgnition" SG_ 982 LH_Rueckf_mi_def 0;
BA_ "GenSigSendType" SG_ 982 LH_Rueckf_re_def 0;
BA_ "GenSigSwitchedByIgnition" SG_ 982 LH_Rueckf_re_def 0;
BA_ "GenSigSendType" SG_ 982 LH_Rueckfahrlicht_aktiv 0;
BA_ "GenSigSwitchedByIgnition" SG_ 982 LH_Rueckfahrlicht_aktiv 0;
BA_ "GenSigSendType" SG_ 982 LH_Schluss_Brems_li_def 0;
BA_ "GenSigSwitchedByIgnition" SG_ 982 LH_Schluss_Brems_li_def 0;
BA_ "GenSigSendType" SG_ 982 LH_Schluss_Brems_Nebel_li_def 0;
BA_ "GenSigSwitchedByIgnition" SG_ 982 LH_Schluss_Brems_Nebel_li_def 0;
BA_ "GenSigSendType" SG_ 982 LH_Schluss_Brems_Nebel_re_def 0;
BA_ "GenSigSwitchedByIgnition" SG_ 982 LH_Schluss_Brems_Nebel_re_def 0;
BA_ "GenSigSendType" SG_ 982 LH_Schluss_Brems_re_def 0;
BA_ "GenSigSwitchedByIgnition" SG_ 982 LH_Schluss_Brems_re_def 0;
BA_ "GenSigSendType" SG_ 982 LH_Schluss_Nebel_li_def 0;
BA_ "GenSigSwitchedByIgnition" SG_ 982 LH_Schluss_Nebel_li_def 0;
BA_ "GenSigSendType" SG_ 982 LH_Schluss_Nebel_re_def 0;
BA_ "GenSigSwitchedByIgnition" SG_ 982 LH_Schluss_Nebel_re_def 0;
BA_ "GenSigSendType" SG_ 982 LH_Schlusslicht_li_def 0;
BA_ "GenSigSwitchedByIgnition" SG_ 982 LH_Schlusslicht_li_def 0;
BA_ "GenSigSendType" SG_ 982 LH_Schlusslicht_re_def 0;
BA_ "GenSigSwitchedByIgnition" SG_ 982 LH_Schlusslicht_re_def 0;
BA_ "GenSigSendType" SG_ 982 LH_SL_BRL_BLK_li_def 0;
BA_ "GenSigSwitchedByIgnition" SG_ 982 LH_SL_BRL_BLK_li_def 0;
BA_ "GenSigSendType" SG_ 982 LH_SL_BRL_BLK_re_def 0;
BA_ "GenSigSwitchedByIgnition" SG_ 982 LH_SL_BRL_BLK_re_def 0;
BA_ "GenSigSendType" SG_ 982 LH_Standlicht_H_aktiv 0;
BA_ "GenSigSwitchedByIgnition" SG_ 982 LH_Standlicht_H_aktiv 0;
BA_ "GenSigSendType" SG_ 982 LH_Zusatzschlussl_def 0;
BA_ "GenSigSwitchedByIgnition" SG_ 982 LH_Zusatzschlussl_def 0;
BA_ "GenSigSendType" SG_ 982 Licht_hinten_01_BZ 0;
BA_ "GenSigFuncType" SG_ 982 Licht_hinten_01_BZ 1;
BA_ "GenSigSwitchedByIgnition" SG_ 982 Licht_hinten_01_BZ 0;
BA_ "GenSigSendType" SG_ 1624 BCM1_Licht_Dunkelheit_aktiv 3;
BA_ "GenSigSwitchedByIgnition" SG_ 1624 BCM1_Licht_Dunkelheit_aktiv 0;
BA_ "GenSigSendType" SG_ 1624 BCM1_Linksverkehr 0;
BA_ "GenSigSwitchedByIgnition" SG_ 1624 BCM1_Linksverkehr 0;
BA_ "GenSigSendType" SG_ 1624 Licht_Vorne_01_BZ 0;
BA_ "GenSigFuncType" SG_ 1624 Licht_Vorne_01_BZ 1;
BA_ "GenSigSendType" SG_ 1624 Licht_Vorne_01_CRC 0;
BA_ "GenSigFuncType" SG_ 1624 Licht_Vorne_01_CRC 2;
BA_ "GenSigSendType" SG_ 1624 LV_Abbiegelicht_li_def 0;
BA_ "GenSigSwitchedByIgnition" SG_ 1624 LV_Abbiegelicht_li_def 0;
BA_ "GenSigSendType" SG_ 1624 LV_Abbiegelicht_re_def 0;
BA_ "GenSigSwitchedByIgnition" SG_ 1624 LV_Abbiegelicht_re_def 0;
BA_ "GenSigSendType" SG_ 1624 LV_Abblend_Fernlicht_li_def 0;
BA_ "GenSigSwitchedByIgnition" SG_ 1624 LV_Abblend_Fernlicht_li_def 0;
BA_ "GenSigSendType" SG_ 1624 LV_Abblend_Fernlicht_re_def 0;
BA_ "GenSigSwitchedByIgnition" SG_ 1624 LV_Abblend_Fernlicht_re_def 0;
BA_ "GenSigSendType" SG_ 1624 LV_Abblendlicht_Anzeige 3;
BA_ "GenSigSwitchedByIgnition" SG_ 1624 LV_Abblendlicht_Anzeige 0;
BA_ "GenSigSendType" SG_ 1624 LV_Abblendlicht_li_def 0;
BA_ "GenSigSwitchedByIgnition" SG_ 1624 LV_Abblendlicht_li_def 0;
BA_ "GenSigSendType" SG_ 1624 LV_Abblendlicht_re_def 0;
BA_ "GenSigSwitchedByIgnition" SG_ 1624 LV_Abblendlicht_re_def 0;
BA_ "GenSigSendType" SG_ 1624 LV_Abblendlicht_TFL_li_def 0;
BA_ "GenSigSwitchedByIgnition" SG_ 1624 LV_Abblendlicht_TFL_li_def 0;
BA_ "GenSigSendType" SG_ 1624 LV_Abblendlicht_TFL_re_def 0;
BA_ "GenSigSwitchedByIgnition" SG_ 1624 LV_Abblendlicht_TFL_re_def 0;
BA_ "GenSigSendType" SG_ 1624 LV_AFL_aktiv_Anzeige 3;
BA_ "GenSigSwitchedByIgnition" SG_ 1624 LV_AFL_aktiv_Anzeige 0;
BA_ "GenSigSendType" SG_ 1624 LV_AFL_defekt 3;
BA_ "GenSigSwitchedByIgnition" SG_ 1624 LV_AFL_defekt 0;
BA_ "GenSigSendType" SG_ 1624 LV_Aussenlicht_def 0;
BA_ "GenSigSwitchedByIgnition" SG_ 1624 LV_Aussenlicht_def 0;
BA_ "GenSigSendType" SG_ 1624 LV_Blinker_li_def 0;
BA_ "GenSigSwitchedByIgnition" SG_ 1624 LV_Blinker_li_def 0;
BA_ "GenSigSendType" SG_ 1624 LV_Blinker_re_def 0;
BA_ "GenSigSwitchedByIgnition" SG_ 1624 LV_Blinker_re_def 0;
BA_ "GenSigSendType" SG_ 1624 LV_Blinker_VL_aktiv 3;
BA_ "GenSigSwitchedByIgnition" SG_ 1624 LV_Blinker_VL_aktiv 0;
BA_ "GenSigSendType" SG_ 1624 LV_Blinker_VR_aktiv 3;
BA_ "GenSigSwitchedByIgnition" SG_ 1624 LV_Blinker_VR_aktiv 0;
BA_ "GenSigSendType" SG_ 1624 LV_Blk_li_Seite_def 0;
BA_ "GenSigSwitchedByIgnition" SG_ 1624 LV_Blk_li_Seite_def 0;
BA_ "GenSigSendType" SG_ 1624 LV_Blk_re_Seite_def 0;
BA_ "GenSigSwitchedByIgnition" SG_ 1624 LV_Blk_re_Seite_def 0;
BA_ "GenSigSendType" SG_ 1624 LV_Fernlicht_Anzeige 3;
BA_ "GenSigSwitchedByIgnition" SG_ 1624 LV_Fernlicht_Anzeige 0;
BA_ "GenSigSendType" SG_ 1624 LV_Fernlicht_li_def 0;
BA_ "GenSigSwitchedByIgnition" SG_ 1624 LV_Fernlicht_li_def 0;
BA_ "GenSigSendType" SG_ 1624 LV_Fernlicht_re_def 0;
BA_ "GenSigSwitchedByIgnition" SG_ 1624 LV_Fernlicht_re_def 0;
BA_ "GenSigSendType" SG_ 1624 LV_FLA_aktiv_Anzeige 3;
BA_ "GenSigSwitchedByIgnition" SG_ 1624 LV_FLA_aktiv_Anzeige 0;
BA_ "GenSigSendType" SG_ 1624 LV_FLA_defekt 0;
BA_ "GenSigSwitchedByIgnition" SG_ 1624 LV_FLA_defekt 0;
BA_ "GenSigSendType" SG_ 1624 LV_FLA_Sensor_blockiert 0;
BA_ "GenSigSwitchedByIgnition" SG_ 1624 LV_FLA_Sensor_blockiert 0;
BA_ "GenSigSendType" SG_ 1624 LV_LED_Scheinwerfer_li_def 0;
BA_ "GenSigSwitchedByIgnition" SG_ 1624 LV_LED_Scheinwerfer_li_def 0;
BA_ "GenSigSendType" SG_ 1624 LV_LED_Scheinwerfer_re_def 0;
BA_ "GenSigSwitchedByIgnition" SG_ 1624 LV_LED_Scheinwerfer_re_def 0;
BA_ "GenSigSendType" SG_ 1624 LV_MXB_Status_Anzeige 3;
BA_ "GenSigSwitchedByIgnition" SG_ 1624 LV_MXB_Status_Anzeige 0;
BA_ "GenSigSendType" SG_ 1624 LV_Nebellicht_Anzeige 3;
BA_ "GenSigSwitchedByIgnition" SG_ 1624 LV_Nebellicht_Anzeige 0;
BA_ "GenSigSendType" SG_ 1624 LV_Nebellicht_li_def 0;
BA_ "GenSigSwitchedByIgnition" SG_ 1624 LV_Nebellicht_li_def 0;
BA_ "GenSigSendType" SG_ 1624 LV_Nebellicht_re_def 0;
BA_ "GenSigSwitchedByIgnition" SG_ 1624 LV_Nebellicht_re_def 0;
BA_ "GenSigSendType" SG_ 1624 LV_Nebellicht_TFL_li_def 0;
BA_ "GenSigSwitchedByIgnition" SG_ 1624 LV_Nebellicht_TFL_li_def 0;
BA_ "GenSigSendType" SG_ 1624 LV_Nebellicht_TFL_re_def 0;
BA_ "GenSigSwitchedByIgnition" SG_ 1624 LV_Nebellicht_TFL_re_def 0;
BA_ "GenSigSendType" SG_ 1624 LV_Nebelschlusslicht_Anzeige 3;
BA_ "GenSigSwitchedByIgnition" SG_ 1624 LV_Nebelschlusslicht_Anzeige 0;
BA_ "GenSigSendType" SG_ 1624 LV_Standlicht_Anzeige 3;
BA_ "GenSigSwitchedByIgnition" SG_ 1624 LV_Standlicht_Anzeige 0;
BA_ "GenSigSendType" SG_ 1624 LV_Standlicht_li_def 0;
BA_ "GenSigSwitchedByIgnition" SG_ 1624 LV_Standlicht_li_def 0;
BA_ "GenSigSendType" SG_ 1624 LV_Standlicht_re_def 0;
BA_ "GenSigSwitchedByIgnition" SG_ 1624 LV_Standlicht_re_def 0;
BA_ "GenSigSendType" SG_ 1624 LV_Standlicht_TFL_li_def 0;
BA_ "GenSigSwitchedByIgnition" SG_ 1624 LV_Standlicht_TFL_li_def 0;
BA_ "GenSigSendType" SG_ 1624 LV_Standlicht_TFL_re_def 0;
BA_ "GenSigSwitchedByIgnition" SG_ 1624 LV_Standlicht_TFL_re_def 0;
BA_ "GenSigSendType" SG_ 1624 LV_Tagfahrlicht_Anzeige 3;
BA_ "GenSigSwitchedByIgnition" SG_ 1624 LV_Tagfahrlicht_Anzeige 0;
BA_ "GenSigSendType" SG_ 1624 LV_Tagfahrlicht_li_def 0;
BA_ "GenSigSwitchedByIgnition" SG_ 1624 LV_Tagfahrlicht_li_def 0;
BA_ "GenSigSendType" SG_ 1624 LV_Tagfahrlicht_re_def 0;
BA_ "GenSigSwitchedByIgnition" SG_ 1624 LV_Tagfahrlicht_re_def 0;
BA_ "GenSigSendType" SG_ 2527679633 LSH_Ansaug_Fuell_1 0;
BA_ "GenSigStartValue" SG_ 2527679633 LSH_Ansaug_Fuell_1 254;
BA_ "GenSigSwitchedByIgnition" SG_ 2527679633 LSH_Ansaug_Fuell_1 0;
BA_ "Fehlerwert" SG_ 2527679633 LSH_Ansaug_Fuell_1 255;
BA_ "GenSigSendType" SG_ 2527679633 LSH_Ansaug_Fuell_2 0;
BA_ "GenSigStartValue" SG_ 2527679633 LSH_Ansaug_Fuell_2 254;
BA_ "GenSigSwitchedByIgnition" SG_ 2527679633 LSH_Ansaug_Fuell_2 0;
BA_ "Fehlerwert" SG_ 2527679633 LSH_Ansaug_Fuell_2 255;
BA_ "GenSigSendType" SG_ 2527679633 LSH_Empf_Heizstufe 0;
BA_ "GenSigSwitchedByIgnition" SG_ 2527679633 LSH_Empf_Heizstufe 0;
BA_ "Fehlerwert" SG_ 2527679633 LSH_Empf_Heizstufe 15;
BA_ "GenSigSendType" SG_ 2527679633 LSH_Funk_aus 0;
BA_ "GenSigSwitchedByIgnition" SG_ 2527679633 LSH_Funk_aus 0;
BA_ "GenSigSendType" SG_ 2527679633 LSH_Funk_ein 0;
BA_ "GenSigSwitchedByIgnition" SG_ 2527679633 LSH_Funk_ein 0;
BA_ "GenSigSendType" SG_ 2527679633 LSH_Geblaese_aktiv 0;
BA_ "GenSigSwitchedByIgnition" SG_ 2527679633 LSH_Geblaese_aktiv 0;
BA_ "GenSigSendType" SG_ 2527679633 LSH_Heiztemp 0;
BA_ "GenSigStartValue" SG_ 2527679633 LSH_Heiztemp 254;
BA_ "GenSigSwitchedByIgnition" SG_ 2527679633 LSH_Heiztemp 0;
BA_ "Fehlerwert" SG_ 2527679633 LSH_Heiztemp 255;
BA_ "GenSigSendType" SG_ 2527679633 LSH_Klappe_Status 0;
BA_ "GenSigSwitchedByIgnition" SG_ 2527679633 LSH_Klappe_Status 0;
BA_ "GenSigSendType" SG_ 2527679633 LSH_LED 0;
BA_ "GenSigSwitchedByIgnition" SG_ 2527679633 LSH_LED 0;
BA_ "GenSigSendType" SG_ 2527679633 LSH_Servicemode 0;
BA_ "GenSigSwitchedByIgnition" SG_ 2527679633 LSH_Servicemode 0;
BA_ "GenSigSendType" SG_ 2527679633 LSH_Start_folgt 0;
BA_ "GenSigSwitchedByIgnition" SG_ 2527679633 LSH_Start_folgt 0;
BA_ "GenSigSendType" SG_ 2527679633 LSH_Texte 0;
BA_ "GenSigSwitchedByIgnition" SG_ 2527679633 LSH_Texte 0;
BA_ "GenSigSendType" SG_ 2527679633 LSH_Waermeeintrag 0;
BA_ "GenSigStartValue" SG_ 2527679633 LSH_Waermeeintrag 510;
BA_ "GenSigSwitchedByIgnition" SG_ 2527679633 LSH_Waermeeintrag 0;
BA_ "Fehlerwert" SG_ 2527679633 LSH_Waermeeintrag 511;
BA_ "GenSigSendType" SG_ 917 AFS_Abbiegelicht_Dimm_Anf 0;
BA_ "GenSigSendType" SG_ 917 AFS_Abbiegelicht_li_Anf 0;
BA_ "GenSigSendType" SG_ 917 AFS_Abbiegelicht_re_Anf 0;
BA_ "GenSigSendType" SG_ 917 AFS_adaptive_LV_verbaut 0;
BA_ "GenSigSendType" SG_ 917 AFS_Allwetterlicht 0;
BA_ "GenSigSendType" SG_ 917 AFS_Charisma_FahrPr 0;
BA_ "GenSigSendType" SG_ 917 AFS_Charisma_Status 0;
BA_ "GenSigSendType" SG_ 917 AFS_Ersatzlicht_Links 0;
BA_ "GenSigSendType" SG_ 917 AFS_Ersatzlicht_Rechts 0;
BA_ "GenSigSendType" SG_ 917 AFS_Fehlertext 0;
BA_ "GenSigSendType" SG_ 917 AFS_Fernlicht_li_defekt 0;
BA_ "GenSigSendType" SG_ 917 AFS_Fernlicht_re_defekt 0;
BA_ "GenSigSendType" SG_ 917 AFS_Fernlicht_Status 3;
BA_ "GenSigSendType" SG_ 917 AFS_Lampe 0;
BA_ "GenSigSendType" SG_ 917 AFS_LED_Blinkmode 0;
BA_ "GenSigSendType" SG_ 917 AFS_Status_adaptive_LV 0;
BA_ "GenSigStartValue" SG_ 917 AFS_Status_adaptive_LV 1;
BA_ "GenSigSendType" SG_ 917 AFS_Verfuegbarkeit_GLW 0;
BA_ "GenSigStartValue" SG_ 917 AFS_Verfuegbarkeit_GLW 1;
BA_ "GenSigSendType" SG_ 917 GLW_Sensor_blockiert 0;
BA_ "GenSigSendType" SG_ 917 LWR_AFS_01_BZ 0;
BA_ "GenSigFuncType" SG_ 917 LWR_AFS_01_BZ 1;
BA_ "GenSigSendType" SG_ 917 LWR_AFS_Grundeinstellung 0;
BA_ "GenSigSendType" SG_ 917 LWR_AFS_Parametrisierung 0;
BA_ "GenSigSendType" SG_ 917 LWR_Hoehenwert_HL 0;
BA_ "GenSigStartValue" SG_ 917 LWR_Hoehenwert_HL 254;
BA_ "Fehlerwert" SG_ 917 LWR_Hoehenwert_HL 255;
BA_ "GenSigSendType" SG_ 917 LWR_Hoehenwert_VL 0;
BA_ "GenSigStartValue" SG_ 917 LWR_Hoehenwert_VL 254;
BA_ "Fehlerwert" SG_ 917 LWR_Hoehenwert_VL 255;
BA_ "GenSigSendType" SG_ 917 LWR_Initialisierungslauf 0;
BA_ "GenSigSendType" SG_ 917 LWR_Lampe 0;
BA_ "GenSigSendType" SG_ 917 LWR_Modus 0;
BA_ "GenSigSendType" SG_ 917 LWR_Pos_Schrittmotor 0;
BA_ "GenSigStartValue" SG_ 917 LWR_Pos_Schrittmotor 254;
BA_ "Fehlerwert" SG_ 917 LWR_Pos_Schrittmotor 255;
BA_ "GenSigSendType" SG_ 917 LWR_Reisemodus_Texte 0;
BA_ "GenSigSendType" SG_ 917 LWR_Sicherheitsposition 0;
BA_ "GenSigSendType" SG_ 917 LWR_Touristenmodus_aktiv 0;
BA_ "GenSigSendType" SG_ 917 LWR_Touristenmodus_verbaut 0;
BA_ "GenSigSendType" SG_ 1153 DSSS_Warning 3;
BA_ "GenSigSwitchedByIgnition" SG_ 1153 DSSS_Warning 0;
BA_ "GenSigSendType" SG_ 1153 MIB_ASW_Diagnose 0;
BA_ "GenSigSwitchedByIgnition" SG_ 1153 MIB_ASW_Diagnose 0;
BA_ "GenSigSendType" SG_ 1153 MIB_Tongenerator_PH_verfuegbar 3;
BA_ "GenSigSwitchedByIgnition" SG_ 1153 MIB_Tongenerator_PH_verfuegbar 0;
BA_ "GenSigSendType" SG_ 1153 MMI_Counter_Bedienevent 0;
BA_ "GenSigSwitchedByIgnition" SG_ 1153 MMI_Counter_Bedienevent 0;
BA_ "GenSigSendType" SG_ 1153 MMI_Gurt_Mic_ref 3;
BA_ "GenSigSwitchedByIgnition" SG_ 1153 MMI_Gurt_Mic_ref 0;
BA_ "GenSigSendType" SG_ 1153 MMI_SDS_aktiv 3;
BA_ "GenSigSwitchedByIgnition" SG_ 1153 MMI_SDS_aktiv 0;
BA_ "GenSigSendType" SG_ 1153 MMI_Telefon_aktiv 3;
BA_ "GenSigSwitchedByIgnition" SG_ 1153 MMI_Telefon_aktiv 0;
BA_ "GenSigSendType" SG_ 1153 MU_SecondDisplay 3;
BA_ "GenSigSwitchedByIgnition" SG_ 1153 MU_SecondDisplay 0;
BA_ "GenSigSendType" SG_ 1153 MU_Update_Time 0;
BA_ "GenSigSwitchedByIgnition" SG_ 1153 MU_Update_Time 0;
BA_ "GenSigSendType" SG_ 1153 Nav_FoD_Status 0;
BA_ "GenSigSwitchedByIgnition" SG_ 1153 Nav_FoD_Status 0;
BA_ "GenSigSendType" SG_ 1153 ZR_AppConnect_Zustand 4;
BA_ "GenSigSwitchedByIgnition" SG_ 1153 ZR_AppConnect_Zustand 0;
BA_ "GenSigSendType" SG_ 1153 ZR_Kindersicherung_RSE 3;
BA_ "GenSigSwitchedByIgnition" SG_ 1153 ZR_Kindersicherung_RSE 0;
BA_ "GenSigSendType" SG_ 1153 ZR_Lichter_Tag 3;
BA_ "GenSigSwitchedByIgnition" SG_ 1153 ZR_Lichter_Tag 0;
BA_ "GenSigSendType" SG_ 1153 ZR_LoGeWa_Event_Kombiwarnung 3;
BA_ "GenSigSwitchedByIgnition" SG_ 1153 ZR_LoGeWa_Event_Kombiwarnung 0;
BA_ "GenSigSendType" SG_ 1153 ZR_Parken_Sondermodus 3;
BA_ "GenSigSwitchedByIgnition" SG_ 1153 ZR_Parken_Sondermodus 0;
BA_ "GenSigSendType" SG_ 1153 ZR_RSE_aktivieren 3;
BA_ "GenSigSwitchedByIgnition" SG_ 1153 ZR_RSE_aktivieren 0;
BA_ "GenSigSendType" SG_ 1153 ZR_Sta_Inszenierung 4;
BA_ "GenSigSwitchedByIgnition" SG_ 1153 ZR_Sta_Inszenierung 0;
BA_ "GenSigSendType" SG_ 2527679860 MDK_Change_Polling_Mode 0;
BA_ "GenSigSwitchedByIgnition" SG_ 2527679860 MDK_Change_Polling_Mode 0;
BA_ "GenSigSendType" SG_ 2527679860 MDK_Function_State 0;
BA_ "GenSigSwitchedByIgnition" SG_ 2527679860 MDK_Function_State 0;
BA_ "GenSigSendType" SG_ 1639 BFS_Fond_Bed_Ack 3;
BA_ "GenSigSwitchedByIgnition" SG_ 1639 BFS_Fond_Bed_Ack 0;
BA_ "GenSigSendType" SG_ 1639 BFS_FSV_ausgeklappt 0;
BA_ "GenSigSwitchedByIgnition" SG_ 1639 BFS_FSV_ausgeklappt 0;
BA_ "GenSigSendType" SG_ 1639 BFS_GHV_aktiv 3;
BA_ "GenSigSwitchedByIgnition" SG_ 1639 BFS_GHV_aktiv 0;
BA_ "GenSigSendType" SG_ 1639 BFS_Gurtbringer_Sperre 0;
BA_ "GenSigSwitchedByIgnition" SG_ 1639 BFS_Gurtbringer_Sperre 0;
BA_ "GenSigSendType" SG_ 1639 BFS_Klappfunktion_Aktiv 3;
BA_ "GenSigSwitchedByIgnition" SG_ 1639 BFS_Klappfunktion_Aktiv 0;
BA_ "GenSigSendType" SG_ 1639 BFS_Klappfunktion_Bed_Ack 3;
BA_ "GenSigSwitchedByIgnition" SG_ 1639 BFS_Klappfunktion_Bed_Ack 0;
BA_ "GenSigSendType" SG_ 1639 BFS_Klappfunktion_Beschraenkung 3;
BA_ "GenSigSwitchedByIgnition" SG_ 1639 BFS_Klappfunktion_Beschraenkung 0;
BA_ "GenSigSendType" SG_ 1639 BFS_Klappfunktion_Status 3;
BA_ "GenSigSwitchedByIgnition" SG_ 1639 BFS_Klappfunktion_Status 0;
BA_ "GenSigSendType" SG_ 1639 BFS_Klapptisch_offen 3;
BA_ "GenSigSwitchedByIgnition" SG_ 1639 BFS_Klapptisch_offen 0;
BA_ "GenSigSendType" SG_ 1639 BFS_KSS_Fahrt_aktiv 3;
BA_ "GenSigSwitchedByIgnition" SG_ 1639 BFS_KSS_Fahrt_aktiv 0;
BA_ "GenSigSendType" SG_ 1639 BFS_KSV_aktiv 3;
BA_ "GenSigSwitchedByIgnition" SG_ 1639 BFS_KSV_aktiv 0;
BA_ "GenSigSendType" SG_ 1639 BFS_Lehne_nicht_verriegelt 3;
BA_ "GenSigSwitchedByIgnition" SG_ 1639 BFS_Lehne_nicht_verriegelt 0;
BA_ "GenSigSendType" SG_ 1639 BFS_LHV_aktiv 3;
BA_ "GenSigSwitchedByIgnition" SG_ 1639 BFS_LHV_aktiv 0;
BA_ "GenSigSendType" SG_ 1639 BFS_LKV_aktiv 3;
BA_ "GenSigSwitchedByIgnition" SG_ 1639 BFS_LKV_aktiv 0;
BA_ "GenSigSendType" SG_ 1639 BFS_LNV_aktiv 3;
BA_ "GenSigSwitchedByIgnition" SG_ 1639 BFS_LNV_aktiv 0;
BA_ "GenSigSendType" SG_ 1639 BFS_LWV_aktiv 3;
BA_ "GenSigSwitchedByIgnition" SG_ 1639 BFS_LWV_aktiv 0;
BA_ "GenSigSendType" SG_ 1639 BFS_MMB_glob_stop 3;
BA_ "GenSigSwitchedByIgnition" SG_ 1639 BFS_MMB_glob_stop 0;
BA_ "GenSigSendType" SG_ 1639 BFS_MMB_lokal_Stop 3;
BA_ "GenSigSwitchedByIgnition" SG_ 1639 BFS_MMB_lokal_Stop 0;
BA_ "GenSigSendType" SG_ 1639 BFS_MMB_storage 3;
BA_ "GenSigSwitchedByIgnition" SG_ 1639 BFS_MMB_storage 0;
BA_ "GenSigSendType" SG_ 1639 BFS_MMB_storage_beep 3;
BA_ "GenSigSwitchedByIgnition" SG_ 1639 BFS_MMB_storage_beep 0;
BA_ "GenSigSendType" SG_ 1639 BFS_MMB_store 3;
BA_ "GenSigSwitchedByIgnition" SG_ 1639 BFS_MMB_store 0;
BA_ "GenSigSendType" SG_ 1639 BFS_MMB_store_LED_on 3;
BA_ "GenSigSwitchedByIgnition" SG_ 1639 BFS_MMB_store_LED_on 0;
BA_ "GenSigSendType" SG_ 1639 BFS_MMB_tast 3;
BA_ "GenSigSwitchedByIgnition" SG_ 1639 BFS_MMB_tast 0;
BA_ "GenSigSendType" SG_ 1639 BFS_MMB_tipp 3;
BA_ "GenSigSwitchedByIgnition" SG_ 1639 BFS_MMB_tipp 0;
BA_ "GenSigSendType" SG_ 1639 BFS_Ruhestellung_Status 3;
BA_ "GenSigSwitchedByIgnition" SG_ 1639 BFS_Ruhestellung_Status 0;
BA_ "GenSigSendType" SG_ 1639 BFS_Seat_Locked 0;
BA_ "GenSigSwitchedByIgnition" SG_ 1639 BFS_Seat_Locked 0;
BA_ "GenSigSendType" SG_ 1639 BFS_SHV_aktiv 3;
BA_ "GenSigSwitchedByIgnition" SG_ 1639 BFS_SHV_aktiv 0;
BA_ "GenSigSendType" SG_ 1639 BFS_Sitzfahrt_aktiv 3;
BA_ "GenSigSwitchedByIgnition" SG_ 1639 BFS_Sitzfahrt_aktiv 0;
BA_ "GenSigSendType" SG_ 1639 BFS_Sitzsym_Fahrt_aktiv 3;
BA_ "GenSigSwitchedByIgnition" SG_ 1639 BFS_Sitzsym_Fahrt_aktiv 0;
BA_ "GenSigSendType" SG_ 1639 BFS_SLV_aktiv 3;
BA_ "GenSigSwitchedByIgnition" SG_ 1639 BFS_SLV_aktiv 0;
BA_ "GenSigSendType" SG_ 1639 BFS_SNV_aktiv 3;
BA_ "GenSigSwitchedByIgnition" SG_ 1639 BFS_SNV_aktiv 0;
BA_ "GenSigSendType" SG_ 1639 BFS_STV_aktiv 3;
BA_ "GenSigSwitchedByIgnition" SG_ 1639 BFS_STV_aktiv 0;
BA_ "GenSigSendType" SG_ 1639 Mem_BFS_01_BZ 0;
BA_ "GenSigFuncType" SG_ 1639 Mem_BFS_01_BZ 1;
BA_ "GenSigSwitchedByIgnition" SG_ 1639 Mem_BFS_01_BZ 0;
BA_ "GenSigSendType" SG_ 1639 Mem_BFS_01_CRC 0;
BA_ "GenSigFuncType" SG_ 1639 Mem_BFS_01_CRC 2;
BA_ "GenSigSwitchedByIgnition" SG_ 1639 Mem_BFS_01_CRC 0;
BA_REL_ "GenSigTimeoutTime" BU_SG_REL_ BCM SG_ 779 KBI_Tankwarnung 500;
BA_REL_ "GenSigTimeoutTime" BU_SG_REL_ BCM SG_ 779 KBI_Handbremse 500;
BA_REL_ "GenSigTimeoutTime" BU_SG_REL_ BCM SG_ 779 KBI_angez_Geschw 500;
BA_REL_ "GenSigTimeoutTime" BU_SG_REL_ BCM SG_ 1719 KBI_Kilometerstand 5000;
BA_REL_ "GenSigTimeoutTime" BU_SG_REL_ BCM SG_ 1719 KBI_Standzeit_02 5000;
BA_REL_ "GenSigTimeoutTime" BU_SG_REL_ BCM SG_ 1719 KBI_Inhalt_Tank 5000;
BA_REL_ "GenSigTimeoutTime" BU_SG_REL_ BCM SG_ 1719 KBI_aktive_Laengsfunktion_02 5000;
BA_REL_ "GenSigTimeoutTime" BU_SG_REL_ BCM SG_ 1719 KBI_QBit_Aussen_Temp_gef 5000;
BA_REL_ "GenSigTimeoutTime" BU_SG_REL_ BCM SG_ 1719 KBI_Aussen_Temp_gef 5000;
BA_REL_ "GenSigTimeoutTime" BU_SG_REL_ BCM SG_ 1722 SOK_Kombi_03_Signatur 5000;
BA_REL_ "GenSigTimeoutTime" BU_SG_REL_ BCM SG_ 1720 KBI_Reifenumfang 5000;
BA_REL_ "GenSigTimeoutTime" BU_SG_REL_ BCM SG_ 2527679639 AuthTime_Trigger_Distribution 5000;
BA_REL_ "GenSigTimeoutTime" BU_SG_REL_ BCM SG_ 1387 LCM_TFL_Fehler_L 2000;
BA_REL_ "GenSigTimeoutTime" BU_SG_REL_ BCM SG_ 1387 LCM_Sonstiger_Fehler_L 2000;
BA_REL_ "GenSigTimeoutTime" BU_SG_REL_ BCM SG_ 1387 LCM_SM_Fehler_L 2000;
BA_REL_ "GenSigTimeoutTime" BU_SG_REL_ BCM SG_ 1387 LCM_Shutter_Fehler_L 2000;
BA_REL_ "GenSigTimeoutTime" BU_SG_REL_ BCM SG_ 1387 LCM_PO_Fehler_L 2000;
BA_REL_ "GenSigTimeoutTime" BU_SG_REL_ BCM SG_ 1387 LCM_Blinker_Fehler_L 2000;
BA_REL_ "GenSigTimeoutTime" BU_SG_REL_ BCM SG_ 1387 LCM_LWR_L_allg_Fehler 2000;
BA_REL_ "GenSigTimeoutTime" BU_SG_REL_ BCM SG_ 1387 LCM_LWR_L_defekt_Fehler 2000;
BA_REL_ "GenSigTimeoutTime" BU_SG_REL_ BCM SG_ 1387 LCM_Datensatz_Fehler_L 2000;
BA_REL_ "GenSigTimeoutTime" BU_SG_REL_ BCM SG_ 1387 LCM_DKL_L_defekt_Fehler 2000;
BA_REL_ "GenSigTimeoutTime" BU_SG_REL_ BCM SG_ 1387 LCM_GLW_L_defekt_Fehler 2000;
BA_REL_ "GenSigTimeoutTime" BU_SG_REL_ BCM SG_ 1387 LCM_SKL_L_defekt_Fehler 2000;
BA_REL_ "GenSigTimeoutTime" BU_SG_REL_ BCM SG_ 1388 LCM_TFL_Fehler_R 2000;
BA_REL_ "GenSigTimeoutTime" BU_SG_REL_ BCM SG_ 1388 LCM_Sonstiger_Fehler_R 2000;
BA_REL_ "GenSigTimeoutTime" BU_SG_REL_ BCM SG_ 1388 LCM_SM_Fehler_R 2000;
BA_REL_ "GenSigTimeoutTime" BU_SG_REL_ BCM SG_ 1388 LCM_Shutter_Fehler_R 2000;
BA_REL_ "GenSigTimeoutTime" BU_SG_REL_ BCM SG_ 1388 LCM_PO_Fehler_R 2000;
BA_REL_ "GenSigTimeoutTime" BU_SG_REL_ BCM SG_ 1388 LCM_Blinker_Fehler_R 2000;
BA_REL_ "GenSigTimeoutTime" BU_SG_REL_ BCM SG_ 1388 LCM_LWR_R_allg_Fehler 2000;
BA_REL_ "GenSigTimeoutTime" BU_SG_REL_ BCM SG_ 1388 LCM_LWR_R_defekt_Fehler 2000;
BA_REL_ "GenSigTimeoutTime" BU_SG_REL_ BCM SG_ 1388 LCM_Datensatz_Fehler_R 2000;
BA_REL_ "GenSigTimeoutTime" BU_SG_REL_ BCM SG_ 1388 LCM_DKL_R_defekt_Fehler 2000;
BA_REL_ "GenSigTimeoutTime" BU_SG_REL_ BCM SG_ 1388 LCM_GLW_R_defekt_Fehler 2000;
BA_REL_ "GenSigTimeoutTime" BU_SG_REL_ BCM SG_ 1388 LCM_SKL_R_defekt_Fehler 2000;
BA_REL_ "GenSigTimeoutTime" BU_SG_REL_ BCM SG_ 411 LCM_Abschaltbestaetigung_L 1000;
BA_REL_ "GenSigTimeoutTime" BU_SG_REL_ BCM SG_ 411 LCM_Blinker_L_Sta 1000;
BA_REL_ "GenSigTimeoutTime" BU_SG_REL_ BCM SG_ 413 LCM_Abschaltbestaetigung_R 1000;
BA_REL_ "GenSigTimeoutTime" BU_SG_REL_ BCM SG_ 413 LCM_Blinker_R_Sta 1000;
BA_REL_ "GenSigTimeoutTime" BU_SG_REL_ BCM SG_ 2527679510 LED_L_Abbiegel_Def 2000;
BA_REL_ "GenSigTimeoutTime" BU_SG_REL_ BCM SG_ 2527679510 LED_L_Abblendl_Def 2000;
BA_REL_ "GenSigTimeoutTime" BU_SG_REL_ BCM SG_ 2527679510 LED_L_Allg_Elektr_Def 2000;
BA_REL_ "GenSigTimeoutTime" BU_SG_REL_ BCM SG_ 2527679510 LED_L_Fernl_Def 2000;
BA_REL_ "GenSigTimeoutTime" BU_SG_REL_ BCM SG_ 2527679510 LED_L_falsch_codiert 2000;
BA_REL_ "GenSigTimeoutTime" BU_SG_REL_ BCM SG_ 2527679510 LED_L_Zus_Fernl_LH_Def 2000;
BA_REL_ "GenSigTimeoutTime" BU_SG_REL_ BCM SG_ 2527679510 LED_L_Laser_Def 2000;
BA_REL_ "GenSigTimeoutTime" BU_SG_REL_ BCM SG_ 2527679511 LED_R_Abbiegel_Def 2000;
BA_REL_ "GenSigTimeoutTime" BU_SG_REL_ BCM SG_ 2527679511 LED_R_Abblendl_Def 2000;
BA_REL_ "GenSigTimeoutTime" BU_SG_REL_ BCM SG_ 2527679511 LED_R_Allg_Elektr_Def 2000;
BA_REL_ "GenSigTimeoutTime" BU_SG_REL_ BCM SG_ 2527679511 LED_R_Fernl_Def 2000;
BA_REL_ "GenSigTimeoutTime" BU_SG_REL_ BCM SG_ 2527679511 LED_R_falsch_codiert 2000;
BA_REL_ "GenSigTimeoutTime" BU_SG_REL_ BCM SG_ 2527679511 LED_R_Zus_Fernl_LH_Def 2000;
BA_REL_ "GenSigTimeoutTime" BU_SG_REL_ BCM SG_ 2527679511 LED_R_Laser_Def 2000;
BA_REL_ "GenSigTimeoutTime" BU_SG_REL_ BCM SG_ 2527679633 LSH_Geblaese_aktiv 2000;
BA_REL_ "GenSigTimeoutTime" BU_SG_REL_ BCM SG_ 917 AFS_Verfuegbarkeit_GLW 1000;
BA_REL_ "GenSigTimeoutTime" BU_SG_REL_ BCM SG_ 917 AFS_Status_adaptive_LV 1000;
BA_REL_ "GenSigTimeoutTime" BU_SG_REL_ BCM SG_ 917 AFS_Fernlicht_li_defekt 1000;
BA_REL_ "GenSigTimeoutTime" BU_SG_REL_ BCM SG_ 917 AFS_Fernlicht_re_defekt 1000;
BA_REL_ "GenSigTimeoutTime" BU_SG_REL_ BCM SG_ 917 AFS_Fernlicht_Status 1000;
BA_REL_ "GenSigTimeoutTime" BU_SG_REL_ BCM SG_ 917 LWR_Touristenmodus_aktiv 1000;
BA_REL_ "GenSigTimeoutTime" BU_SG_REL_ BCM SG_ 917 AFS_Allwetterlicht 1000;
BA_REL_ "GenSigTimeoutTime" BU_SG_REL_ BCM SG_ 917 LWR_Touristenmodus_verbaut 1000;
BA_REL_ "GenSigTimeoutTime" BU_SG_REL_ BCM SG_ 917 AFS_adaptive_LV_verbaut 1000;
BA_REL_ "GenSigTimeoutTime" BU_SG_REL_ BCM SG_ 917 GLW_Sensor_blockiert 1000;
BA_REL_ "GenSigTimeoutTime" BU_SG_REL_ BCM SG_ 1153 ZR_Lichter_Tag 5000;
BA_REL_ "GenSigTimeoutTime" BU_SG_REL_ BCM SG_ 1153 ZR_Sta_Inszenierung 5000;
BA_REL_ "GenSigTimeoutTime" BU_SG_REL_ BCM SG_ 1639 BFS_MMB_storage 1000;
BA_REL_ "GenSigTimeoutTime" BU_SG_REL_ BCM SG_ 1639 BFS_MMB_tipp 1000;
BA_REL_ "GenSigTimeoutTime" BU_SG_REL_ BCM SG_ 1639 BFS_MMB_tast 1000;
BA_REL_ "GenSigTimeoutTime" BU_SG_REL_ BCM SG_ 1639 BFS_MMB_glob_stop 1000;
BA_REL_ "GenSigTimeoutTime" BU_SG_REL_ Gateway_Max SG_ 2549088319 TSG_HBFS_Nachlauftyp 5000;
BA_REL_ "GenSigTimeoutTime" BU_SG_REL_ Gateway_Max SG_ 2549088319 KN_TSG_HBFS_DiagPfad 5000;
BA_REL_ "GenSigTimeoutTime" BU_SG_REL_ Gateway_Max SG_ 2549088319 TSG_HBFS_KD_Fehler 2500;
BA_REL_ "GenSigTimeoutTime" BU_SG_REL_ Gateway_Max SG_ 2549088318 TSG_HFS_Nachlauftyp 5000;
BA_REL_ "GenSigTimeoutTime" BU_SG_REL_ Gateway_Max SG_ 2549088318 KN_TSG_HFS_DiagPfad 5000;
BA_REL_ "GenSigTimeoutTime" BU_SG_REL_ Gateway_Max SG_ 2549088318 TSG_HFS_KD_Fehler 2500;
BA_REL_ "GenSigTimeoutTime" BU_SG_REL_ Gateway_Max SG_ 2549088421 WLC1_Nachlauftyp 5000;
BA_REL_ "GenSigTimeoutTime" BU_SG_REL_ Gateway_Max SG_ 2549088421 KN_WLC1_DiagPfad 5000;
BA_REL_ "GenSigTimeoutTime" BU_SG_REL_ Gateway_Max SG_ 2549088421 WLC1_KD_Fehler 2500;
BA_REL_ "GenSigTimeoutTime" BU_SG_REL_ Gateway_Max SG_ 981 BCM1_Parklicht_li_Anf 1000;
BA_REL_ "GenSigTimeoutTime" BU_SG_REL_ Gateway_Max SG_ 981 BCM1_Parklicht_re_Anf 1000;
BA_REL_ "GenSigTimeoutTime" BU_SG_REL_ Gateway_Max SG_ 981 BCM_Rueckfahrlicht_Anf 1000;
BA_REL_ "GenSigTimeoutTime" BU_SG_REL_ Gateway_Max SG_ 1624 LV_Standlicht_Anzeige 5000;
BA_REL_ "GenSigTimeoutTime" BU_SG_REL_ Gateway_Max SG_ 1624 LV_Nebellicht_Anzeige 5000;
BA_REL_ "GenSigTimeoutTime" BU_SG_REL_ Gateway_Max SG_ 1624 LV_Nebelschlusslicht_Anzeige 5000;
BA_REL_ "GenSigTimeoutTime" BU_SG_REL_ TSGGen3_BFS SG_ 1719 KBI_QBit_Aussen_Temp_gef 5000;
BA_REL_ "GenSigTimeoutTime" BU_SG_REL_ TSGGen3_BFS SG_ 1719 KBI_Aussen_Temp_gef 5000;
BA_REL_ "GenSigTimeoutTime" BU_SG_REL_ TSGGen3_BFS SG_ 981 BCM_Rueckfahrlicht_Anf 1000;
BA_REL_ "GenSigTimeoutTime" BU_SG_REL_ TSGGen3_BFS SG_ 981 BCM1_Umfeldleuchten_Anf 1000;
BA_REL_ "GenSigTimeoutTime" BU_SG_REL_ TSGGen3_BFS SG_ 981 BCM1_LH_aktiv 1000;
BA_REL_ "GenSigTimeoutTime" BU_SG_REL_ TSGGen3_BFS SG_ 1639 BFS_Gurtbringer_Sperre 1000;
BA_REL_ "GenSigTimeoutTime" BU_SG_REL_ TSGGen3_BFS SG_ 1639 BFS_Sitzfahrt_aktiv 1000;
BA_REL_ "GenSigTimeoutTime" BU_SG_REL_ TSGGen3_BFS SG_ 1639 BFS_MMB_storage 1000;
BA_REL_ "GenSigTimeoutTime" BU_SG_REL_ TSGGen3_BFS SG_ 1639 BFS_MMB_tipp 1000;
BA_REL_ "GenSigTimeoutTime" BU_SG_REL_ TSGGen3_BFS SG_ 1639 BFS_MMB_tast 1000;
BA_REL_ "GenSigTimeoutTime" BU_SG_REL_ TSGGen3_BFS SG_ 1639 BFS_MMB_store_LED_on 1000;
BA_REL_ "GenSigTimeoutTime" BU_SG_REL_ TSGGen3_BFS SG_ 1639 BFS_MMB_store 1000;
BA_REL_ "GenSigTimeoutTime" BU_SG_REL_ TSGGen3_BFS SG_ 1639 BFS_MMB_glob_stop 1000;
BA_REL_ "GenSigTimeoutTime" BU_SG_REL_ TSGGen3_FS SG_ 1719 KBI_QBit_Aussen_Temp_gef 5000;
BA_REL_ "GenSigTimeoutTime" BU_SG_REL_ TSGGen3_FS SG_ 1719 KBI_Aussen_Temp_gef 5000;
BA_REL_ "GenSigTimeoutTime" BU_SG_REL_ TSGGen3_FS SG_ 981 BCM_Rueckfahrlicht_Anf 1000;
BA_REL_ "GenSigTimeoutTime" BU_SG_REL_ TSGGen3_FS SG_ 981 BCM1_Umfeldleuchten_Anf 1000;
BA_REL_ "GenSigTimeoutTime" BU_SG_REL_ TSGGen3_FS SG_ 981 BCM1_LH_aktiv 1000;
BA_REL_ "GenSigTimeoutTime" BU_SG_REL_ TSGGen3_FS SG_ 1639 BFS_Gurtbringer_Sperre 1000;
BA_REL_ "GenSigTimeoutTime" BU_SG_REL_ TSGGen3_FS SG_ 1639 BFS_Sitzfahrt_aktiv 1000;
BA_REL_ "GenSigTimeoutTime" BU_SG_REL_ TSGGen3_HBFS SG_ 1719 KBI_QBit_Aussen_Temp_gef 5000;
BA_REL_ "GenSigTimeoutTime" BU_SG_REL_ TSGGen3_HBFS SG_ 1719 KBI_Aussen_Temp_gef 5000;
BA_REL_ "GenSigTimeoutTime" BU_SG_REL_ TSGGen3_HBFS SG_ 981 BCM_Rueckfahrlicht_Anf 1000;
BA_REL_ "GenSigTimeoutTime" BU_SG_REL_ TSGGen3_HBFS SG_ 981 BCM1_Umfeldleuchten_Anf 1000;
BA_REL_ "GenSigTimeoutTime" BU_SG_REL_ TSGGen3_HBFS SG_ 981 BCM1_LH_aktiv 1000;
BA_REL_ "GenSigTimeoutTime" BU_SG_REL_ TSGGen3_HBFS SG_ 1639 BFS_Gurtbringer_Sperre 1000;
BA_REL_ "GenSigTimeoutTime" BU_SG_REL_ TSGGen3_HBFS SG_ 1639 BFS_Sitzfahrt_aktiv 1000;
BA_REL_ "GenSigTimeoutTime" BU_SG_REL_ TSGGen3_HFS SG_ 1719 KBI_QBit_Aussen_Temp_gef 5000;
BA_REL_ "GenSigTimeoutTime" BU_SG_REL_ TSGGen3_HFS SG_ 1719 KBI_Aussen_Temp_gef 5000;
BA_REL_ "GenSigTimeoutTime" BU_SG_REL_ TSGGen3_HFS SG_ 981 BCM_Rueckfahrlicht_Anf 1000;
BA_REL_ "GenSigTimeoutTime" BU_SG_REL_ TSGGen3_HFS SG_ 981 BCM1_Umfeldleuchten_Anf 1000;
BA_REL_ "GenSigTimeoutTime" BU_SG_REL_ TSGGen3_HFS SG_ 981 BCM1_LH_aktiv 1000;
BA_REL_ "GenSigTimeoutTime" BU_SG_REL_ TSGGen3_HFS SG_ 1639 BFS_Gurtbringer_Sperre 1000;
BA_REL_ "GenSigTimeoutTime" BU_SG_REL_ TSGGen3_HFS SG_ 1639 BFS_Sitzfahrt_aktiv 1000;
BA_REL_ "GenSigTimeoutTime" BU_SG_REL_ WLC_01_CFD SG_ 2527679860 MDK_Change_Polling_Mode 2000;
BA_REL_ "GenSigTimeoutTime" BU_SG_REL_ WLC_01_CFD SG_ 2527679860 MDK_Function_State 2000;
VAL_ 2549088319 TSG_HBFS_KompSchutz 0 "inaktiv" 1 "aktiv" ;
VAL_ 2549088319 TSG_HBFS_Abschaltstufe 0 "keine_Einschraenkung" 1 "Funktionseinschraenkung" ;
VAL_ 2549088319 TSG_HBFS_Transport_Mode 0 "keine_Einschraenkung" 1 "Funktionseinschraenkung" ;
VAL_ 2549088319 TSG_HBFS_Nachlauftyp 0 "Komm_bei_KL15_EIN" 1 "Komm_nach_KL15_AUS" 2 "Komm_bei_KL15_AUS" ;
VAL_ 2549088319 KN_TSG_HBFS_ECUKnockOutTimer 63 "ECUKnockOut_deaktiviert" ;
VAL_ 2549088319 KN_TSG_HBFS_BusKnockOut 0 "Funktion_nicht_ausgeloest" 1 "Veto_aktiv" 2 "Funktion_ausgeloest" 3 "Funktion_deaktiviert" ;
VAL_ 2549088319 KN_TSG_HBFS_BusKnockOutTimer 255 "BusKnockOut_deaktiviert" ;
VAL_ 2549088319 NM_TSG_HBFS_Wakeup 0 "Peripherie_Wakeup_Ursache_nicht_bekannt" 1 "Bus_Wakeup" 2 "KL15_HW" ;
VAL_ 2549088319 KN_TSG_HBFS_ECUKnockOut 0 "Funktion_nicht_ausgeloest" 1 "Veto_war_aktiv" 2 "Funktion_ausgeloest" 3 "Funktion_deaktiviert" ;
VAL_ 2549088319 KN_TSG_HBFS_DiagPfad 0 "aktiv" 1 "inaktiv" ;
VAL_ 2549088319 TSG_HBFS_KD_Fehler 0 "Kein KD_Fehler" 1 "KD_Fehler" ;
VAL_ 2549088318 TSG_HFS_KompSchutz 0 "inaktiv" 1 "aktiv" ;
VAL_ 2549088318 TSG_HFS_Abschaltstufe 0 "keine_Einschraenkung" 1 "Funktionseinschraenkung" ;
VAL_ 2549088318 TSG_HFS_Transport_Mode 0 "keine_Einschraenkung" 1 "Funktionseinschraenkung" ;
VAL_ 2549088318 TSG_HFS_Nachlauftyp 0 "Komm_bei_KL15_EIN" 1 "Komm_nach_KL15_AUS" 2 "Komm_bei_KL15_AUS" ;
VAL_ 2549088318 KN_TSG_HFS_ECUKnockOutTimer 63 "ECUKnockOut_deaktiviert" ;
VAL_ 2549088318 KN_TSG_HFS_BusKnockOut 0 "Funktion_nicht_ausgeloest" 1 "Veto_aktiv" 2 "Funktion_ausgeloest" 3 "Funktion_deaktiviert" ;
VAL_ 2549088318 KN_TSG_HFS_BusKnockOutTimer 255 "BusKnockOut_deaktiviert" ;
VAL_ 2549088318 NM_TSG_HFS_Wakeup 0 "Peripherie_Wakeup_Ursache_nicht_bekannt" 1 "Bus_Wakeup" 2 "KL15_HW" ;
VAL_ 2549088318 KN_TSG_HFS_ECUKnockOut 0 "Funktion_nicht_ausgeloest" 1 "Veto_war_aktiv" 2 "Funktion_ausgeloest" 3 "Funktion_deaktiviert" ;
VAL_ 2549088318 KN_TSG_HFS_DiagPfad 0 "aktiv" 1 "inaktiv" ;
VAL_ 2549088318 TSG_HFS_KD_Fehler 0 "Kein_KD_Fehler" 1 "KD_Fehler" ;
VAL_ 2549088421 WLC1_KompSchutz 0 "inaktiv" 1 "aktiv" ;
VAL_ 2549088421 WLC1_Abschaltstufe 0 "keine_Einschraenkung" 1 "Funktionseinschraenkung" ;
VAL_ 2549088421 WLC1_Transport_Mode 0 "keine_Einschraenkung" 1 "Funktionseinschraenkung" ;
VAL_ 2549088421 WLC1_Nachlauftyp 0 "Komm_bei_KL15_EIN" 1 "Komm_nach_KL15_AUS" 2 "Komm_bei_KL15_AUS" ;
VAL_ 2549088421 KN_WLC1_ECUKnockOutTimer 63 "ECUKnockOut_deaktiviert" ;
VAL_ 2549088421 KN_WLC1_BusKnockOut 0 "Funktion_nicht_ausgeloest" 1 "Veto_aktiv" 2 "Funktion_ausgeloest" 3 "Funktion_deaktiviert" ;
VAL_ 2549088421 KN_WLC1_BusKnockOutTimer 255 "BusKnockOut_deaktiviert" ;
VAL_ 2549088421 NM_WLC1_Wakeup 0 "Peripherie_Wakeup__Ursache_nicht_bekannt" 1 "Bus_Wakeup" 2 "KL15_HW" ;
VAL_ 2549088421 KN_WLC1_ECUKnockOut 0 "Funktion_nicht_ausgeloest" 1 "Veto_war_aktiv" 2 "Funktion_ausgeloest" 3 "Funktion_deaktiviert" ;
VAL_ 2549088421 KN_WLC1_DiagPfad 0 "aktiv" 1 "inaktiv" ;
VAL_ 2549088421 WLC1_KD_Fehler 0 "Kein KD_Fehler" 1 "KD_Fehler" ;
VAL_ 779 KBI_ABS_Lampe 0 "ABS Lampe aus" 1 "ABS Lampe ein" ;
VAL_ 779 KBI_ESP_Lampe 0 "ESP Lampe aus" 1 "ESP Lampe ein" ;
VAL_ 779 KBI_BKL_Lampe 0 "BKL aus" 1 "BKL ein" ;
VAL_ 779 KBI_Airbag_Lampe 0 "Airbag Lampe aus" 1 "Airbag Lampe ein" ;
VAL_ 779 KBI_SILA_gueltig 0 "ungueltig" 1 "gueltig" ;
VAL_ 779 KBI_Vorglueh_System_Lampe 0 "Lampe aus" 1 "Lampe ein" ;
VAL_ 779 KBI_NV_in_Anzeige 0 "NV_nicht_in_Anzeige" 1 "NV_in_Anzeige" ;
VAL_ 779 KBI_Anzeigestatus_ACC 0 "keine_ACC_Anzeige" 1 "ACC_Anzeige_aktiv" ;
VAL_ 779 KBI_Anzeigestatus_GRA 0 "nicht_vorhanden" 1 "Anzeigemoeglichkeit_vorhanden" 2 "reserviert" 3 "Fehler" ;
VAL_ 779 KBI_Oeldruck_Schalter 0 "offen____p_kleiner_pnenn" 1 "geschlossen____p_groessergleich_pnenn" ;
VAL_ 779 KBI_Tankwarnung 0 "Lampe aus" 1 "Lampe ein" ;
VAL_ 779 KBI_MFA_v_Einheit_01 0 "kmh" 1 "mph" ;
VAL_ 779 KBI_im_Stellgliedtest 0 "kein Stellgliedtest" 1 "Kombi im Stellgliedtest" ;
VAL_ 779 KBI_Anzeigefehler_LDW 0 "nicht vorhanden bzw. unterstützt" 1 "Anzeige iO" 2 "Anzeigefehler" 3 "nicht definiert" ;
VAL_ 779 KBI_Tankwarnung_ungueltig 0 "KBI_Tankwarnung_gueltig" 1 "KBI_Tankwarnung_ungueltig" ;
VAL_ 779 KBI_Oeldruckwarnung 0 "inaktiv" 1 "aktiv" ;
VAL_ 779 KBI_Handbremse 0 "nicht_angezogen" 1 "angezogen" ;
VAL_ 779 KBI_PLA_in_Anzeige 0 "PLA_nicht_in_Anzeige" 1 "PLA_in_Anzeige" ;
VAL_ 779 KBI_Anzeigefehler_NV 0 "kein_Anzeigefehler" 1 "Anzeigefehler" ;
VAL_ 779 KBI_Anzeigestatus_LIM 0 "nicht_vorhanden" 1 "Anzeigemoeglichkeit_vorhanden" 2 "reserviert" 3 "Fehler" ;
VAL_ 779 KBI_ARA_in_Anzeige 0 "ARA nicht in Anzeige" 1 "ARA in Anzeige" ;
VAL_ 779 KBI_Taster_Lift 0 "nicht_betaetigt" 1 "betaetigt" ;
VAL_ 779 KBI_Taster_Fahrwerk 0 "nicht_betaetigt" 1 "betaetigt" ;
VAL_ 779 KBI_Audioabsenkung_MIB 0 "keine_Audio_Absenkung" 1 "Audio_Absenkung_Stufe_1" 2 "Audio_Absenkung_Stufe_2" 3 "Audio_Absenkung_Stufe_3" ;
VAL_ 779 KBI_Bestaetigung_ESP_Off 0 "ESP_off_nicht_quittiert" 1 "ESP_off_quittiert" 2 "Abbruch" ;
VAL_ 779 KBI_Anzeigestatus_RHP 0 "nicht_unterstuetzt_oder_Startup" 1 "Anzeige iO" 2 "Anzeigefehler" 3 "nicht definiert" ;
VAL_ 779 KBI_Konsistenz_ACC 0 "ACC Botschaft konsistent" 1 "ACC Botschaft inkonsistent" ;
VAL_ 779 KBI_Fehler_Anzeige_ACC 0 " iO" 1 "Anzeigefehler ACC" ;
VAL_ 779 KBI_Anzeigefehler_SWA 0 "nicht vorhanden bzw. unterstützt" 1 "Anzeige iO" 2 "Anzeigefehler" 3 "nicht definiert" ;
VAL_ 779 KBI_Systemstatus 0 "KBI_IO" 1 "KBI_System_Failure" ;
VAL_ 1719 KBI_Kilometerstand 1048574 "Init" 1048575 "Fehler" ;
VAL_ 1719 KBI_Standzeit_02 131069 "nicht_verfuegbar" 131070 "Init" 131071 "Fehler" ;
VAL_ 1719 KBI_Reserve_Warnung_Sek 0 "Keine_Warnung" 1 "Sekundaere_Reservewarnung" ;
VAL_ 1719 KBI_RDK_Kalibrier_Anf 0 "keine_Kalibrieranforderung" 1 "Kalibrieranforderung" ;
VAL_ 1719 KBI_Inhalt_Tank 126 "Init" 127 "Fehler" ;
VAL_ 1719 KBI_FStatus_Tank 0 "Tankfüllstand i.O." 1 "Tankfüllstand n.i.O" ;
VAL_ 1719 KBI_aktive_Laengsfunktion_02 0 "Init" 1 "Speedlimiter" 2 "GRA_oder_ACC" 3 "PACCh" 4 "HDC" 5 "p_GRA" 6 "p_Lim" 7 "ACC_im_GRA_Modus" 8 "Travel_Assist" 9 "RHP" ;
VAL_ 1719 KBI_FoD_PopUP_Quittiert 0 "nicht_quittiert" 1 "Meldung_quittiert" ;
VAL_ 1719 KBI_GRA_im_ACC 0 "GRA_im_ACC_nicht_ausgewaehlt" 1 "GRA_im_ACC_ausgewaehlt" ;
VAL_ 1719 KBI_Oelwechsel_durchgefuehrt 0 "Oelwechsel_nicht_durchgefuehrt" 1 "Oelwechsel_durchgefuehrt" ;
VAL_ 1719 KBI_QBit_Aussen_Temp_gef 0 "gueltiger_Wert" 1 "Ersatz_Init_oder_Fehlerwert" ;
VAL_ 1719 KBI_Aussen_Temp_gef 253 "nicht verbaut" 254 "Init" 255 "Fehler" ;
VAL_ 1720 KBI_Variante_USA 0 "keine USA-Variante" 1 "USA-Variante" ;
VAL_ 1720 KBI_Variante 0 "Zeiger Kombiinstrument" 1 "Volldisplay Kombiinstrument" ;
VAL_ 1720 KBI_GAP_Warn_Zeit_abgelaufen 0 "Zaehler_nicht_abgelaufen" 1 "Zaehler_abgelaufen" ;
VAL_ 1720 KBI_Quittierung_Naesse 0 "nicht_quittiert" 1 "quittiert" ;
VAL_ 1720 KBI_BCmE_aktiv 0 "Anzeige_nicht_aktiv" 1 "Anzeige_aktiv" ;
VAL_ 1720 KBI_Sparhinweis_quittiert 0 "nicht_quittiert" 1 "quittiert" ;
VAL_ 1720 KBI_Tankfuellstand_Prozent 126 "Init" 127 "Fehler" ;
VAL_ 1720 KBI_Nachtanken_erkannt 0 "Geberbetrieb" 1 "Nachtankmodus" ;
VAL_ 1720 KBI_Tankinhalt_hochaufl 16382 "Init" 16383 "Fehler" ;
VAL_ 1720 KBI_Max_Tankinhalt 254 "Init" 255 "Fehler" ;
VAL_ 1720 KBI_Quittierung_cAQP 0 "nicht_quittiert" 1 "quittiert" ;
VAL_ 2527679639 KBI_Weg_Zaehler_F 0 "kein Fehler" 1 "Fehler" ;
VAL_ 2527679639 KBI_Anzeige_ID_quittiert 0 "Init" ;
VAL_ 2527679639 KBI_Min_Tankinhalt 126 "Init" 127 "Fehler" ;
VAL_ 2527679639 KBI_Jokerkey 0 "nicht_betaetigt" 1 "betaetigt" ;
VAL_ 2527679639 KBI_RS_Druck_uebernehmen 0 " Druck für Rundstreckenmodue nicht uebernehmen" 1 " Druck für Rundstreckenmodus uebernehmen" ;
VAL_ 2527679639 KBI_RS_Druckauswahl_Aktiv 0 "inaktiv" 1 "aktiv" ;
VAL_ 2527679639 KBI_RS_Mode_fortsetzen 0 "Rundstreckenmodus_nicht_fortsetzen" 1 "Rundstreckenmodus_fortsetzen" ;
VAL_ 2527679639 KBI_Rundstreckenmodus 0 "nicht_angefordert" 1 "angefordert" ;
VAL_ 2527679639 AuthTime_Trigger_Distribution 0 "inaktiv" 1 "aktiv" ;
VAL_ 2527679639 KBI_FoD_VirtualCockpitPlus_State 0 "Init" 1 "locked" 2 "unlocked" ;
VAL_ 1614 KBI_HUD_Data_01 0 "Init" ;
VAL_ 1614 KBI_HUD_Data_02 0 "Init" ;
VAL_ 1614 KBI_HUD_Data_03 0 "Init" ;
VAL_ 1614 KBI_HUD_Data_04 0 "Init" ;
VAL_ 1614 KBI_HUD_Data_05 0 "Init" ;
VAL_ 1614 KBI_HUD_Data_06 0 "Init" ;
VAL_ 1614 KBI_HUD_Data_07 0 "Init" ;
VAL_ 1614 KBI_HUD_Data_08 0 "Init" ;
VAL_ 1387 LCM_TFL_Fehler_L 0 "kein_Fehler" 1 "Fehler" ;
VAL_ 1387 LCM_Sonstiger_Fehler_L 0 "kein_Fehler" 1 "Fehler" ;
VAL_ 1387 LCM_SM_Fehler_L 0 "kein_Fehler" 1 "Fehler" ;
VAL_ 1387 LCM_Shutter_Fehler_L 0 "kein_Fehler" 1 "Fehler" ;
VAL_ 1387 LCM_PO_Fehler_L 0 "kein_Fehler" 1 "Fehler" ;
VAL_ 1387 LCM_Blinker_Fehler_L 0 "kein_Fehler" 1 "Fehler" ;
VAL_ 1387 LCM_LWR_L_allg_Fehler 0 "kein_Fehler" 1 "Fehler" ;
VAL_ 1387 LCM_LWR_L_defekt_Fehler 0 "kein_Fehler" 1 "Fehler" ;
VAL_ 1387 LCM_Datensatz_Fehler_L 0 "kein_Fehler" 1 "Fehler" ;
VAL_ 1387 LCM_DKL_L_defekt_Fehler 0 "kein_Fehler" 1 "Fehler" ;
VAL_ 1387 LCM_GLW_L_defekt_Fehler 0 "kein_Fehler" 1 "Fehler" ;
VAL_ 1387 LCM_SKL_L_defekt_Fehler 0 "kein_Fehler" 1 "Fehler" ;
VAL_ 1388 LCM_TFL_Fehler_R 0 "kein_Fehler" 1 "Fehler" ;
VAL_ 1388 LCM_Sonstiger_Fehler_R 0 "kein_Fehler" 1 "Fehler" ;
VAL_ 1388 LCM_SM_Fehler_R 0 "kein_Fehler" 1 "Fehler" ;
VAL_ 1388 LCM_Shutter_Fehler_R 0 "kein_Fehler" 1 "Fehler" ;
VAL_ 1388 LCM_PO_Fehler_R 0 "kein_Fehler" 1 "Fehler" ;
VAL_ 1388 LCM_Blinker_Fehler_R 0 "kein_Fehler" 1 "Fehler" ;
VAL_ 1388 LCM_LWR_R_allg_Fehler 0 "kein_Fehler" 1 "Fehler" ;
VAL_ 1388 LCM_LWR_R_defekt_Fehler 0 "kein_Fehler" 1 "Fehler" ;
VAL_ 1388 LCM_Datensatz_Fehler_R 0 "kein_Fehler" 1 "Fehler" ;
VAL_ 1388 LCM_DKL_R_defekt_Fehler 0 "kein_Fehler" 1 "Fehler" ;
VAL_ 1388 LCM_GLW_R_defekt_Fehler 0 "kein_Fehler" 1 "Fehler" ;
VAL_ 1388 LCM_SKL_R_defekt_Fehler 0 "kein_Fehler" 1 "Fehler" ;
VAL_ 403 LCM_TFL_L_Anf 0 "TFL_aus" 1 "TFL_an" ;
VAL_ 403 LCM_TFL_R_Anf 0 "TFL_aus" 1 "TFL_an" ;
VAL_ 403 LCM_Abschaltung_Vbat_L_Anf 0 "default" 1 "Anfrage_LCM_Abschaltung" ;
VAL_ 403 LCM_Abschaltung_Vbat_R_Anf 0 "default" 1 "Anfrage_LCM_Abschaltung" ;
VAL_ 403 LCM_Blinker_L_Anf 0 "Blinker_aus" 1 "Blinker_an" ;
VAL_ 403 LCM_Blinker_R_Anf 0 "Blinker_aus" 1 "Blinker_an" ;
VAL_ 403 LCM_Blinkerzyklus_L 0 "Blinkzyklus_inaktiv" 1 "Blinkzyklus_aktiv" ;
VAL_ 403 LCM_Blinkerzyklus_R 0 "Blinkzyklus_inaktiv" 1 "Blinkzyklus_aktiv" ;
VAL_ 403 LCM_Sh_L_Anf 0 "Shutter_aus" 1 "Shutter_an" ;
VAL_ 403 LCM_Sh_R_Anf 0 "Shutter_aus" 1 "Shutter_an" ;
VAL_ 403 LCM_SM_L_Anf 0 "Sidemarker_aus" 1 "Sidemarker_an" ;
VAL_ 403 LCM_SM_R_Anf 0 "Sidemarker_aus" 1 "Sidemarker_an" ;
VAL_ 403 LCM_univ_1_L_Anf 0 "Ausgang_aus" 1 "Ausgang_an" ;
VAL_ 403 LCM_univ_1_R_Anf 0 "Ausgang_aus" 1 "Ausgang_an" ;
VAL_ 403 LCM_PO_L_Anf 0 "PO_aus" 1 "PO_an" ;
VAL_ 403 LCM_PO_R_Anf 0 "PO_aus" 1 "PO_an" ;
VAL_ 403 LCM_PL_L_Anf 0 "PL_aus" 1 "PL_an" ;
VAL_ 403 LCM_PL_R_Anf 0 "PL_aus" 1 "PL_an" ;
VAL_ 403 LCM_Leistungsreduzierung_Anf 0 "Init" 1 "Leistungsreduz_Stufe_1" 2 "Leistungsreduz_Stufe_2" 3 "Leistungsreduz_Stufe_3" ;
VAL_ 403 BCM1_FoD_Sperrung_AnimTFL 0 "Freigabe_Anim_TFL" 1 "Sperrung_Anim_TFL" ;
VAL_ 403 LCM_Blinkerwischen_Anf 0 "Blinker_Wischen_aus" 1 "Blinker_Wischen_ein" ;
VAL_ 403 LCM_Animiertes_TFL_Anf 0 "Animation_deaktiv" 1 "Animation_aktiv" ;
VAL_ 403 LCM_Signaturlicht_Anf 0 "Signaturlicht_aus" 1 "Signaturlicht_ein" ;
VAL_ 403 LCM_ECE_SAE_Umschaltung_Anf 0 "Anforderung_ECE" 1 "Anforderung_SAE" ;
VAL_ 403 BM_Autobahn 0 "inaktiv" 1 "aktiv" ;
VAL_ 403 BM_ZV_auf 0 "inaktiv" 1 "aktiv" ;
VAL_ 403 BM_ZV_zu 0 "inaktiv" 1 "aktiv" ;
VAL_ 403 BCM1_CH_aktiv 0 "Inaktiv" 1 "Aktiv" ;
VAL_ 403 BCM1_LH_aktiv 0 "Inaktiv" 1 "Aktiv" ;
VAL_ 403 LCM_TFL_Signatur_Anf 0 "Init" 1 "Signatur_01" 2 "Signatur_02" 3 "Signatur_03" 4 "Signatur_04" 5 "Signatur_05" 6 "Signatur_06" 7 "Signatur_07" 8 "Signatur_08" 9 "Signatur_09" 10 "Signatur_10" 11 "Signatur_11" 12 "Signatur_12" 13 "Signatur_13" 14 "Signatur_14" 15 "Signatur_15" ;
VAL_ 403 LCM_Designlicht_4 0 "Signaturlicht_aus" 1 "Signaturlicht_ein" ;
VAL_ 403 LCM_Designlicht_5 0 "Signaturlicht_aus" 1 "Signaturlicht_ein" ;
VAL_ 403 AMBEX_CH_aktiv 0 "nicht_aktiv" 1 "aktiv" ;
VAL_ 403 AMBEX_CH_Trigger 0 "nicht_aktiv" 1 "aktiv" ;
VAL_ 403 AMBEX_LH_aktiv 0 "nicht_aktiv" 1 "aktiv" ;
VAL_ 403 AMBEX_LH_Trigger 0 "nicht_aktiv" 1 "aktiv" ;
VAL_ 411 LCM_Ausgangsleistungsred_L_Sta 0 "Inaktiv" 1 "Aktiv" ;
VAL_ 411 LCM_Abschaltbestaetigung_L 0 "Init_Default" 1 "Abschaltung_nicht_moeglich" 2 "Abschaltung_moeglich" 3 "Fehler" ;
VAL_ 411 LCM_Blinker_L_Sta 0 "Blinker_aus" 1 "Blinker_an" ;
VAL_ 411 LCM_PL_L_Sta 0 "PL_links_aus" 1 "PL_links_an" ;
VAL_ 411 LCM_PO_L_Sta 0 "PO_links_aus" 1 "PO_links_an" ;
VAL_ 411 LCM_Sh_L_Sta 0 "Shutter_links_aus" 1 "Shutter_links_an" ;
VAL_ 411 LCM_SM_L_Sta 0 "Sidemarker_aus" 1 "Sidemarker_an" ;
VAL_ 411 LCM_TFL_L_Sta 0 "TFL_links_aus" 1 "TFL_links_an" ;
VAL_ 411 LCM_univ_1_L_Sta 0 "Ausgang_links_aus" 1 "Ausgang_links_an" ;
VAL_ 411 LMS_DMD_LED_Temp_L 255 "Init" ;
VAL_ 413 LCM_Ausgangsleistungsred_R_Sta 0 "Inaktiv" 1 "Aktiv" ;
VAL_ 413 LCM_Abschaltbestaetigung_R 0 "Init_Default" 1 "Abschaltung_nicht_moeglich" 2 "Abschaltung_moeglich" 3 "Fehler" ;
VAL_ 413 LCM_Blinker_R_Sta 0 "Blinker_aus" 1 "Blinker_an" ;
VAL_ 413 LCM_PL_R_Sta 0 "PL_rechts_aus" 1 "PL_rechts_an" ;
VAL_ 413 LCM_PO_R_Sta 0 "PO_rechts_aus" 1 "PO_rechts_an" ;
VAL_ 413 LCM_Sh_R_Sta 0 "Shutter_rechts_aus" 1 "Shutter_rechts_an" ;
VAL_ 413 LCM_SM_R_Sta 0 "Sidemarker_aus" 1 "Sidemarker_an" ;
VAL_ 413 LCM_TFL_R_Sta 0 "TFL_rechts_aus" 1 "TFL_rechts_an" ;
VAL_ 413 LCM_univ_1_R_Sta 0 "Ausgang_rechts_aus" 1 "Ausgang_rechts_an" ;
VAL_ 413 LMS_DMD_LED_Temp_R 255 "Init" ;
VAL_ 2527679510 LED_L_Abbiegel_Def 0 "kein_Fehler" 1 "Fehler" ;
VAL_ 2527679510 LED_L_Abblendl_Def 0 "kein_Fehler" 1 "Fehler" ;
VAL_ 2527679510 LED_L_Allg_Elektr_Def 0 "kein_Fehler" 1 "Fehler" ;
VAL_ 2527679510 LED_L_Fernl_Def 0 "kein_Fehler" 1 "Fehler" ;
VAL_ 2527679510 LED_L_Zus_Fernl_LH_Def 0 "iO" 1 "defekt" ;
VAL_ 2527679510 LED_L_Laser_Def 0 "iO" 1 "defekt" ;
VAL_ 2527679510 LED_L_Laser_Stoerung 0 "iO" 1 "defekt" ;
VAL_ 2527679511 LED_R_Abbiegel_Def 0 "kein_Fehler" 1 "Fehler" ;
VAL_ 2527679511 LED_R_Abblendl_Def 0 "kein_Fehler" 1 "Fehler" ;
VAL_ 2527679511 LED_R_Allg_Elektr_Def 0 "kein_Fehler" 1 "Fehler" ;
VAL_ 2527679511 LED_R_Fernl_Def 0 "kein_Fehler" 1 "Fehler" ;
VAL_ 2527679511 LED_R_Zus_Fernl_LH_Def 0 "iO" 1 "defekt" ;
VAL_ 2527679511 LED_R_Laser_Def 0 "iO" 1 "defekt" ;
VAL_ 2527679511 LED_R_Laser_Stoerung 0 "iO" 1 "defekt" ;
VAL_ 981 BCM1_Kurvenlicht_links_Anf 0 "linkes_Kurvenlicht/Abbiegelicht_durch_BCM1_nicht_angesteuert" 1 "linkes_Kurven/Abbiegelicht_durch_BCM1_angesteuert" ;
VAL_ 981 BCM1_Kurvenlicht_rechts_Anf 0 "rechtes_Kurvenlicht/Abbiegelicht_durch_BCM1_nicht_angesteuert" 1 "rechtes_Kurvenlicht/Abbiegelicht_durch_BCM1_angesteuert" ;
VAL_ 981 BCM1_Standlicht_Anf 0 "Licht_nicht_angefordert" 1 "Licht ist einzuschalten" ;
VAL_ 981 BCM1_Abblendlicht_Anf 0 "Licht_nicht_angefordert" 1 "Licht ist einzuschalten" ;
VAL_ 981 BCM1_Fernlicht_Anf 0 "Licht_nicht_angefordert" 1 "Licht ist einzuschalten" ;
VAL_ 981 BCM1_Nebellicht_Anf 0 "Licht_nicht_angefordert" 1 "Licht ist einzuschalten" ;
VAL_ 981 BCM1_Parklicht_li_Anf 0 "Licht_nicht_angefordert" 1 "Licht ist einzuschalten" ;
VAL_ 981 BCM1_Parklicht_re_Anf 0 "Licht_nicht_angefordert" 1 "Licht ist einzuschalten" ;
VAL_ 981 BCM1_Nebelschluss_Ahg_Anf 0 "Licht_nicht_angefordert" 1 "Licht ist einzuschalten" ;
VAL_ 981 BCM1_Nebelschluss_Fzg_Anf 0 "Licht_nicht_angefordert" 1 "Licht_ist_einzuschalten" ;
VAL_ 981 BCM1_Schlusslicht_Anf 0 "Licht_nicht_angefordert" 1 "Licht ist einzuschalten" ;
VAL_ 981 BCM_Rueckfahrlicht_Anf 0 "Licht_nicht_angefordert" 1 "Licht_angefordert" ;
VAL_ 981 BCM1_Signaturlicht_Anf 0 "Licht_nicht_angefordert" 1 "Licht_ist_einzuschalten" ;
VAL_ 981 BCM1_Umfeldleuchten_Anf 0 "Licht_nicht_angefordert" 1 "Licht_ist_einzuschalten" ;
VAL_ 981 BCM1_Tagfahrlicht_Anf 0 "Licht_nicht_angefordert" 1 "Licht ist einzuschalten" ;
VAL_ 981 BCM1_Regenlicht_Anf 0 "Licht_nicht_angefordert" 1 "Licht ist einzuschalten" ;
VAL_ 981 BCM1_Autobahnlicht_Anf 0 "Licht_nicht_angefordert" 1 "Licht ist einzuschalten" ;
VAL_ 981 BCM1_Touristen_Licht_Anf 0 "Licht_nicht_angefordert" 1 "Anforderung von Touristenlicht" ;
VAL_ 981 BCM1_CH_aktiv 0 "Inaktiv" 1 "Aktiv" ;
VAL_ 981 BCM1_LH_aktiv 0 "Inaktiv" 1 "Aktiv" ;
VAL_ 981 BCM1_Gleitende_Leuchtw_Anf 0 "Aus" 1 "Ein" ;
VAL_ 981 BCM1_GLW_Fernlicht_Anf 0 "Aus" 1 "Ein" ;
VAL_ 981 BCM1_Adaptive_Lichtvert_Anf 0 "Aus" 1 "Ein" ;
VAL_ 981 BCM1_Animationssperrung 0 "keine_Sperrung" 1 "Sperrung" ;
VAL_ 981 BCM1_CH_LH_aktiv 0 "Comming_Home_Bzw._Leaving_Home_nicht_aktiv" 1 "Comming Home bzw. Leaving Home aktiv" ;
VAL_ 981 BCM1_Allwetterlicht_Anf 0 "Licht_nicht_angefordert" 1 "Licht_ist_einzuschalten" ;
VAL_ 981 TFL_Matrix_Variante01_Anf 0 "nicht_angefordert" 1 "angefordert" ;
VAL_ 981 TFL_Matrix_Variante02_Anf 0 "nicht_angefordert" 1 "angefordert" ;
VAL_ 981 TFL_Matrix_Variante03_Anf 0 "nicht_angefordert" 1 "angefordert" ;
VAL_ 981 TFL_Matrix_Variante04_Anf 0 "nicht_angefordert" 1 "angefordert" ;
VAL_ 982 BCM2_Bremsl_durch_ECD_invers 0 "Bremslicht_durch_ECD_aktiv" 1 "Bremslicht_ist_aus" ;
VAL_ 982 BCM2_Bremsl_durch_ECD 0 "Bremslicht_ist_aus" 1 "Bremslicht_durch_ECD_aktiv" ;
VAL_ 982 LH_Aussenlicht_def 0 "OK" 1 "defekt" ;
VAL_ 982 LH_Standlicht_H_aktiv 1 "Standlicht hinten aktiv" ;
VAL_ 982 LH_Parklicht_HL_aktiv 0 "nicht aktiv" 1 "Parklicht hinten links aktiv" ;
VAL_ 982 LH_Parklicht_HR_aktiv 0 "nicht aktiv" 1 "Parklicht hinten rechts aktiv" ;
VAL_ 982 LH_Bremslicht_H_aktiv 1 "Bremslicht hinten aktiv" ;
VAL_ 982 LH_Nebelschluss_aktiv 0 "nicht aktiv" 1 "aktiv" ;
VAL_ 982 LH_Rueckfahrlicht_aktiv 0 "nicht_aktiv" 1 "aktiv" ;
VAL_ 982 LH_Blinker_HL_akt 1 "Blinker hinten links aktiv" ;
VAL_ 982 LH_Blinker_HR_akt 1 "Blinker hinten rechts aktiv" ;
VAL_ 982 LH_Blinker_li_def 0 "OK" 1 "Blinker hinten links defekt" ;
VAL_ 982 LH_Bremsl_li_def 0 "OK" 1 "mindestens ein Bremslicht hinten links defekt" ;
VAL_ 982 LH_Schlusslicht_li_def 0 "OK" 1 "mindestens ein Schlusslicht hinten links defekt" ;
VAL_ 982 LH_Rueckf_li_def 0 "OK" 1 "Rückfahrlicht hinten links defekt" ;
VAL_ 982 LH_Nebel_li_def 0 "OK" 1 "Nebelschlusslicht_hinten_links_defekt" ;
VAL_ 982 LH_Schluss_Brems_Nebel_li_def 0 "iO" 1 "defekt" ;
VAL_ 982 LH_Schluss_Brems_Nebel_re_def 0 "iO" 1 "defekt" ;
VAL_ 982 LH_Zusatzschlussl_def 0 "OK" 1 "mindestens_ein_Zusatzschlusslicht_defekt" ;
VAL_ 982 LH_Schluss_Brems_li_def 0 "OK" 1 "defekt" ;
VAL_ 982 LH_Schluss_Nebel_li_def 0 "OK" 1 "defekt" ;
VAL_ 982 LH_SL_BRL_BLK_li_def 0 "OK" 1 "defekt" ;
VAL_ 982 LH_Brems_Blk_li_def 0 "OK" 1 "defekt" ;
VAL_ 982 LH_Diag_Status_re_def 0 "OK" 1 "Aussenlict_Diagnose_Systemstoerung_rechts" ;
VAL_ 982 LH_Diag_Status_li_def 0 "OK" 1 "Aussenlicht_Diagnose_Systemstoerung_links" ;
VAL_ 982 LH_Diag_LED_li_def 0 "OK" 1 "Heckleuchte_links_defekt" ;
VAL_ 982 LH_Diag_LED_re_def 0 "OK" 1 "Heckleuchte_rechts_defekt" ;
VAL_ 982 LH_Blinker_re_def 0 "OK" 1 "Blinker hinten rechts defekt" ;
VAL_ 982 LH_Bremsl_re_def 0 "OK" 1 "mindestens ein Bremslicht hinten rechts defekt" ;
VAL_ 982 LH_Schlusslicht_re_def 0 "OK" 1 "mindestens_ein_Schlusslicht_hinten_rechts_defekt" ;
VAL_ 982 LH_Rueckf_re_def 0 "OK" 1 "Rückfahrlicht hinten rechts defekt" ;
VAL_ 982 LH_Nebel_re_def 0 "OK" 1 "Nebelschlusslicht hinten rechts defekt" ;
VAL_ 982 LH_Schluss_Brems_re_def 0 "OK" 1 "defekt" ;
VAL_ 982 LH_Schluss_Nebel_re_def 0 "OK" 1 "defekt" ;
VAL_ 982 LH_SL_BRL_BLK_re_def 0 "OK" 1 "defekt" ;
VAL_ 982 LH_Brems_Blk_re_def 0 "OK" 1 "defekt" ;
VAL_ 982 LH_Kennzl_def 0 "OK" 1 "Kennzeichenbeleuchtung hinten defekt" ;
VAL_ 982 LH_3_Bremsl_def 0 "OK" 1 "hochgesetzte  Bremsleuchte defekt" ;
VAL_ 982 LH_Nebel_mi_def 0 "OK" 1 " Nebelschlusslicht hinten Mitte defekt" ;
VAL_ 982 LH_Rueckf_mi_def 0 "OK" 1 "Rückfahllicht Mitte defekt" ;
VAL_ 982 LH_Bremsl_li_ges_def 0 "OK" 1 "Alle Bremslichter hinten links defekt" ;
VAL_ 982 LH_Bremsl_re_ges_def 0 "OK" 1 "Alle Bremslichter hinten rechts defekt" ;
VAL_ 1624 LV_Standlicht_Anzeige 0 "nicht aktiv" 1 "aktiv" ;
VAL_ 1624 LV_Abblendlicht_Anzeige 0 "inaktiv" 1 "aktiv" ;
VAL_ 1624 LV_Fernlicht_Anzeige 0 "nicht aktiv" 1 "aktiv" ;
VAL_ 1624 LV_Nebellicht_Anzeige 0 "nicht aktiv" 1 "aktiv" ;
VAL_ 1624 LV_Nebelschlusslicht_Anzeige 0 "nicht aktiv" 1 "aktiv" ;
VAL_ 1624 LV_Tagfahrlicht_Anzeige 0 "nicht aktiv" 1 "aktiv" ;
VAL_ 1624 LV_AFL_aktiv_Anzeige 0 "nicht aktiv" 1 "aktiv" ;
VAL_ 1624 LV_AFL_defekt 0 "OK" 1 "defekt" ;
VAL_ 1624 LV_Blinker_li_def 0 "OK" 1 "defekt" ;
VAL_ 1624 LV_Standlicht_li_def 0 "OK" 1 "defekt" ;
VAL_ 1624 LV_Abblendlicht_li_def 0 "OK" 1 "defekt" ;
VAL_ 1624 LV_Fernlicht_li_def 0 "OK" 1 "defekt" ;
VAL_ 1624 LV_Nebellicht_li_def 0 "OK" 1 "defekt" ;
VAL_ 1624 LV_Blk_li_Seite_def 0 "OK" 1 "defekt" ;
VAL_ 1624 LV_Tagfahrlicht_li_def 0 "OK" 1 "defekt" ;
VAL_ 1624 LV_FLA_aktiv_Anzeige 0 "aus" 1 "ein" ;
VAL_ 1624 LV_FLA_defekt 0 "i.O." 1 "FLA defekt" ;
VAL_ 1624 LV_FLA_Sensor_blockiert 0 "i.O." 1 "FLA-Sensor blockiert" ;
VAL_ 1624 LV_Blinker_re_def 0 "OK" 1 "defekt" ;
VAL_ 1624 LV_Standlicht_re_def 0 "OK" 1 "defekt" ;
VAL_ 1624 LV_Abblendlicht_re_def 0 "OK" 1 "defekt" ;
VAL_ 1624 LV_Fernlicht_re_def 0 "OK" 1 "defekt" ;
VAL_ 1624 LV_Nebellicht_re_def 0 "OK" 1 "defekt" ;
VAL_ 1624 LV_Blk_re_Seite_def 0 "OK" 1 "defekt" ;
VAL_ 1624 LV_Tagfahrlicht_re_def 0 "OK" 1 "defekt" ;
VAL_ 1624 LV_Aussenlicht_def 0 "OK" 1 "defekt" ;
VAL_ 1624 LV_Abblendlicht_TFL_li_def 0 "OK" 1 "defekt" ;
VAL_ 1624 LV_Nebellicht_TFL_li_def 0 "OK" 1 "defekt" ;
VAL_ 1624 LV_Standlicht_TFL_li_def 0 "OK" 1 "defekt" ;
VAL_ 1624 LV_Abblend_Fernlicht_li_def 0 "OK" 1 "defekt" ;
VAL_ 1624 LV_Abblendlicht_TFL_re_def 0 "OK" 1 "defekt" ;
VAL_ 1624 LV_Nebellicht_TFL_re_def 0 "OK" 1 "defekt" ;
VAL_ 1624 LV_Standlicht_TFL_re_def 0 "OK" 1 "defekt" ;
VAL_ 1624 LV_Abblend_Fernlicht_re_def 0 "OK" 1 "defekt" ;
VAL_ 1624 LV_Abbiegelicht_li_def 0 "OK" 1 "defekt" ;
VAL_ 1624 LV_Abbiegelicht_re_def 0 "OK" 1 "defekt" ;
VAL_ 1624 BCM1_Linksverkehr 0 "Rechtsverkehr" 1 "Linksverkehr" ;
VAL_ 1624 BCM1_Licht_Dunkelheit_aktiv 0 "inaktiv" 1 "aktiv" ;
VAL_ 1624 LV_LED_Scheinwerfer_li_def 0 "OK" 1 "defekt" ;
VAL_ 1624 LV_LED_Scheinwerfer_re_def 0 "OK" 1 "defekt" ;
VAL_ 1624 LV_Blinker_VL_aktiv 0 "inaktiv" 1 "aktiv" ;
VAL_ 1624 LV_Blinker_VR_aktiv 0 "inaktiv" 1 "aktiv" ;
VAL_ 1624 LV_MXB_Status_Anzeige 0 "MXB_aus" 1 "MXB_regelt" 2 "MXB_volles_Fernlicht" 3 "MXB_und_Laser_aktiv" ;
VAL_ 2527679633 LSH_Geblaese_aktiv 0 "Geblaese_inaktiv" 1 "Geblaese_aktiv" ;
VAL_ 2527679633 LSH_LED 0 "keine_Rueckmeldung" 1 "Rueckmeldung_in_Betrieb" ;
VAL_ 2527679633 LSH_Servicemode 0 "inaktiv" 1 "aktiv" ;
VAL_ 2527679633 LSH_Funk_aus 0 "kein_Funkbefehl_erhalten" 1 "Funkbefehl_erhalten" ;
VAL_ 2527679633 LSH_Funk_ein 0 "kein_Funkbefehl_erhalten" 1 "Funkbefehl_erhalten" ;
VAL_ 2527679633 LSH_Klappe_Status 0 "Init" 1 "Front" 2 "Heck" 3 "Front_u_Heck" 4 "misch_Front_u_Heck" ;
VAL_ 2527679633 LSH_Start_folgt 0 "kein_Start_folgt" 1 "Start_folgt" ;
VAL_ 2527679633 LSH_Heiztemp 254 "Init" 255 "Fehler" ;
VAL_ 2527679633 LSH_Empf_Heizstufe 0 "Init" 1 "Stufe_1" 2 "Stufe_2" 3 "Stufe_3" 4 "Stufe_4" 5 "Stufe_5" 6 "Stufe_6" 7 "Stufe_7" 8 "Stufe_8" 9 "Stufe_9" 10 "Stufe_10" 15 "Fehler" ;
VAL_ 2527679633 LSH_Texte 0 "keine_Anzeige" 1 "Batteriemanagementeinschraenkung" 2 "Kraftstoffmangel" 3 "interner_Systemfehler" 4 "Heizzeitueberschreitung" ;
VAL_ 2527679633 LSH_Waermeeintrag 510 "Init" 511 "Fehler" ;
VAL_ 2527679633 LSH_Ansaug_Fuell_1 254 "Init" 255 "Fehler" ;
VAL_ 2527679633 LSH_Ansaug_Fuell_2 254 "Init" 255 "Fehler" ;
VAL_ 917 AFS_Abbiegelicht_li_Anf 0 "Abbiegelicht_aus" 1 "Abbiegelicht_ein" ;
VAL_ 917 AFS_Abbiegelicht_re_Anf 0 "Abbiegelicht_aus" 1 "Abbiegelicht_ein" ;
VAL_ 917 AFS_Abbiegelicht_Dimm_Anf 0 "Dimmung_angefordert" 1 "keine_Dimmung" ;
VAL_ 917 AFS_Verfuegbarkeit_GLW 0 "GLW_nicht_verfuegbar" 1 "GLW_verfuegbar" ;
VAL_ 917 AFS_Status_adaptive_LV 0 "adaptive_Lichtverteilung_aus" 1 "adaptive_Lichtverteilung_an" ;
VAL_ 917 AFS_Fernlicht_li_defekt 0 "Fernlicht_in_Ordnung" 1 "Fernlicht_defekt" ;
VAL_ 917 AFS_Fernlicht_re_defekt 0 "Fernlicht_in_Ordnung" 1 "Fernlicht_defekt" ;
VAL_ 917 AFS_Fernlicht_Status 0 "Fernlicht_aus" 1 "Fernlicht_ein" ;
VAL_ 917 AFS_Lampe 0 "Aus" 1 "Ein" ;
VAL_ 917 LWR_Lampe 0 "LWR Fehlerlampe aus" 1 "LWR Fehlerlampe ein" ;
VAL_ 917 AFS_Fehlertext 0 "kein Text" 1 "AFS ohne Funktion" ;
VAL_ 917 AFS_LED_Blinkmode 0 "kein Blinkmode angefordert" 1 "Blinkmode angefordert" ;
VAL_ 917 LWR_Touristenmodus_aktiv 0 "Touristenmodus inaktiv" 1 "Touristenmodus aktiv" ;
VAL_ 917 AFS_Charisma_FahrPr 0 "keine_Funktion" 1 "Programm_1" 2 "Programm_2" 3 "Programm_3" 4 "Programm_4" 5 "Programm_5" 6 "Programm_6" 7 "Programm_7" 8 "Programm_8" 9 "Programm_9" 10 "Programm_10" 11 "Programm_11" 12 "Programm_12" 13 "Programm_13" 14 "Programm_14" 15 "Programm_15" ;
VAL_ 917 AFS_Charisma_Status 0 "Init" 1 "verfuegbar" 2 "nicht_verfuegbar" 3 "asynchron_durch_Fahrerwunsch" ;
VAL_ 917 AFS_Allwetterlicht 0 "Allwetterlicht_nicht_aktiv" 1 "Allwetterlicht_aktiv" ;
VAL_ 917 LWR_Touristenmodus_verbaut 0 "Touristenmodus_nicht_verbaut" 1 "Touristenmodus_verbaut" ;
VAL_ 917 AFS_adaptive_LV_verbaut 0 "adaptive_Lichtverteilung_nicht_verbaut" 1 "adaptive_Lichtverteilung_verbaut" ;
VAL_ 917 LWR_Reisemodus_Texte 0 "keine_Anzeige" 1 "Umschaltung_auf_Linksverkehr_aktiv" 2 "Umschaltung_auf_Rechtsverkehr_aktiv" ;
VAL_ 917 GLW_Sensor_blockiert 0 "Kamera_Sensor_nicht_blockiert" 1 "Kamera_Sensor_blockiert" ;
VAL_ 917 LWR_Pos_Schrittmotor 254 "Init" 255 "Fehler" ;
VAL_ 917 LWR_Hoehenwert_VL 254 "nicht_initialisiert" 255 "Fehler" ;
VAL_ 917 LWR_Hoehenwert_HL 254 "nicht_initialisiert" 255 "Fehler" ;
VAL_ 917 AFS_Ersatzlicht_Links 0 "keine Ersatzlichtfunktion links" 1 "Ersatzlichtfunktion links" ;
VAL_ 917 AFS_Ersatzlicht_Rechts 0 "keine Ersatzlichtfunktion rechts" 1 "Ersatzlichtfunktion rechts" ;
VAL_ 917 LWR_AFS_Grundeinstellung 0 "Grundeinstellung nicht erfolgt" 1 "Grundeinstellung erfolgt" ;
VAL_ 917 LWR_AFS_Parametrisierung 0 "Parametrisierung nicht erfolgt" 1 "Parametrisierung erfolgt" ;
VAL_ 917 LWR_Initialisierungslauf 0 "Initialisierungslauf nicht erfolgt" 1 "Initialisierungslauf erfolgt" ;
VAL_ 917 LWR_Sicherheitsposition 0 "Sicherheitsposition aus" 1 "Sicherheitsposition ein" ;
VAL_ 917 LWR_Modus 0 "LWR statisch" 1 "LWR dynamisch" ;
VAL_ 1153 ZR_LoGeWa_Event_Kombiwarnung 0 "Init" 1 "Unfall" 2 "Traktionsverlust" 3 "Panne" 4 "Sichtbehinderung" 5 "Aquaplaning" 6 "EEBL" 7 "SEF_stat" 8 "SEF_dyn_allgemein" 9 "SEF_dyn_vorne" 10 "SEF_dyn_hinten" 11 "SEF_dyn_links" 12 "SEF_dyn_rechts" 13 "Stauende" ;
VAL_ 1153 Nav_FoD_Status 0 "Init" 1 "Nav_permanently_available" 2 "FoD_Nav_not_activated" 3 "FoD_Nav_activated" 4 "R4N_Nav_not_activated" ;
VAL_ 1153 MIB_ASW_Diagnose 0 "ASW_Warnton_nicht_verfuegbar" 1 "ASW_Warnton_verfuegbar" ;
VAL_ 1153 ZR_Lichter_Tag 0 "Nacht" 1 "Tag" ;
VAL_ 1153 MIB_Tongenerator_PH_verfuegbar 0 "Tongenerator_nicht_verfuegbar" 1 "Tongenerator_vorne_verfuegbar" 2 "Tongenerator_hinten_verfuegbar" 3 "Tongenerator_gesamt_verfuegbar" 4 "Tongenerator_im_AMP" ;
VAL_ 1153 DSSS_Warning 0 "No_Warning" 1 "Red_traffic_light_guidance" 2 "Stop_sign_warning" 3 "Rear_end_collision_avoidance_warning" 4 "Intersection_collision_avoidance_warning_right" 5 "Intersection_collision_avoidance_warning_left" 6 "turn_right_collision_avoidance" 7 "turn_left_collision_avoidance" 8 "pedestrian_crossing_right" 9 "pedestrian_crossing_left" 10 "bicycle_collision_right" 11 "bicycle_collision_left" ;
VAL_ 1153 ZR_Kindersicherung_RSE 0 "inaktiv" 1 "aktiv" ;
VAL_ 1153 ZR_RSE_aktivieren 0 "inaktiv" 1 "aktiv" ;
VAL_ 1153 MMI_SDS_aktiv 0 "inaktiv" 1 "aktiv" ;
VAL_ 1153 MU_SecondDisplay 0 "Init" 1 "gueltige_Karte" 2 "ungueltiges_Signal" 3 "Nicht_Verbaut" ;
VAL_ 1153 MMI_Telefon_aktiv 0 "Telefongespraech_nicht_aktiv" 1 "Telefongespraech_aktiv" ;
VAL_ 1153 MMI_Gurt_Mic_ref 0 "Downlink_inaktiv" 1 "Downlink_aktiv" ;
VAL_ 1153 ZR_Sta_Inszenierung 0 "Init" 1 "Inszenierung_deaktiviert" 2 "Inszenierung_Start" 3 "Inszenierung_Stop" ;
VAL_ 1153 ZR_AppConnect_Zustand 0 "AppConnect_nicht_in_Anzeige" 1 "AppConnect_in_Anzeige" ;
VAL_ 1153 ZR_Parken_Sondermodus 0 "Init" 1 "Sondermodus_aktiv" 2 "Sondermodus_nicht_verfuegbar" 3 "WLAN_aus" 4 "WLAN_auscodiert" 15 "keine_WLAN_HW" ;
VAL_ 2527679860 MDK_Change_Polling_Mode 0 "Init" 1 "NormalMode" 2 "OwnerPairingMode" ;
VAL_ 2527679860 MDK_Function_State 0 "Init" 1 "MDK_aktiviert" 2 "MDK_deaktiviert" 3 "MDK_auskodiert" ;
VAL_ 1639 BFS_Fond_Bed_Ack 0 "nicht aktiviert" 1 "aktiviert" ;
VAL_ 1639 BFS_Lehne_nicht_verriegelt 0 "keine Anzeige" 1 "Lehne_nicht_verriegelt" ;
VAL_ 1639 BFS_Klapptisch_offen 0 "inaktiv" 1 "aktiv" ;
VAL_ 1639 BFS_Gurtbringer_Sperre 0 "Gurtzubringer_freigegeben" 1 "Gurtzubringer_gesperrt" ;
VAL_ 1639 BFS_Sitzsym_Fahrt_aktiv 0 "inaktiv" 1 "aktiv" ;
VAL_ 1639 BFS_Sitzfahrt_aktiv 0 "Init" 1 "Sitz in Bewegung" ;
VAL_ 1639 BFS_SLV_aktiv 0 "nicht_aktiv" 1 "Sitzlaengsverstellung aktiv" ;
VAL_ 1639 BFS_SHV_aktiv 0 "nicht_aktiv" 1 "Sitzhoehenverstellung aktiv" ;
VAL_ 1639 BFS_LNV_aktiv 0 "inaktiv" 1 "aktiv" ;
VAL_ 1639 BFS_SNV_aktiv 0 "nicht_aktiv" 1 "Sitzneigungsverstellung aktiv" ;
VAL_ 1639 BFS_KSV_aktiv 0 "nicht_aktiv" 1 "Kopfstuetzenverstellung aktiv" ;
VAL_ 1639 BFS_LKV_aktiv 0 "nicht_aktiv" 1 "aktiv" ;
VAL_ 1639 BFS_STV_aktiv 0 "inaktiv" 1 "Sitztiefeverstellung aktiv" ;
VAL_ 1639 BFS_LHV_aktiv 0 "inaktiv" 1 "aktiv" ;
VAL_ 1639 BFS_LWV_aktiv 0 "nicht_aktiv" 1 "aktiv" ;
VAL_ 1639 BFS_GHV_aktiv 0 "nicht_aktiv" 1 "Gurthoehe Verstellung aktiv" ;
VAL_ 1639 BFS_KSS_Fahrt_aktiv 0 "nicht_aktiv" 1 "Komfortseitensichtfahrt aktiv" ;
VAL_ 1639 BFS_MMB_lokal_Stop 0 "kein_Abbruch" 1 "lokaler_Abbruch" ;
VAL_ 1639 BFS_Ruhestellung_Status 0 "inakiv" 1 "Ruhestellung_aktiv" ;
VAL_ 1639 BFS_Seat_Locked 0 "nicht_gesperrt" 1 "gesperrt" ;
VAL_ 1639 BFS_MMB_storage 0 "keine Zuweisung" 1 "P1/FP1 Pos Zuweisung" 2 "P2/FP2 Pos Zuweisung" 3 "P3/FP3 Pos Zuweisung" 4 "P4/FP4 Pos Zuweisung an den im System aktiven Funkschlüssel/FPI ID über MMI" 5 "FS1" 6 "FS2" 7 "FS3" 8 "FS4" ;
VAL_ 1639 BFS_MMB_tipp 0 "kein_Tippbetrieb" 1 "Tippbetrieb" ;
VAL_ 1639 BFS_MMB_tast 0 "kein_Tastbetrieb" 1 "Tastbetrieb" ;
VAL_ 1639 BFS_MMB_store_LED_on 0 "LED_aus" 1 "LED_ein" ;
VAL_ 1639 BFS_MMB_storage_beep 0 "beep_aus" 1 "beep ein" ;
VAL_ 1639 BFS_MMB_store 0 "nicht speichern" 1 "speichern" ;
VAL_ 1639 BFS_MMB_glob_stop 0 "kein globaler Abbruch" 1 "globaler Abbruch" ;
VAL_ 1639 BFS_FSV_ausgeklappt 0 "FSV_nicht_ausgeklappt" 1 "FSV_ausgeklappt" ;
VAL_ 1639 BFS_Klappfunktion_Aktiv 0 "inaktiv" 1 "aktiv" ;
VAL_ 1639 BFS_Klappfunktion_Bed_Ack 0 "inaktiv" 1 "klappen" 2 "aufrichten" 3 "reserve" ;
VAL_ 1639 BFS_Klappfunktion_Beschraenkung 0 "inaktiv" 1 "aktiv" 2 "reserve" 3 "reserve" ;
VAL_ 1639 BFS_Klappfunktion_Status 0 "init" 1 "Status1" 2 "Status2" 3 "Status3" ;
